VERSION "HNNBNNNYNNNNNNNNNNNNNNNNNNNNNNNNNNNNNNNNNN/4/%%%/4/'%**4NNN///"

NS_ :

BS_:

BU_: BAP_Tester ELV Gateway_Max HUD Kombi

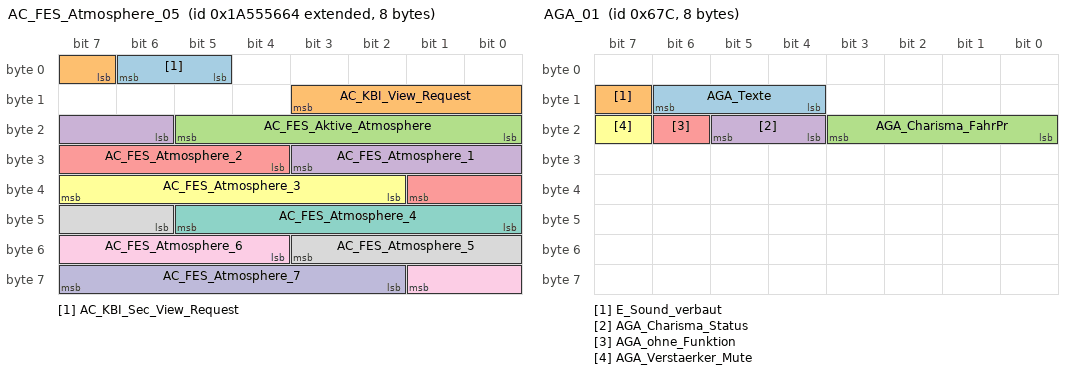
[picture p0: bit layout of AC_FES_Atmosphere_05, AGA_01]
BO_ 2589283940 AC_FES_Atmosphere_05: 8 Gateway_Max
 SG_ AC_KBI_Sec_View_Request : 5|2@1+ (1.0,0.0) [0.0|3] ""  Kombi
 SG_ AC_KBI_View_Request : 7|5@1+ (1.0,0.0) [0.0|31] ""  Kombi
 SG_ AC_FES_Aktive_Atmosphere : 16|6@1+ (1.0,0.0) [0.0|63] ""  Vector__XXX
 SG_ AC_FES_Atmosphere_1 : 22|6@1+ (1.0,0.0) [0.0|63] ""  Vector__XXX
 SG_ AC_FES_Atmosphere_2 : 28|6@1+ (1.0,0.0) [0.0|63] ""  Vector__XXX
 SG_ AC_FES_Atmosphere_3 : 34|6@1+ (1.0,0.0) [0.0|63] ""  Vector__XXX
 SG_ AC_FES_Atmosphere_4 : 40|6@1+ (1.0,0.0) [0.0|63] ""  Vector__XXX
 SG_ AC_FES_Atmosphere_5 : 46|6@1+ (1.0,0.0) [0.0|63] ""  Vector__XXX
 SG_ AC_FES_Atmosphere_6 : 52|6@1+ (1.0,0.0) [0.0|63] ""  Vector__XXX
 SG_ AC_FES_Atmosphere_7 : 58|6@1+ (1.0,0.0) [0.0|63] ""  Vector__XXX

BO_ 768 ACC_19: 48 Gateway_Max
 SG_ ACC_FzgStatus_Kamerafusion : 54|2@1+ (1.0,0.0) [0.0|3] ""  Kombi
 SG_ ACC_FzgStatus_Anfahrbereitschaft : 56|2@1+ (1.0,0.0) [0.0|3] ""  Kombi
 SG_ ACC_FzgStatus_Fehleranzeige : 58|3@1+ (1.0,0.0) [0.0|7] ""  Kombi
 SG_ ACC_ENG_Texte_02 : 61|3@1+ (1.0,0.0) [0.0|7] ""  Kombi
 SG_ ACC_Tempolimit : 64|5@1+ (1.0,0.0) [0.0|31] ""  HUD,Kombi
 SG_ ACC_Wunschgeschw_Farbe : 69|1@1+ (1.0,0.0) [0.0|1] ""  Vector__XXX
 SG_ ACC_Warnung_Verkehrszeichen_1 : 70|1@1+ (1.0,0.0) [0.0|1] ""  HUD,Kombi
 SG_ ACA_Querfuehrung : 71|2@1+ (1.0,0.0) [0.0|3] ""  HUD,Kombi
 SG_ ACC_Wunschgeschw_Farbe_02 : 73|2@1+ (1.0,0.0) [0.0|3] ""  Kombi
 SG_ ACC_Regelung_AIO : 75|1@1+ (1.0,0.0) [0.0|1] ""  Vector__XXX
 SG_ ACC_Wunschgeschw_02 : 76|10@1+ (0.32,0) [0.00|327.04] "Unit_KiloMeterPerHour"  HUD,Kombi
 SG_ ACC_Abstandsindex_02 : 86|10@1+ (1,0) [1|1021] ""  HUD,Kombi
 SG_ ACC_Display_Prio : 96|2@1+ (1.0,0.0) [0.0|3] ""  Kombi
 SG_ ACC_rel_Objekt_Zusatzanz : 98|2@1+ (1.0,0.0) [0.0|3] ""  Kombi
 SG_ ACC_Gesetzte_Zeitluecke : 101|3@1+ (1.0,0.0) [0.0|7] ""  HUD,Kombi
 SG_ ACC_Optischer_Fahrerhinweis : 104|1@1+ (1.0,0.0) [0.0|1] ""  HUD,Kombi
 SG_ ACC_Warnhinweis : 105|1@1+ (1.0,0.0) [0.0|1] ""  HUD,Kombi
 SG_ ACC_EGO_Fahrzeug : 106|3@1+ (1.0,0.0) [0.0|7] ""  HUD,Kombi
 SG_ ACC_Relevantes_Objekt_02 : 109|2@1+ (1.0,0.0) [0.0|3] ""  HUD,Kombi
 SG_ ACC_Wunschgeschw_erreicht : 112|1@1+ (1.0,0.0) [0.0|1] ""  Vector__XXX
 SG_ ACC_Anzeige_Zeitluecke : 113|1@1+ (1.0,0.0) [0.0|1] ""  HUD,Kombi
 SG_ ACC_Texte_Primaeranz_03 : 114|6@1+ (1.0,0.0) [0.0|63] ""  HUD,Kombi
 SG_ ACC_Texte_Zusatzanz_03 : 120|6@1+ (1.0,0.0) [0.0|63] ""  HUD,Kombi
 SG_ STA_Primaeranz : 126|2@1+ (1.0,0.0) [0.0|3] ""  Vector__XXX
 SG_ ACC_Regelgeschw : 140|10@1+ (0.32,0) [0.00|327.04] "Unit_KiloMeterPerHour"  HUD,Kombi
 SG_ ACC_Einheit_maxSetzgeschw : 150|1@1+ (1.0,0.0) [0.0|1] ""  Kombi
 SG_ ACC_maxSetzgeschw : 151|9@1+ (1,0) [0|510] ""  Kombi
 SG_ ACC_minRegelgeschw : 160|8@1+ (0.32,0) [0.00|81.28] "Unit_KiloMeterPerHour"  Vector__XXX
 SG_ ACC_maxRegelgeschw : 168|8@1+ (0.32,0) [0.00|81.28] "Unit_KiloMeterPerHour"  Vector__XXX
 SG_ ACC_Tempolimitassistent_02 : 176|3@1+ (1.0,0.0) [0.0|7] ""  Vector__XXX
 SG_ ACC_Tempolimit_Einheit : 179|1@1+ (1.0,0.0) [0.0|1] ""  Kombi
 SG_ ACC_Kurvenassistent : 180|3@1+ (1.0,0.0) [0.0|7] ""  Vector__XXX
 SG_ ACC_Typ_Tachokranz : 183|1@1+ (1.0,0.0) [0.0|1] ""  Vector__XXX
 SG_ ACC_RUV : 184|2@1+ (1.0,0.0) [0.0|3] ""  HUD,Kombi
 SG_ ACC_Tachokranz : 186|1@1+ (1.0,0.0) [0.0|1] ""  Kombi
 SG_ ACC_Typ_Tachokranz_unten : 187|1@1+ (1.0,0.0) [0.0|1] ""  Kombi
 SG_ ACC_ENG_Texte : 188|2@1+ (1.0,0.0) [0.0|3] ""  Kombi
 SG_ ACC_Status_GRA_Modus : 190|2@1+ (1.0,0.0) [0.0|3] ""  HUD,Kombi
 SG_ ACA_Querfuehrung_Texte : 192|3@1+ (1.0,0.0) [0.0|7] ""  Kombi
 SG_ ACA_Hinweistexte : 195|3@1+ (1.0,0.0) [0.0|7] ""  Vector__XXX
 SG_ ACC_FoD_Status : 198|2@1+ (1.0,0.0) [0.0|3] ""  HUD,Kombi
 SG_ ACC_Texte_Abstandswarner : 200|2@1+ (1.0,0.0) [0.0|3] ""  Vector__XXX
 SG_ ACC_Vorz_Abstandswarner : 202|2@1+ (1.0,0.0) [0.0|3] ""  Vector__XXX
 SG_ ACC_Texte_Sekundaeranz : 204|4@1+ (1.0,0.0) [0.0|15] ""  Vector__XXX
 SG_ ACC_Status_Anzeige : 208|3@1+ (1.0,0.0) [0.0|7] ""  HUD,Kombi
 SG_ ACC_Akustik_03 : 211|3@1+ (1.0,0.0) [0.0|7] ""  Kombi
 SG_ ACC_Geschw_Zielfahrzeug : 214|10@1+ (0.32,0) [0.00|326.72] "Unit_KiloMeterPerHour"  Vector__XXX
 SG_ ACC_Texte_02 : 224|6@1+ (1.0,0.0) [0.0|63] ""  Kombi
 SG_ ACC_STA_Text : 230|1@1+ (1.0,0.0) [0.0|1] ""  Vector__XXX
 SG_ ACC_Status_Stauende : 231|1@1+ (1.0,0.0) [0.0|1] ""  Vector__XXX
 SG_ STA_Texte : 232|3@1+ (1.0,0.0) [0.0|7] ""  Vector__XXX
 SG_ AbstWarn_LRR_FAS_Fkt_Status : 235|2@1+ (1.0,0.0) [0.0|3] ""  Vector__XXX
 SG_ STA_Zusatzanz : 237|2@1+ (1.0,0.0) [0.0|3] ""  Vector__XXX
 SG_ FAS_Licht_Anf : 239|1@1+ (1.0,0.0) [0.0|1] ""  Vector__XXX
 SG_ ACC_Zeitluecke_Abstandswarner : 240|6@1+ (0.1,0) [0.0|6.0] "Unit_Secon"  Vector__XXX
 SG_ ACC_Abstand_Abstandswarner : 246|9@1+ (1,0) [0|508] ""  Vector__XXX
 SG_ ACC_Einheit_Abstandswarner : 255|1@1+ (1.0,0.0) [0.0|1] ""  Vector__XXX
 SG_ ACC_Texte_Sekundaeranz_03 : 256|5@1+ (1.0,0.0) [0.0|31] ""  HUD,Kombi
 SG_ ACC_Modus_Pop_Up : 262|3@1+ (1.0,0.0) [0.0|7] ""  Kombi
 SG_ ACC_Statusicon : 265|4@1+ (1.0,0.0) [0.0|15] ""  HUD,Kombi
 SG_ ACC_Anzeige_Objektregelung : 269|5@1+ (1.0,0.0) [0.0|31] ""  HUD,Kombi
 SG_ ACC_Anzeige_Maximalabstand : 274|7@1+ (2,0) [0|254] "Unit_Meter"  Kombi
 SG_ ACC_Typ_LNS : 281|3@1+ (1.0,0.0) [0.0|7] ""  HUD,Kombi
 SG_ ACC_Typ_RNS : 284|3@1+ (1.0,0.0) [0.0|7] ""  HUD,Kombi
 SG_ ACC_Typ_WZO : 287|3@1+ (1.0,0.0) [0.0|7] ""  HUD,Kombi
 SG_ ACC_Abstand_WZO : 290|10@1+ (0.2,0) [0.2|204.6] "Unit_Meter"  Kombi
 SG_ ACC_Abstand_RNS : 300|10@1+ (0.2,0) [0.2|204.6] "Unit_Meter"  Kombi
 SG_ ACC_Abstand_LNS : 310|10@1+ (0.2,0) [0.2|204.6] "Unit_Meter"  Kombi
 SG_ ACC_Texte_03 : 320|7@1+ (1.0,0.0) [0.0|127] ""  Kombi
 SG_ ACC_iBoost_Anzeige : 327|2@1+ (1.0,0.0) [0.0|3] ""  HUD,Kombi
 SG_ ACC_Texte_Sekundaeranz_02 : 329|5@1+ (1.0,0.0) [0.0|31] ""  Kombi
 SG_ ACC_Sollabstand_1 : 334|10@1+ (0.2,0) [0.2|204.6] "Unit_Meter"  Kombi
 SG_ ACC_Sollabstand_2 : 344|10@1+ (0.2,0) [0.2|204.6] "Unit_Meter"  Kombi
 SG_ ACC_Sollabstand_3 : 354|10@1+ (0.2,0) [0.2|204.6] "Unit_Meter"  Kombi
 SG_ ACC_Sollabstand_4 : 364|10@1+ (0.2,0) [0.2|204.6] "Unit_Meter"  Kombi
 SG_ ACC_Sollabstand_5 : 374|10@1+ (0.2,0) [0.2|204.6] "Unit_Meter"  Kombi

BO_ 859 ACC_Obj_01: 64 Gateway_Max
 SG_ ACC_Obj_01_ID : 12|8@1+ (1,0) [1|254] "Unit_None"  Vector__XXX
 SG_ ACC_Obj_01_ax_StdA : 20|6@1+ (0.125,0) [0.000|7.750] "Unit_MeterPerSeconSquar"  Vector__XXX
 SG_ ACC_Obj_01_ax_v : 26|8@1+ (0.125,-16) [-16.000|15.750] "Unit_MeterPerSeconSquar"  Vector__XXX
 SG_ ACC_Obj_01_dx_StdA : 34|7@1+ (0.0625,0) [0.0000|7.8750] "Unit_Meter"  Vector__XXX
 SG_ ACC_Obj_01_dx_v : 41|12@1+ (0.0625,0) [0.0000|255.8750] "Unit_Meter"  HUD
 SG_ ACC_Obj_01_dy_StdA : 53|7@1+ (0.0625,0) [0.0000|7.8750] "Unit_Meter"  Vector__XXX
 SG_ ACC_Obj_01_dy_v : 60|11@1+ (0.0625,-64) [-64.0000|63.8750] "Unit_Meter"  HUD
 SG_ ACC_Obj_01_vx_StdA : 71|5@1+ (0.25,0) [0.00|7.50] "Unit_MeterPerSecon"  Vector__XXX
 SG_ ACC_Obj_01_vx_v : 76|10@1+ (0.25,-128) [-128.00|127.50] "Unit_MeterPerSecon"  HUD
 SG_ ACC_Obj_01_Bew_Zustand : 86|2@1+ (1.0,0.0) [0.0|3] ""  Vector__XXX
 SG_ ACC_Obj_01_Fusion_ID_VD : 88|32@1+ (1,0) [1|4294967294] "Unit_Ohm"  Vector__XXX
 SG_ ACC_Obj_01_Fusion_ID_FER_VR : 120|8@1+ (1,0) [1|254] "Unit_None"  Vector__XXX
 SG_ ACC_Obj_01_Fusion_ID_FER_VL : 128|8@1+ (1,0) [1|254] "Unit_None"  Vector__XXX
 SG_ ACC_Obj_01_Alter : 136|12@1+ (1,0) [0|4094] "Unit_None"  Vector__XXX
 SG_ ACC_Obj_01_vxAbs_v : 148|12@1+ (0.0625,-128) [-128.0000|127.8750] "Unit_MeterPerSecon"  Vector__XXX
 SG_ ACC_Obj_01_vyAbs_v : 160|12@1+ (0.0625,-128) [-128.0000|127.8750] "Unit_MeterPerSecon"  Vector__XXX
 SG_ ACC_Obj_01_Bezugspunkt : 172|4@1+ (1.0,0.0) [0.0|15] ""  Vector__XXX
 SG_ ACC_Obj_01_Breite : 176|7@1+ (0.0625,0) [0.0000|7.8750] "Unit_Meter"  Vector__XXX
 SG_ ACC_Obj_01_SDFInfo_FER_VL : 183|1@1+ (1.0,0.0) [0.0|1] ""  Vector__XXX
 SG_ ACC_Obj_01_BreiteStdA : 184|7@1+ (0.0625,0) [0.0000|7.8750] "Unit_Meter"  Vector__XXX
 SG_ ACC_Obj_01_SDFInfo_FER_VR : 191|1@1+ (1.0,0.0) [0.0|1] ""  Vector__XXX
 SG_ ACC_Obj_01_Historie : 192|1@1+ (1.0,0.0) [0.0|1] ""  Vector__XXX
 SG_ ACC_Obj_01_SDFInfo_FR : 193|1@1+ (1.0,0.0) [0.0|1] ""  Vector__XXX
 SG_ ACC_Obj_01_SDFInfo_Kamera : 194|1@1+ (1.0,0.0) [0.0|1] ""  Vector__XXX
 SG_ ACC_Obj_01_vy_StdA : 195|5@1+ (0.25,0) [0.00|7.50] "Unit_MeterPerSecon"  Vector__XXX
 SG_ ACC_Obj_01_dz_v : 200|9@1+ (0.0625,-16) [-16.0000|15.8750] "Unit_Meter"  Vector__XXX
 SG_ ACC_Obj_01_dz_StdA : 209|7@1+ (0.0625,0) [0.0000|7.8750] "Unit_Meter"  Vector__XXX
 SG_ ACC_Obj_01_Laenge : 216|9@1+ (0.0625,0) [0.0000|31.8750] "Unit_Meter"  Vector__XXX
 SG_ ACC_Obj_01_LaengeStdA : 225|7@1+ (0.0625,0) [0.0000|7.8750] "Unit_Meter"  Vector__XXX
 SG_ ACC_Obj_01_GierWnkl : 232|9@1+ (0.0125,-3.2) [-3.2000|3.1750] "Unit_Radia"  Vector__XXX
 SG_ ACC_Obj_01_ExistenzMass : 241|7@1+ (0.0078125,0.015625) [0.0156250|1.0000000] "Unit_None"  Vector__XXX
 SG_ ACC_Obj_01_axAbs_v : 248|8@1+ (0.125,-16) [-16.000|15.750] "Unit_MeterPerSeconSquar"  Vector__XXX
 SG_ ACC_Obj_01_ay_v : 256|8@1+ (0.125,-16) [-16.000|15.750] "Unit_MeterPerSeconSquar"  Vector__XXX
 SG_ ACC_Obj_01_vy_v : 264|8@1+ (0.25,-32) [-32.00|31.50] "Unit_MeterPerSecon"  Vector__XXX
 SG_ ACC_Obj_01_Klasse : 272|4@1+ (1.0,0.0) [0.0|15] ""  Vector__XXX
 SG_ ACC_Obj_01_KlassePlausib : 276|4@1+ (0.071429,0) [0.000000|1.000006] "Unit_None"  Vector__XXX
 SG_ ACC_Obj_01_Gemessen : 280|2@1+ (1.0,0.0) [0.0|3] ""  Vector__XXX
 SG_ ACC_Obj_01_Hoehe : 282|6@1+ (0.0625,0) [0.0000|3.8750] "Unit_Meter"  Vector__XXX
 SG_ ACC_Obj_01_HoeheStdA : 288|6@1+ (0.0625,0) [0.0000|3.8750] "Unit_Meter"  Vector__XXX
 SG_ ACC_Obj_01_vxAbs_StdA : 294|6@1+ (0.0625,0) [0.0000|3.8750] "Unit_MeterPerSecon"  Vector__XXX
 SG_ ACC_Obj_01_vyAbs_StdA : 300|6@1+ (0.0625,0) [0.0000|3.8750] "Unit_MeterPerSecon"  Vector__XXX
 SG_ ACC_Obj_01_axAbs_StdA : 306|6@1+ (0.125,0) [0.000|7.750] "Unit_MeterPerSeconSquar"  Vector__XXX
 SG_ ACC_Obj_01_ay_StdA : 312|6@1+ (0.125,0) [0.000|7.750] "Unit_MeterPerSeconSquar"  Vector__XXX
 SG_ ACC_Obj_01_GierWnklStdA : 318|6@1+ (0.0625,0) [0.0000|3.8750] "Unit_Radia"  Vector__XXX
 SG_ ACC_Obj_01_Anzeige_Rel : 324|2@1+ (1.0,0.0) [0.0|3] ""  Vector__XXX
 SG_ ACC_Obj_01_LaengsRegelung : 326|1@1+ (1.0,0.0) [0.0|1] ""  Vector__XXX

BO_ 2331595990 ACC_Obj_02: 64 Gateway_Max
 SG_ ACC_Obj_02_ID : 12|8@1+ (1,0) [1|254] "Unit_None"  Vector__XXX
 SG_ ACC_Obj_02_ax_StdA : 20|6@1+ (0.125,0) [0.000|7.750] "Unit_MeterPerSeconSquar"  Vector__XXX
 SG_ ACC_Obj_02_ax_v : 26|8@1+ (0.125,-16) [-16.000|15.750] "Unit_MeterPerSeconSquar"  Vector__XXX
 SG_ ACC_Obj_02_dx_v : 41|12@1+ (0.0625,0) [0.0000|255.8750] "Unit_Meter"  HUD
 SG_ ACC_Obj_02_dy_v : 60|11@1+ (0.0625,-64) [-64.0000|63.8750] "Unit_Meter"  HUD
 SG_ ACC_Obj_02_vx_v : 76|10@1+ (0.25,-128) [-128.00|127.50] "Unit_MeterPerSecon"  HUD
 SG_ ACC_Obj_02_Fusion_ID_VD : 88|32@1+ (1,0) [1|4294967294] "Unit_None"  Vector__XXX
 SG_ ACC_Obj_02_Fusion_ID_FER_VR : 120|8@1+ (1,0) [1|254] "Unit_None"  Vector__XXX
 SG_ ACC_Obj_02_Fusion_ID_FER_VL : 128|8@1+ (1,0) [1|254] "Unit_None"  Vector__XXX
 SG_ ACC_Obj_02_Alter : 136|12@1+ (1,0) [0|4094] "Unit_None"  Vector__XXX
 SG_ ACC_Obj_02_vxAbs_v : 148|12@1+ (0.0625,-128) [-128.0000|127.8750] "Unit_MeterPerSecon"  Vector__XXX
 SG_ ACC_Obj_02_vyAbs_v : 160|12@1+ (0.0625,-128) [-128.0000|127.8750] "Unit_MeterPerSecon"  Vector__XXX
 SG_ ACC_Obj_02_Bezugspunkt : 172|4@1+ (1.0,0.0) [0.0|15] ""  Vector__XXX
 SG_ ACC_Obj_02_Breite : 176|7@1+ (0.0625,0) [0.0000|7.8750] "Unit_Meter"  Vector__XXX
 SG_ ACC_Obj_02_SDFInfo_FER_VL : 183|1@1+ (1.0,0.0) [0.0|1] ""  Vector__XXX
 SG_ ACC_Obj_02_BreiteStdA : 184|7@1+ (0.0625,0) [0.0000|7.8750] "Unit_Meter"  Vector__XXX
 SG_ ACC_Obj_02_SDFInfo_FER_VR : 191|1@1+ (1.0,0.0) [0.0|1] ""  Vector__XXX
 SG_ ACC_Obj_02_Historie : 192|1@1+ (1.0,0.0) [0.0|1] ""  Vector__XXX
 SG_ ACC_Obj_02_SDFInfo_FR : 193|1@1+ (1.0,0.0) [0.0|1] ""  Vector__XXX
 SG_ ACC_Obj_02_dz_v : 200|9@1+ (0.0625,-16) [-16.0000|15.8750] "Unit_Meter"  Vector__XXX
 SG_ ACC_Obj_02_Laenge : 216|9@1+ (0.0625,0) [0.0000|31.8750] "Unit_Meter"  Vector__XXX
 SG_ ACC_Obj_02_LaengeStdA : 225|7@1+ (0.0625,0) [0.0000|7.8750] "Unit_Meter"  Vector__XXX
 SG_ ACC_Obj_02_GierWnkl : 232|9@1+ (0.0125,-3.2) [-3.2000|3.1750] "Unit_Radia"  Vector__XXX
 SG_ ACC_Obj_02_ExistenzMass : 241|7@1+ (0.0078125,0.015625) [0.0156250|1.0000000] "Unit_None"  Vector__XXX
 SG_ ACC_Obj_02_ay_v : 256|8@1+ (0.125,-16) [-16.000|15.750] "Unit_MeterPerSeconSquar"  Vector__XXX
 SG_ ACC_Obj_02_vy_v : 264|8@1+ (0.25,-32) [-32.00|31.50] "Unit_MeterPerSecon"  Vector__XXX
 SG_ ACC_Obj_02_Gemessen : 280|2@1+ (1.0,0.0) [0.0|3] ""  Vector__XXX
 SG_ ACC_Obj_02_Hoehe : 282|6@1+ (0.0625,0) [0.0000|3.8750] "Unit_Meter"  Vector__XXX
 SG_ ACC_Obj_02_HoeheStdA : 288|6@1+ (0.0625,0) [0.0000|3.8750] "Unit_Meter"  Vector__XXX
 SG_ ACC_Obj_02_vxAbs_StdA : 294|6@1+ (0.0625,0) [0.0000|3.8750] "Unit_MeterPerSecon"  Vector__XXX
 SG_ ACC_Obj_02_vyAbs_StdA : 300|6@1+ (0.0625,0) [0.0000|3.8750] "Unit_MeterPerSecon"  Vector__XXX
 SG_ ACC_Obj_02_ay_StdA : 312|6@1+ (0.125,0) [0.000|7.750] "Unit_MeterPerSeconSquar"  Vector__XXX
 SG_ ACC_Obj_02_GierWnklStdA : 318|6@1+ (0.0625,0) [0.0000|3.8750] "Unit_Radia"  Vector__XXX
 SG_ ACC_Obj_02_Anzeige_Rel : 324|2@1+ (1.0,0.0) [0.0|3] ""  Vector__XXX
 SG_ ACC_Obj_02_LaengsRegelung : 326|1@1+ (1.0,0.0) [0.0|1] ""  Vector__XXX

BO_ 2331596021 ACC_Obj_05: 64 Gateway_Max
 SG_ ACC_Obj_05_ID : 12|8@1+ (1,0) [1|254] "Unit_None"  Vector__XXX
 SG_ ACC_Obj_05_ax_StdA : 20|6@1+ (1.0,0.0) [0.0|63] ""  Vector__XXX
 SG_ ACC_Obj_05_ax_v : 26|8@1+ (1.0,0.0) [0.0|255] ""  Vector__XXX
 SG_ ACC_Obj_05_dx_StdA : 34|7@1+ (1.0,0.0) [0.0|127] ""  Vector__XXX
 SG_ ACC_Obj_05_dx_v : 41|12@1+ (0.0625,0) [0.0000|255.8750] "Unit_Meter"  HUD
 SG_ ACC_Obj_05_dy_StdA : 53|7@1+ (1.0,0.0) [0.0|127] ""  Vector__XXX
 SG_ ACC_Obj_05_dy_v : 60|11@1+ (0.0625,-64) [-64.0000|63.8750] "Unit_Meter"  HUD
 SG_ ACC_Obj_05_vx_StdA : 71|5@1+ (0.25,0) [0.00|7.50] ""  Vector__XXX
 SG_ ACC_Obj_05_vx_v : 76|10@1+ (0.25,-128) [-128.00|127.50] "Unit_MeterPerSecon"  HUD
 SG_ ACC_Obj_05_Bew_Zustand : 86|2@1+ (1.0,0.0) [0.0|3] ""  Vector__XXX
 SG_ ACC_Obj_05_Fusion_ID_VD : 88|32@1+ (1.0,0.0) [0.0|4294967295] ""  Vector__XXX
 SG_ ACC_Obj_05_Fusion_ID_FER_VR : 120|8@1+ (1.0,0.0) [0.0|255] ""  Vector__XXX
 SG_ ACC_Obj_05_Fusion_ID_FER_VL : 128|8@1+ (1.0,0.0) [0.0|255] ""  Vector__XXX
 SG_ ACC_Obj_05_Alter : 136|12@1+ (1.0,0.0) [0.0|4095] ""  Vector__XXX
 SG_ ACC_Obj_05_vxAbs_v : 148|12@1+ (1.0,0.0) [0.0|4095] ""  Vector__XXX
 SG_ ACC_Obj_05_vyAbs_v : 160|12@1+ (1.0,0.0) [0.0|4095] ""  Vector__XXX
 SG_ ACC_Obj_05_Breite : 176|7@1+ (1.0,0.0) [0.0|127] ""  Vector__XXX
 SG_ ACC_Obj_05_SDFInfo_FER_VL : 183|1@1+ (1.0,0.0) [0.0|1] ""  Vector__XXX
 SG_ ACC_Obj_05_BreiteStdA : 184|7@1+ (1.0,0.0) [0.0|127] ""  Vector__XXX
 SG_ ACC_Obj_05_SDFInfo_FER_VR : 191|1@1+ (1.0,0.0) [0.0|1] ""  Vector__XXX
 SG_ ACC_Obj_05_Historie : 192|1@1+ (1.0,0.0) [0.0|1] ""  Vector__XXX
 SG_ ACC_Obj_05_SDFInfo_FR : 193|1@1+ (1.0,0.0) [0.0|1] ""  Vector__XXX
 SG_ ACC_Obj_05_SDFInfo_Kamera : 194|1@1+ (1.0,0.0) [0.0|1] ""  Vector__XXX
 SG_ ACC_Obj_05_vy_StdA : 195|5@1+ (0.25,0) [0.00|7.50] ""  Vector__XXX
 SG_ ACC_Obj_05_dz_v : 200|9@1+ (1.0,0.0) [0.0|511] ""  Vector__XXX
 SG_ ACC_Obj_05_dz_StdA : 209|7@1+ (1.0,0.0) [0.0|127] ""  Vector__XXX
 SG_ ACC_Obj_05_Laenge : 216|9@1+ (1.0,0.0) [0.0|511] ""  Vector__XXX
 SG_ ACC_Obj_05_LaengeStdA : 225|7@1+ (1.0,0.0) [0.0|127] ""  Vector__XXX
 SG_ ACC_Obj_05_GierWnkl : 232|9@1+ (1.0,0.0) [0.0|511] ""  Vector__XXX
 SG_ ACC_Obj_05_ExistenzMass : 241|7@1+ (1.0,0.0) [0.0|127] ""  Vector__XXX
 SG_ ACC_Obj_05_axAbs_v : 248|8@1+ (1.0,0.0) [0.0|255] ""  Vector__XXX
 SG_ ACC_Obj_05_ay_v : 256|8@1+ (1.0,0.0) [0.0|255] ""  Vector__XXX
 SG_ ACC_Obj_05_vy_v : 264|8@1+ (0.25,-32) [-32.00|31.50] "Unit_MeterPerSecon"  Vector__XXX
 SG_ ACC_Obj_05_Klasse : 272|4@1+ (1.0,0.0) [0.0|15] ""  Vector__XXX
 SG_ ACC_Obj_05_KlassePlausib : 276|4@1+ (0.071429,0) [0.000000|1.000006] ""  Vector__XXX
 SG_ ACC_Obj_05_Gemessen : 280|2@1+ (1.0,0.0) [0.0|3] ""  Vector__XXX
 SG_ ACC_Obj_05_Hoehe : 282|6@1+ (1.0,0.0) [0.0|63] ""  Vector__XXX
 SG_ ACC_Obj_05_HoeheStdA : 288|6@1+ (1.0,0.0) [0.0|63] ""  Vector__XXX
 SG_ ACC_Obj_05_vxAbs_StdA : 294|6@1+ (1.0,0.0) [0.0|63] ""  Vector__XXX
 SG_ ACC_Obj_05_vyAbs_StdA : 300|6@1+ (1.0,0.0) [0.0|63] ""  Vector__XXX
 SG_ ACC_Obj_05_axAbs_StdA : 306|6@1+ (1.0,0.0) [0.0|63] ""  Vector__XXX
 SG_ ACC_Obj_05_ay_StdA : 312|6@1+ (1.0,0.0) [0.0|63] ""  Vector__XXX
 SG_ ACC_Obj_05_GierWnklStdA : 318|6@1+ (1.0,0.0) [0.0|63] ""  Vector__XXX
 SG_ ACC_Obj_05_Anzeige_Rel : 324|2@1+ (1.0,0.0) [0.0|3] ""  Vector__XXX
 SG_ ACC_Obj_05_LaengsRegelung : 326|1@1+ (1.0,0.0) [0.0|1] ""  Vector__XXX

BO_ 2527679923 ADA_01: 16 Gateway_Max
 SG_ ADA_DistractionLevel : 12|7@1+ (0.01,0) [0.00|1.00] "Unit_None"  Vector__XXX
 SG_ ADA_DrowsinessLevel : 19|7@1+ (0.01,0) [0.00|1.00] "Unit_None"  Vector__XXX
 SG_ ADA_AttentionLevel : 26|7@1+ (0.01,0) [0.00|1.00] "Unit_None"  Vector__XXX
 SG_ ADA_DriverIsOperating : 33|2@1+ (1.0,0.0) [0.0|3] ""  Vector__XXX
 SG_ ADA_HMI_Ablenkung_Deaktivierung : 35|1@1+ (1.0,0.0) [0.0|1] ""  Kombi
 SG_ ADA_HMI_Ablenkung_Fehler_Popup : 36|2@1+ (1.0,0.0) [0.0|3] ""  Kombi
 SG_ ADA_HMI_Ablenkung_Meldeakustik : 38|1@1+ (1.0,0.0) [0.0|1] ""  Kombi
 SG_ ADA_HMI_Ablenkung_Meldung : 39|2@1+ (1.0,0.0) [0.0|3] ""  Kombi
 SG_ ADA_HMI_Fahrzeit_seit_Pause : 41|10@1+ (1,0) [0|1022] "Unit_Minut"  Kombi
 SG_ ADA_HMI_Muedigkeit_Deaktivierung : 51|1@1+ (1.0,0.0) [0.0|1] ""  Kombi
 SG_ ADA_HMI_Muedigkeit_Fehler_Popup : 52|2@1+ (1.0,0.0) [0.0|3] ""  Kombi
 SG_ ADA_HMI_Muedigkeit_Meldeakustik : 54|1@1+ (1.0,0.0) [0.0|1] ""  Kombi
 SG_ ADA_HMI_Muedigkeit_Meldung : 55|3@1+ (1.0,0.0) [0.0|7] ""  Kombi
 SG_ ADA_HMI_Muedigkeit_Event_Meldung : 58|2@1+ (1.0,0.0) [0.0|3] ""  Kombi
 SG_ ADA_DrowsinessSystemState : 60|3@1+ (1.0,0.0) [0.0|7] ""  Kombi
 SG_ ADA_Microsleep : 63|3@1+ (1.0,0.0) [0.0|7] ""  Vector__XXX
 SG_ ADA_TriggerEmergencyAssist : 66|3@1+ (1.0,0.0) [0.0|7] ""  Vector__XXX
 SG_ ADA_Upcoming_Microsleep : 69|1@1+ (1.0,0.0) [0.0|1] ""  Vector__XXX
 SG_ SOK_ADA_01_Signatur : 96|32@1+ (1,0) [0|4294967295] ""  Vector__XXX

BO_ 1660 AGA_01: 8 Gateway_Max
 SG_ AGA_Texte : 12|3@1+ (1.0,0.0) [0.0|7] ""  Kombi
 SG_ E_Sound_verbaut : 15|1@1+ (1.0,0.0) [0.0|1] ""  Vector__XXX
 SG_ AGA_Charisma_FahrPr : 16|4@1+ (1.0,0.0) [0.0|15] ""  Vector__XXX
 SG_ AGA_Charisma_Status : 20|2@1+ (1.0,0.0) [0.0|3] ""  Vector__XXX
 SG_ AGA_ohne_Funktion : 22|1@1+ (1.0,0.0) [0.0|1] ""  Kombi
 SG_ AGA_Verstaerker_Mute : 23|1@1+ (1.0,0.0) [0.0|1] ""  Vector__XXX

BO_ 64 Airbag_01: 8 Gateway_Max
 SG_ Airbag_01_CRC : 0|8@1+ (1,0) [0|255] ""  Kombi
 SG_ Airbag_01_BZ : 8|4@1+ (1,0) [0|15] ""  Kombi
 SG_ AB_RGS_Anst : 12|4@1+ (1.0,0.0) [0.0|15] ""  Vector__XXX
 SG_ AB_Front_Crash : 16|1@1+ (1.0,0.0) [0.0|1] ""  Vector__XXX
 SG_ AB_Heck_Crash : 17|1@1+ (1.0,0.0) [0.0|1] ""  Vector__XXX
 SG_ AB_SF_Crash : 18|1@1+ (1.0,0.0) [0.0|1] ""  Vector__XXX
 SG_ AB_SB_Crash : 19|1@1+ (1.0,0.0) [0.0|1] ""  Vector__XXX
 SG_ AB_Rollover_Crash : 20|1@1+ (1.0,0.0) [0.0|1] ""  Vector__XXX
 SG_ AB_Crash_Int : 21|3@1+ (1.0,0.0) [0.0|7] ""  Vector__XXX
 SG_ AB_Lampe : 24|1@1+ (1.0,0.0) [0.0|1] ""  Kombi
 SG_ AB_Deaktiviert : 25|1@1+ (1.0,0.0) [0.0|1] ""  Kombi
 SG_ AB_VB_deaktiviert : 26|1@1+ (1.0,0.0) [0.0|1] ""  Vector__XXX
 SG_ AB_Systemfehler : 27|1@1+ (1.0,0.0) [0.0|1] ""  Kombi
 SG_ AB_Diagnose : 28|1@1+ (1.0,0.0) [0.0|1] ""  Vector__XXX
 SG_ AB_Stellgliedtest : 29|1@1+ (1.0,0.0) [0.0|1] ""  Vector__XXX
 SG_ AB_Erh_Auf_VB : 30|2@1+ (1.0,0.0) [0.0|3] ""  Kombi
 SG_ AB_Gurtwarn_VF : 32|1@1+ (1.0,0.0) [0.0|1] ""  Kombi
 SG_ AB_Gurtwarn_VB : 33|1@1+ (1.0,0.0) [0.0|1] ""  Kombi
 SG_ AB_Anzeige_Fussg : 34|2@1+ (1.0,0.0) [0.0|3] ""  Kombi
 SG_ AB_Texte_AKS : 36|2@1+ (1.0,0.0) [0.0|3] ""  Vector__XXX
 SG_ AB_PAO_Leuchte_Anf : 38|1@1+ (1.0,0.0) [0.0|1] ""  Vector__XXX
 SG_ AB_MKB_gueltig : 39|1@1+ (1.0,0.0) [0.0|1] ""  Vector__XXX
 SG_ AB_MKB_Anforderung : 40|1@1+ (1.0,0.0) [0.0|1] ""  Vector__XXX
 SG_ AB_Versorgungsspannung : 41|1@1+ (1.0,0.0) [0.0|1] ""  Kombi
 SG_ AB_Deaktivierung_HV : 42|3@1+ (1.0,0.0) [0.0|7] ""  Vector__XXX
 SG_ AB_EDR_Trigger : 45|2@1+ (1.0,0.0) [0.0|3] ""  Vector__XXX
 SG_ AB_Belegung_VF : 47|2@1+ (1.0,0.0) [0.0|3] ""  Kombi
 SG_ AB_Gurtschloss_FA_ext : 49|3@1+ (1.0,0.0) [0.0|7] ""  Vector__XXX
 SG_ AB_Gurtschloss_FA_ext_aktiv : 52|1@1+ (1.0,0.0) [0.0|1] ""  Vector__XXX
 SG_ AB_eCS_Error : 53|1@1+ (1.0,0.0) [0.0|1] ""  Kombi
 SG_ ASM_Masterzeit_02 : 56|8@1+ (0.04,0) [0.00|10.16] "Unit_Secon"  Vector__XXX

BO_ 1312 Airbag_02: 8 Gateway_Max
 SG_ Airbag_02_CRC : 0|8@1+ (1,0) [0|255] ""  Vector__XXX
 SG_ Airbag_02_BZ : 8|4@1+ (1,0) [0|15] ""  Vector__XXX
 SG_ LoGeWa_Event_Kombiwarnung : 12|4@1+ (1.0,0.0) [0.0|15] ""  Vector__XXX
 SG_ AB_Anforderung_eCall : 16|1@1+ (1.0,0.0) [0.0|1] ""  Vector__XXX
 SG_ AB_Anprall_Seite_Beifahrer : 17|1@1+ (1.0,0.0) [0.0|1] ""  Vector__XXX
 SG_ AB_Anprall_Rollover : 18|1@1+ (1.0,0.0) [0.0|1] ""  Vector__XXX
 SG_ AB_Anprall_FGS : 19|1@1+ (1.0,0.0) [0.0|1] ""  Vector__XXX
 SG_ AB_Anprall_Front_Beifahrer : 20|1@1+ (1.0,0.0) [0.0|1] ""  Vector__XXX
 SG_ AB_Anprall_Front_Fahrer : 21|1@1+ (1.0,0.0) [0.0|1] ""  Vector__XXX
 SG_ AB_Anprall_Heck_Beifahrer : 22|1@1+ (1.0,0.0) [0.0|1] ""  Vector__XXX
 SG_ AB_Anprall_Heck_Fahrer : 23|1@1+ (1.0,0.0) [0.0|1] ""  Vector__XXX
 SG_ AB_Wickelklappung_Reihe2_MI : 24|2@1+ (1.0,0.0) [0.0|3] ""  Vector__XXX
 SG_ AB_Belegung_VB : 26|2@1+ (1.0,0.0) [0.0|3] ""  Kombi
 SG_ AB_Abschaltanf_SIH_BF : 28|1@1+ (1.0,0.0) [0.0|1] ""  Vector__XXX
 SG_ AB_Anprall_Seite_Fahrer : 29|1@1+ (1.0,0.0) [0.0|1] ""  Vector__XXX
 SG_ SC_PAO_Schriftzug_Anf : 30|2@1+ (1.0,0.0) [0.0|3] ""  Vector__XXX
 SG_ SC_PAO_ON_Anf : 32|2@1+ (1.0,0.0) [0.0|3] ""  Vector__XXX
 SG_ SC_PAO_OFF_Anf : 34|2@1+ (1.0,0.0) [0.0|3] ""  Vector__XXX
 SG_ AB_Crashschwere : 36|3@1+ (1.0,0.0) [0.0|7] ""  Vector__XXX
 SG_ AB_Anforderung_USM : 39|1@1+ (1.0,0.0) [0.0|1] ""  Vector__XXX
 SG_ AB_Gurtschloss_FA : 40|2@1+ (1.0,0.0) [0.0|3] ""  Vector__XXX
 SG_ AB_Gurtschloss_BF : 42|2@1+ (1.0,0.0) [0.0|3] ""  Vector__XXX
 SG_ AB_Gurtschloss_Reihe2_FA : 44|2@1+ (1.0,0.0) [0.0|3] ""  Kombi
 SG_ AB_Gurtschloss_Reihe2_MI : 46|2@1+ (1.0,0.0) [0.0|3] ""  Kombi
 SG_ AB_Gurtschloss_Reihe2_BF : 48|2@1+ (1.0,0.0) [0.0|3] ""  Kombi
 SG_ AB_Gurtschloss_Reihe3_FA : 50|2@1+ (1.0,0.0) [0.0|3] ""  Kombi
 SG_ AB_Gurtschloss_Reihe3_MI : 52|2@1+ (1.0,0.0) [0.0|3] ""  Kombi
 SG_ AB_Gurtschloss_Reihe3_BF : 54|2@1+ (1.0,0.0) [0.0|3] ""  Kombi
 SG_ AB_Sitzpos_Sens_FA : 56|2@1+ (1.0,0.0) [0.0|3] ""  Vector__XXX
 SG_ AB_Sitzpos_Sens_BF : 58|2@1+ (1.0,0.0) [0.0|3] ""  Vector__XXX
 SG_ AB_Wickelklappung_Reihe2_BF : 60|2@1+ (1.0,0.0) [0.0|3] ""  Vector__XXX
 SG_ AB_Wickelklappung_Reihe2_FA : 62|2@1+ (1.0,0.0) [0.0|3] ""  Vector__XXX

BO_ 1349 Airbag_04: 8 Gateway_Max
 SG_ Airbag_04_CRC : 0|8@1+ (1,0) [0|255] ""  Vector__XXX
 SG_ Airbag_04_BZ : 8|4@1+ (1,0) [0|15] ""  Vector__XXX
 SG_ AB_Anprall_Front : 12|1@1+ (1.0,0.0) [0.0|1] ""  Vector__XXX
 SG_ AB_Anprall_Heck : 13|1@1+ (1.0,0.0) [0.0|1] ""  Vector__XXX
 SG_ AB_Gurtwarn_Reihe4_FA : 14|2@1+ (1.0,0.0) [0.0|3] ""  Kombi
 SG_ AB_Gurtwarn_Reihe4_BF : 16|2@1+ (1.0,0.0) [0.0|3] ""  Kombi
 SG_ AB_Gurtwarn_Reihe4_MI : 18|2@1+ (1.0,0.0) [0.0|3] ""  Kombi
 SG_ AB_Gurtwarn_Reihe2_FA : 20|2@1+ (1.0,0.0) [0.0|3] ""  Kombi
 SG_ AB_Gurtwarn_Reihe2_BF : 22|2@1+ (1.0,0.0) [0.0|3] ""  Kombi
 SG_ AbstWarn_MV_FAS_Fkt_Status : 24|2@1+ (1.0,0.0) [0.0|3] ""  Vector__XXX
 SG_ WarnBrems_Charisma_Status : 26|2@1+ (1.0,0.0) [0.0|3] ""  Vector__XXX
 SG_ WarnBrems_Charisma_FahrPr : 28|4@1+ (1.0,0.0) [0.0|15] ""  Vector__XXX
 SG_ AB_Gurtwarn_Reihe2_MI : 32|2@1+ (1.0,0.0) [0.0|3] ""  Kombi
 SG_ AB_Gurtwarn_Reihe3_FA : 34|2@1+ (1.0,0.0) [0.0|3] ""  Kombi
 SG_ AB_Gurtwarn_Reihe3_MI : 36|2@1+ (1.0,0.0) [0.0|3] ""  Kombi
 SG_ AB_Gurtwarn_Reihe3_BF : 38|2@1+ (1.0,0.0) [0.0|3] ""  Kombi
 SG_ LGI_FAS_Fkt_Status : 40|2@1+ (1.0,0.0) [0.0|3] ""  Vector__XXX
 SG_ PreCrash_FAS_Fkt_Status : 42|3@1+ (1.0,0.0) [0.0|7] ""  Vector__XXX
 SG_ AB_Belegung_VF_ext : 45|3@1+ (1.0,0.0) [0.0|7] ""  Vector__XXX
 SG_ AB_SBR_hinten_verbau : 48|2@1+ (1.0,0.0) [0.0|3] ""  Kombi
 SG_ AB_Belegung_VF_ext_aktiv : 50|1@1+ (1.0,0.0) [0.0|1] ""  Vector__XXX
 SG_ AWV_Einstellung_System_ASG : 51|1@1+ (1.0,0.0) [0.0|1] ""  Vector__XXX
 SG_ AWV_Einstellung_Warnung_ASG : 52|3@1+ (1.0,0.0) [0.0|7] ""  Vector__XXX
 SG_ SC_PreSense_Modus_Warnung_NV : 55|3@1+ (1.0,0.0) [0.0|7] ""  Vector__XXX
 SG_ SC_PreSense_Modus_Warnung_MV : 58|3@1+ (1.0,0.0) [0.0|7] ""  Vector__XXX
 SG_ SC_PreSense_Modus_System_MV : 61|1@1+ (1.0,0.0) [0.0|1] ""  Vector__XXX
 SG_ SC_PreSense_Modus_System_NV : 62|1@1+ (1.0,0.0) [0.0|1] ""  Vector__XXX
 SG_ SC_PreSense_Modus_System_KAS : 63|1@1+ (1.0,0.0) [0.0|1] ""  Vector__XXX

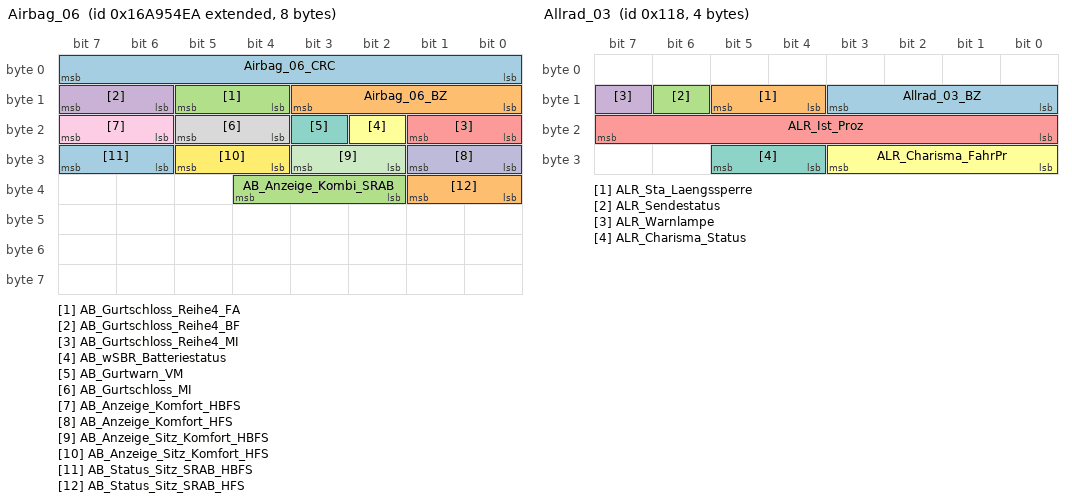
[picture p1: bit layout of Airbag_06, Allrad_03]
BO_ 2527679722 Airbag_06: 8 Gateway_Max
 SG_ Airbag_06_CRC : 0|8@1+ (1,0) [0|255] ""  Kombi
 SG_ Airbag_06_BZ : 8|4@1+ (1,0) [0|15] ""  Kombi
 SG_ AB_Gurtschloss_Reihe4_FA : 12|2@1+ (1.0,0.0) [0.0|3] ""  Kombi
 SG_ AB_Gurtschloss_Reihe4_BF : 14|2@1+ (1.0,0.0) [0.0|3] ""  Kombi
 SG_ AB_Gurtschloss_Reihe4_MI : 16|2@1+ (1.0,0.0) [0.0|3] ""  Kombi
 SG_ AB_wSBR_Batteriestatus : 18|1@1+ (1.0,0.0) [0.0|1] ""  Kombi
 SG_ AB_Gurtwarn_VM : 19|1@1+ (1.0,0.0) [0.0|1] ""  Kombi
 SG_ AB_Gurtschloss_MI : 20|2@1+ (1.0,0.0) [0.0|3] ""  Kombi
 SG_ AB_Anzeige_Komfort_HBFS : 22|2@1+ (1.0,0.0) [0.0|3] ""  Vector__XXX
 SG_ AB_Anzeige_Komfort_HFS : 24|2@1+ (1.0,0.0) [0.0|3] ""  Vector__XXX
 SG_ AB_Anzeige_Sitz_Komfort_HBFS : 26|2@1+ (1.0,0.0) [0.0|3] ""  Vector__XXX
 SG_ AB_Anzeige_Sitz_Komfort_HFS : 28|2@1+ (1.0,0.0) [0.0|3] ""  Vector__XXX
 SG_ AB_Status_Sitz_SRAB_HBFS : 30|2@1+ (1.0,0.0) [0.0|3] ""  Vector__XXX
 SG_ AB_Status_Sitz_SRAB_HFS : 32|2@1+ (1.0,0.0) [0.0|3] ""  Vector__XXX
 SG_ AB_Anzeige_Kombi_SRAB : 34|3@1+ (1.0,0.0) [0.0|7] ""  Kombi

BO_ 280 Allrad_03: 4 Gateway_Max
 SG_ Allrad_03_BZ : 8|4@1+ (1,0) [0|15] ""  Vector__XXX
 SG_ ALR_Sta_Laengssperre : 12|2@1+ (1.0,0.0) [0.0|3] ""  Vector__XXX
 SG_ ALR_Sendestatus : 14|1@1+ (1.0,0.0) [0.0|1] ""  Vector__XXX
 SG_ ALR_Warnlampe : 15|1@1+ (1.0,0.0) [0.0|1] ""  Kombi
 SG_ ALR_Ist_Proz : 16|8@1+ (0.4,0) [0.0|100.0] "Unit_PerCent"  Vector__XXX
 SG_ ALR_Charisma_FahrPr : 24|4@1+ (1.0,0.0) [0.0|15] ""  Vector__XXX
 SG_ ALR_Charisma_Status : 28|2@1+ (1.0,0.0) [0.0|3] ""  Vector__XXX

BO_ 308 Allrad_04: 8 Gateway_Max
 SG_ ALR_gMeter_ax : 44|10@1+ (0.003,-1.5) [-1.500|1.500] "Unit_ForceOfGravi"  HUD,Kombi
 SG_ ALR_gMeter_ay : 54|10@1+ (0.003,-1.5) [-1.500|1.500] "Unit_ForceOfGravi"  HUD,Kombi

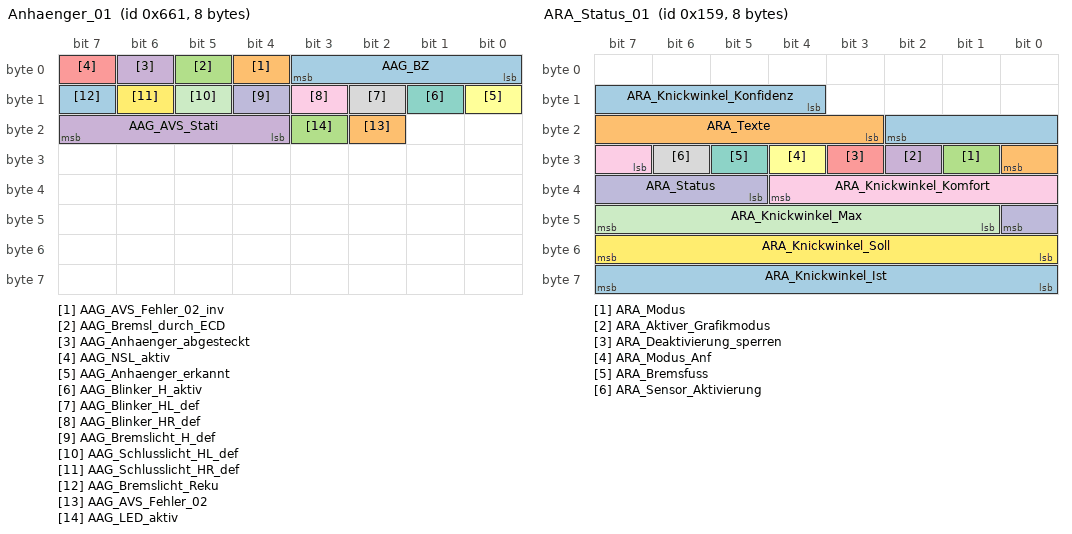
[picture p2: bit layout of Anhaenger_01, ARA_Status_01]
BO_ 1633 Anhaenger_01: 8 Gateway_Max
 SG_ AAG_BZ : 0|4@1+ (1,0) [0|15] ""  Vector__XXX
 SG_ AAG_AVS_Fehler_02_inv : 4|1@1+ (1.0,0.0) [0.0|1] ""  Vector__XXX
 SG_ AAG_Bremsl_durch_ECD : 5|1@1+ (1.0,0.0) [0.0|1] ""  Vector__XXX
 SG_ AAG_Anhaenger_abgesteckt : 6|1@1+ (1.0,0.0) [0.0|1] ""  Vector__XXX
 SG_ AAG_NSL_aktiv : 7|1@1+ (1.0,0.0) [0.0|1] ""  Vector__XXX
 SG_ AAG_Anhaenger_erkannt : 8|1@1+ (1.0,0.0) [0.0|1] ""  Vector__XXX
 SG_ AAG_Blinker_H_aktiv : 9|1@1+ (1.0,0.0) [0.0|1] ""  Kombi
 SG_ AAG_Blinker_HL_def : 10|1@1+ (1.0,0.0) [0.0|1] ""  Kombi
 SG_ AAG_Blinker_HR_def : 11|1@1+ (1.0,0.0) [0.0|1] ""  Kombi
 SG_ AAG_Bremslicht_H_def : 12|1@1+ (1.0,0.0) [0.0|1] ""  Kombi
 SG_ AAG_Schlusslicht_HL_def : 13|1@1+ (1.0,0.0) [0.0|1] ""  Kombi
 SG_ AAG_Schlusslicht_HR_def : 14|1@1+ (1.0,0.0) [0.0|1] ""  Kombi
 SG_ AAG_Bremslicht_Reku : 15|1@1+ (1.0,0.0) [0.0|1] ""  Vector__XXX
 SG_ AAG_AVS_Fehler_02 : 18|1@1+ (1.0,0.0) [0.0|1] ""  Kombi
 SG_ AAG_LED_aktiv : 19|1@1+ (1.0,0.0) [0.0|1] ""  Vector__XXX
 SG_ AAG_AVS_Stati : 20|4@1+ (1.0,0.0) [0.0|15] ""  Vector__XXX

BO_ 345 ARA_Status_01: 8 Gateway_Max
 SG_ ARA_Knickwinkel_Konfidenz : 12|7@1+ (1,0) [0|120] "Unit_DegreOfArc"  Vector__XXX
 SG_ ARA_Texte : 19|6@1+ (1.0,0.0) [0.0|63] ""  Kombi
 SG_ ARA_Modus : 25|1@1+ (1.0,0.0) [0.0|1] ""  Kombi
 SG_ ARA_Aktiver_Grafikmodus : 26|1@1+ (1.0,0.0) [0.0|1] ""  Kombi
 SG_ ARA_Deaktivierung_sperren : 27|1@1+ (1.0,0.0) [0.0|1] ""  Vector__XXX
 SG_ ARA_Modus_Anf : 28|1@1+ (1.0,0.0) [0.0|1] ""  Vector__XXX
 SG_ ARA_Bremsfuss : 29|1@1+ (1.0,0.0) [0.0|1] ""  Kombi
 SG_ ARA_Sensor_Aktivierung : 30|1@1+ (1.0,0.0) [0.0|1] ""  Vector__XXX
 SG_ ARA_Knickwinkel_Komfort : 31|6@1+ (1,0) [0|60] "Unit_DegreOfArc"  Vector__XXX
 SG_ ARA_Status : 37|4@1+ (1.0,0.0) [0.0|15] ""  Vector__XXX
 SG_ ARA_Knickwinkel_Max : 41|7@1+ (1,0) [0|120] "Unit_DegreOfArc"  Kombi
 SG_ ARA_Knickwinkel_Soll : 48|8@1+ (1,-125) [-125|126] "Unit_DegreOfArc"  Kombi
 SG_ ARA_Knickwinkel_Ist : 56|8@1+ (1,-125) [-125|126] "Unit_DegreOfArc"  Kombi

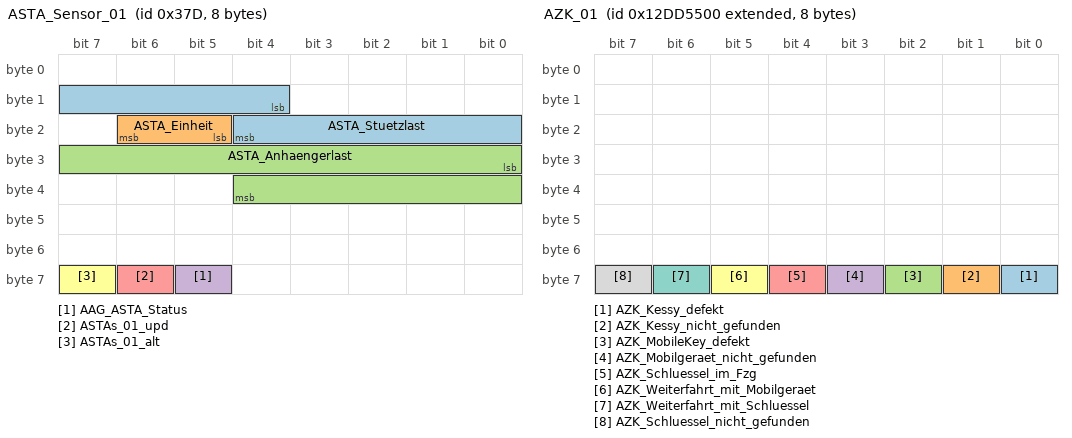
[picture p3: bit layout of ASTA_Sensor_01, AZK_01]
BO_ 893 ASTA_Sensor_01: 8 Gateway_Max
 SG_ ASTA_Stuetzlast : 12|9@1+ (1,0) [0|300] "Unit_None"  Kombi
 SG_ ASTA_Einheit : 21|2@1+ (1.0,0.0) [0.0|3] ""  Kombi
 SG_ ASTA_Anhaengerlast : 24|13@1+ (1,0) [0|5000] "Unit_None"  Kombi
 SG_ AAG_ASTA_Status : 61|1@1+ (1.0,0.0) [0.0|1] ""  Kombi
 SG_ ASTAs_01_upd : 62|1@1+ (1.0,0.0) [0.0|1] ""  Vector__XXX
 SG_ ASTAs_01_alt : 63|1@1+ (1.0,0.0) [0.0|1] ""  Kombi

BO_ 2549880935 AuthTime_eCall_Req: 8 Kombi
 SG_ AuthTime_eCall_Req_Data : 0|64@1+ (1.0,0.0) [0.0|18446744073709551615] ""  Gateway_Max

BO_ 2550012007 AuthTime_eCall_Resp: 8 Gateway_Max
 SG_ AuthTime_eCall_Resp_Data : 0|64@1+ (1.0,0.0) [0.0|18446744073709551615] ""  Kombi

BO_ 2527679661 AWV_02: 8 Gateway_Max
 SG_ WBA_Warnblinken : 0|2@1+ (1.0,0.0) [0.0|3] ""  Vector__XXX
 SG_ AWV_KA_Konfiguration : 2|1@1+ (1.0,0.0) [0.0|1] ""  Vector__XXX
 SG_ AWV_Warnung : 12|3@1+ (1.0,0.0) [0.0|7] ""  HUD,Kombi
 SG_ AWV_Texte_02 : 15|3@1+ (1.0,0.0) [0.0|7] ""  Kombi
 SG_ AWV_Warnlevel : 18|6@1+ (1.0,0.0) [0.0|63] ""  Vector__XXX
 SG_ AWV_Einstellung_System_FSG : 24|1@1+ (1.0,0.0) [0.0|1] ""  Vector__XXX
 SG_ AWV_Einstellung_Warnung_FSG : 25|3@1+ (1.0,0.0) [0.0|7] ""  Vector__XXX
 SG_ AWV_Status_Anzeige : 28|2@1+ (1.0,0.0) [0.0|3] ""  Kombi
 SG_ AWV_LED_Leiste : 30|2@1+ (1.0,0.0) [0.0|3] ""  Vector__XXX
 SG_ AWV_Priowarnung : 32|1@1+ (1.0,0.0) [0.0|1] ""  Vector__XXX
 SG_ AWV_AW_Abstand : 33|9@1+ (1,0) [0|508] "Unit_Meter"  Kombi
 SG_ AWV_AW_Zeitluecke : 42|3@1+ (1.0,0.0) [0.0|7] ""  Kombi
 SG_ AWV_AW_Texte : 45|3@1+ (1.0,0.0) [0.0|7] ""  Kombi
 SG_ AWV_AW_Texte_Zusatzanzeige : 48|4@1+ (1.0,0.0) [0.0|15] ""  Kombi
 SG_ AWV_KA_ObjektFront : 52|1@1+ (1.0,0.0) [0.0|1] ""  Vector__XXX
 SG_ AWV_Warnung_Richtung : 53|3@1+ (1.0,0.0) [0.0|7] ""  HUD,Kombi
 SG_ AWV_Kamera_Objekt_ID : 56|8@1+ (1,0) [1|255] "Unit_None"  Vector__XXX

BO_ 2463978752 AZK_01: 8 Gateway_Max
 SG_ AZK_Kessy_defekt : 56|1@1+ (1.0,0.0) [0.0|1] ""  Kombi
 SG_ AZK_Kessy_nicht_gefunden : 57|1@1+ (1.0,0.0) [0.0|1] ""  Kombi
 SG_ AZK_MobileKey_defekt : 58|1@1+ (1.0,0.0) [0.0|1] ""  Kombi
 SG_ AZK_Mobilgeraet_nicht_gefunden : 59|1@1+ (1.0,0.0) [0.0|1] ""  Kombi
 SG_ AZK_Schluessel_im_Fzg : 60|1@1+ (1.0,0.0) [0.0|1] ""  Kombi
 SG_ AZK_Weiterfahrt_mit_Mobilgeraet : 61|1@1+ (1.0,0.0) [0.0|1] ""  Vector__XXX
 SG_ AZK_Weiterfahrt_mit_Schluessel : 62|1@1+ (1.0,0.0) [0.0|1] ""  Vector__XXX
 SG_ AZK_Schluessel_nicht_gefunden : 63|1@1+ (1.0,0.0) [0.0|1] ""  Kombi

CM_ "K3CANFD_V14.09F Generated by BusNet_NG_Produktiv 9.25.5";
CM_ BU_ ELV "Lenksäulenverriegelung im MEB";
CM_ BU_ HUD "Head Up Display MEB";
CM_ BU_ Kombi "Kombi Baseline";

CM_ BO_ 1660 "MLBevo";
CM_ BO_ 280 "Allrad im MQB";
CM_ BO_ 308 "Botschaft exklusiv für LB83x - alte Haldex-Schnittstelle, nicht zur Weiterentwicklung verwenden!";
CM_ BO_ 1633 "ab MQB 7.2";

CM_ SG_ 2589283940 AC_FES_Aktive_Atmosphere "Signal enthält die  ID des aktiven Atmosphere-Soll-Profils";
CM_ SG_ 2589283940 AC_FES_Atmosphere_1 "Signal enthält die ATMosphere Profil-ID, die auf der jeweiligen Fahrerlebnisschalter-Position  gezeigt werden soll.";
CM_ SG_ 2589283940 AC_FES_Atmosphere_2 "Signal enthält die ATMosphere Profil-ID, die auf der jeweiligen Fahrerlebnisschalter-Position  gezeigt werden soll.";
CM_ SG_ 2589283940 AC_FES_Atmosphere_3 "Signal enthält die ATMosphere Profil-ID, die auf der jeweiligen Fahrerlebnisschalter-Position  gezeigt werden soll.";
CM_ SG_ 2589283940 AC_FES_Atmosphere_4 "Signal enthält die ATMosphere Profil-ID, die auf der jeweiligen Fahrerlebnisschalter-Position  gezeigt werden soll.";
CM_ SG_ 2589283940 AC_FES_Atmosphere_5 "Signal enthält die ATMosphere Profil-ID, die auf der jeweiligen Fahrerlebnisschalter-Position  gezeigt werden soll.";
CM_ SG_ 2589283940 AC_FES_Atmosphere_6 "Signal enthält die ATMosphere Profil-ID, die auf der jeweiligen Fahrerlebnisschalter-Position  gezeigt werden soll.";
CM_ SG_ 2589283940 AC_FES_Atmosphere_7 "Signal enthält die ATMosphere Profil-ID, die auf der jeweiligen Fahrerlebnisschalter-Position  gezeigt werden soll.";
CM_ SG_ 2589283940 AC_KBI_Sec_View_Request "Von ATM angeforderter Anzeigezustand der Nebenanzeigen im Kombiinstrument";
CM_ SG_ 2589283940 AC_KBI_View_Request "Vom Atmospheres Controller beim Kombi angeforderter View";

CM_ SG_ 768 AbstWarn_LRR_FAS_Fkt_Status "Rückmeldung des Funktionsstatus an FAS ProfileMaster";
CM_ SG_ 768 ACA_Hinweistexte "Anzeigesignal für Hinweise zur Fahrerbedienenhandlung";
CM_ SG_ 768 ACA_Querfuehrung "Ansteuerung einer primären Anzeige 'Querführung aktiv' für ACA in verschiedenen Farben";
CM_ SG_ 768 ACA_Querfuehrung_Texte "Signal zur Ansteuerung von Fahrerhinweisen der Querführung in ACA im Mitteldisplay";
CM_ SG_ 768 ACC_Abstand_Abstandswarner "Signal dient zur Anzeige des Abstands im Kombi
Hinweis: das Signal ist mit dem Signal ACC_Einheit_Abstandswarner zu interpretieren";
CM_ SG_ 768 ACC_Abstand_LNS "VW: Anzeige des gemessenen Abstands zum linken Nebenspurobjekt (LNS) als Entfernung von der Hinterachse des Egofahrzeugs";
CM_ SG_ 768 ACC_Abstand_RNS "VW: Anzeige des gemessenen Abstands zum rechten Nebenspurobjekt (RNS) als Entfernung von der Hinterachse des Egofahrzeugs";
CM_ SG_ 768 ACC_Abstand_WZO "VW: Anzeige des gemessenen Abstands zum Zielobjekt (WZO) als Entfernung von der Hinterachse des Egofahrzeugs";
CM_ SG_ 768 ACC_Abstandsindex_02 "Für die optionale Anzeige einer einheitenlosen Abstandsreserve oder einer gemessenen Zeitlücke in der Zusatzanzeige. Der Wertebereich 1..1021 entspricht Audi (aktiv_Folgefahrt), VW (passiv/aktiv_Folgefahrt). Audi nutzt den Wertebereich 0..1023, VW nutzt d";
CM_ SG_ 768 ACC_Akustik_03 "Ansteuerung der zugehörigen Akustik im Kombiinstrument, solange die entsprechende Bitkombination gesetzt ist.";
CM_ SG_ 768 ACC_Anzeige_Maximalabstand "VW: Zur Skalierung der Anzeige auf die maximale Reichweite (geschwindigkeitsabhängig) als Entfernung von der Hinterachse des Egofahrzeugs";
CM_ SG_ 768 ACC_Anzeige_Objektregelung "VW: Hervorhebung relevantes Regelobjekt in der ACC-Anzeige";
CM_ SG_ 768 ACC_Anzeige_Zeitluecke "Anforderung zur Umschaltung zwischen dem Anzeigemodus 'Keine Änderung Zeitlücke' und 'Änderung Zeitlücke' (z.B. Pfeildarstellung in Zusatzanzeige)
";
CM_ SG_ 768 ACC_Display_Prio "Zur situationsabhängigen Prioritätensteuerung von ACC Anzeigen im nicht permanenten Anzeigebereich. Im Kombiinstrument ist jeder Prioritätsstufe eine adäquate Prio-Definition zugeordnet.

";
CM_ SG_ 768 ACC_EGO_Fahrzeug "Ansteuerung einer Statusanzeige für ACC in verschiedenen Farben";
CM_ SG_ 768 ACC_Einheit_Abstandswarner "Einheit zu Signal ACC_Abstand_Abstandswarner";
CM_ SG_ 768 ACC_Einheit_maxSetzgeschw "Einheit zu Signal ACC_maxSetzgeschw";
CM_ SG_ 768 ACC_ENG_Texte "Signal zur Ansteuerung von Fahrerhinweisen der Energo-Funktioin im Mitteldisplay ";
CM_ SG_ 768 ACC_ENG_Texte_02 "Signal zur Ansteuerung von Fahrerhinweisen der Energo-Funktion im Mitteldisplay";
CM_ SG_ 768 ACC_FoD_Status "Informiert den TSK und Kombi, ob die ACC-Funktion freigeschaltet ist oder nicht.";
CM_ SG_ 768 ACC_FzgStatus_Anfahrbereitschaft "Signal zur Ansteuerung von Fahrerhinweisen der ACC-Anfahrbereitschaft im Mitteldisplay";
CM_ SG_ 768 ACC_FzgStatus_Fehleranzeige "Signal zur Ansteuerung von Fahrerhinweisen der ACC-Fehleranzeige im Mitteldisplay";
CM_ SG_ 768 ACC_FzgStatus_Kamerafusion "Signal zur Ansteuerung von Fahrerhinweisen der ACC-Objekterkennung im Mitteldisplay";
CM_ SG_ 768 ACC_Geschw_Zielfahrzeug "Nur Porsche E2 und Bentley BY636: Zur grafischen Darstellung der Geschwindigkeit eines im ACC Regelbetrieb erkannten Zielobjektes bzw, vorausfahrenden Objektes. ACC ermittelt nach der Vorschrift: Vom Kombi eingelesene 'angezeigte Geschwindigkeit' plus TO_";
CM_ SG_ 768 ACC_Gesetzte_Zeitluecke "Nur in ADR/ACC-Fahrzeugen: ACC Zusatzanzeige: 0 = aus / ungleich 0 = ein; angezeigte ADR-Zeitlücke wird auf 3 Bits begrenzt";
CM_ SG_ 768 ACC_iBoost_Anzeige "Signal dient der Anzeige des iBoost für die Funktion ACC";
CM_ SG_ 768 ACC_Kurvenassistent "Ansteuerung einer Anzeige zur Funktion Kurvenassistent";
CM_ SG_ 768 ACC_maxRegelgeschw "Signal dient zur Anzeige von Regelabweichungen.
Addiert zu der Regelgeschwindigkeit ergibt sich eine Toleranzgeschwindigkeit.";
CM_ SG_ 768 ACC_maxSetzgeschw "maximale ACC-Setzgeschwindigkeit zur Ansteuerung des ACC-Setzbereichs im Kombi
Hinweis: Signal ist mit Signal ACC_Einheit_maxSetzgeschw zu interpretieren";
CM_ SG_ 768 ACC_minRegelgeschw "Signal dient zur Anzeige von Regelabweichungen.
Subtrahiert von der Regelgeschwindigkeit ergibt sich eine Toleranzgeschwindigkeit.";
CM_ SG_ 768 ACC_Modus_Pop_Up "Steuert das Pop-Up bei der Modus-Umschaltung zwischen den Längsregelfunktionen";
CM_ SG_ 768 ACC_Optischer_Fahrerhinweis "Fahrerübernahmeaufforderung; z.B. bei Erreichen der Systemgrenzen oder beim Auftreten von Fehlern in kritischen Situationen (VW).
";
CM_ SG_ 768 ACC_Regelgeschw "Zur Anzeige der Regelgeschwindigkeit (z.B. Kurven- / Tempolimitassistent) im Kombiinstrument";
CM_ SG_ 768 ACC_Regelung_AIO "Unterscheidung im Kombi, ob pACC Regelung auf Ampel aktiv oder AIO zur Anzeige kommt";
CM_ SG_ 768 ACC_rel_Objekt_Zusatzanz "Für optionale Anzeige eines Bildes/Textes in der Zusatzanzeige. ";
CM_ SG_ 768 ACC_Relevantes_Objekt_02 "Ansteuerung einer primären Anzeige 'Relevantes Objekt' für ACC in verschiedenen Farben.";
CM_ SG_ 768 ACC_RUV "Anzeige für Rechtsunterholverhinderung in Abhängigkeit Rechts- / Linksverkehr";
CM_ SG_ 768 ACC_Sollabstand_1 "VW: Anzeige der Fahrerwunschzeitlücke 1 zum Zielobjekt (WZO) als Entfernung von der Hinterachse des Egofahrzeugs";
CM_ SG_ 768 ACC_Sollabstand_2 "VW: Anzeige der Fahrerwunschzeitlücke 2 zum Zielobjekt (WZO) als Entfernung von der Hinterachse des Egofahrzeugs";
CM_ SG_ 768 ACC_Sollabstand_3 "VW: Anzeige der Fahrerwunschzeitlücke 3 zum Zielobjekt (WZO) als Entfernung von der Hinterachse des Egofahrzeugs";
CM_ SG_ 768 ACC_Sollabstand_4 "VW: Anzeige der Fahrerwunschzeitlücke 4 zum Zielobjekt (WZO) als Entfernung von der Hinterachse des Egofahrzeugs";
CM_ SG_ 768 ACC_Sollabstand_5 "VW: Anzeige der Fahrerwunschzeitlücke 5 zum Zielobjekt (WZO) als Entfernung von der Hinterachse des Egofahrzeugs";
CM_ SG_ 768 ACC_STA_Text "ACC_STA_Text wird gesendet wenn aktiv regelt.";
CM_ SG_ 768 ACC_Status_Anzeige "Status nur zur Defintion von Anzeige im Kombi. Hinweis: Wird für die spez. VW-Anzeige (überlappende Anzeigebereiche) verwendet. Vom AUDI-ACC im Rahmen der Modulstrategie zu bedienen.";
CM_ SG_ 768 ACC_Status_GRA_Modus "Statusinformation zur GRA in Verbindung mit ACC";
CM_ SG_ 768 ACC_Status_Stauende "Information, ob ACC auf ein Stauende auf Basis von Car2X reagiert.";
CM_ SG_ 768 ACC_Statusicon "Statusanzeige der aktiven Längsregelfuntkion (ACC/GRA-Modus)";
CM_ SG_ 768 ACC_Tachokranz "Für zusätzliche Status- und Einstellbereichsanzeige im Tacho. (z.B. Tachokranz)
";
CM_ SG_ 768 ACC_Tempolimit "Anzeige einer Tempolimit-Vorgabe (Geschwindigkeitsbegrenzung, Aufhebung einer Geschwindigkeitsbegrenzung)

Signalbeschreibung 0..31: siehe LH Kombi-SG_-_6.2.x_ACC";
CM_ SG_ 768 ACC_Tempolimit_Einheit "Einheit des Verkehrszeichen in ACC_Tempolimit";
CM_ SG_ 768 ACC_Tempolimitassistent_02 "Ansteuerng einer Anzeige zur Funktion Tempolimitassistent";
CM_ SG_ 768 ACC_Texte_02 "Zusätzliches Signal zu 'ACC_Texte_Primaeranz', welches Warnungen und Fahrerhinweise bzgl. ACC im Mitteldisplay des Kombis anzeigt.";
CM_ SG_ 768 ACC_Texte_03 "Zusätzliches Signal zu 'ACC_Texte_Primaeranz', welches Warnungen und Fahrerhinweise bzgl. ACC im Mitteldisplay des Kombis anzeigt; Signalergänzung der Aktivierverhinderung aufgrund Geschwindigkeitsgrenze für ACC und TA";
CM_ SG_ 768 ACC_Texte_Abstandswarner "Signal zur Ansteuerung von Fahrer- und Warnhinweisen des Abstandswarners im Mitteldisplay";
CM_ SG_ 768 ACC_Texte_Primaeranz_03 "Textdefinitionen";
CM_ SG_ 768 ACC_Texte_Sekundaeranz "Textdefinitionen für Anzeige ACC, Tempolimitassistent und Kurvenassistent";
CM_ SG_ 768 ACC_Texte_Sekundaeranz_02 "VW: Anzeige ACC Informationen, wie z.B. die Vorankündigung, oder die Anfahrbereitschaft";
CM_ SG_ 768 ACC_Texte_Sekundaeranz_03 "VW: Anzeige ACC Informationen, wie z.B. die Vorankündigung, oder die Anfahrbereitschaft";
CM_ SG_ 768 ACC_Texte_Zusatzanz_03 "Beschreibt aktuell aktives Fahrprogramm/Zeitlücke usw. des ACC";
CM_ SG_ 768 ACC_Typ_LNS "VW: Anzeige der Klasse des linken Nebenspurobjektes (LNS)";
CM_ SG_ 768 ACC_Typ_RNS "VW: Anzeige der Klasse des rechten Nebenspurobjektes (RNS)";
CM_ SG_ 768 ACC_Typ_Tachokranz "Abhängig von der ACC-Codierung 'Land' ist der Bereich der einstellbaren Wunschgeschwindigkeit und damit die Länge des schwach beleuchteten Tachokranzes begrenzt. Das Bit steuert im Kombi die Ausleuchtung des Tachokranzes an.
Der auszuleuchtende Bereich i";
CM_ SG_ 768 ACC_Typ_Tachokranz_unten "Mit diesem Bit wird die LED unterhalb der minimalen Setzgeschwindigkeit an/ausgeschaltet.
";
CM_ SG_ 768 ACC_Typ_WZO "VW: Anzeige der Klasse des Zielobjektes (WZO)";
CM_ SG_ 768 ACC_Vorz_Abstandswarner "Vorzeichen der Abstandsanzeige und -warnung";
CM_ SG_ 768 ACC_Warnhinweis "Porsche E2: zur Anzeige der gelben Warnaufforderung als Vorstufe zum TOR (TOR: Übernahmeaufforderung bei Erreichen der ACC-Systemgrenze)

VW MQB: Signal wird zur Ansteuerung der Abstandswarnung im Kombiinstrument genutzt.";
CM_ SG_ 768 ACC_Warnung_Verkehrszeichen_1 "PACC: Zeigt bei Überschreitung der aktuellen Höchstgeschwindigkeit um 10% einen Hinweis im Kombi an";
CM_ SG_ 768 ACC_Wunschgeschw_02 "Zur Anzeige der Wunschgeschwindigkeit im Kombiinstrument
";
CM_ SG_ 768 ACC_Wunschgeschw_erreicht "Signal for Bentley BY83x: ACC_set_speed_achieved

Mit diesem Signal wird im Kombi eine Anzeige angesteuert, wenn das Fahrzeug die gesetzte Wunschgeschwindigkeit erreicht hat.

This signal illuminates the set speed icon a different colour  in the Kombi";
CM_ SG_ 768 ACC_Wunschgeschw_Farbe "Umschaltung der Farbe der angezeigten Setzgeschwindigkeit im Tacho";
CM_ SG_ 768 ACC_Wunschgeschw_Farbe_02 "Umschaltung der Farbe der angezeigten Setzgeschwindigkeit im Tacho";
CM_ SG_ 768 ACC_Zeitluecke_Abstandswarner "Anzeige der aktuellen Zeitluecke zum vorausfahrenden Fahrzeug";
CM_ SG_ 768 FAS_Licht_Anf "Anforderung zum Einschalten des Assistenzfahrlicht";
CM_ SG_ 768 STA_Primaeranz "Signal zur Ansteuerung der STA-Primaeranzeige";
CM_ SG_ 768 STA_Texte "Signal, welches Warnungen und Fahrerhinweise bzgl. der Funktion STA im Kombi anzeigt";
CM_ SG_ 768 STA_Zusatzanz "Für Anzeigen der STA-Funktion im Mitteldisplay";

CM_ SG_ 859 ACC_Obj_01_Alter "Objektdatenalter (Anzahl der Zyklen seit der Intitialisierung des Objekts im Sensor)";
CM_ SG_ 859 ACC_Obj_01_Anzeige_Rel "Statusinformation zur Anzeigerelevanz des Objektes";
CM_ SG_ 859 ACC_Obj_01_ax_StdA "Standardabweichung der Relativbeschleunigung in x-Richtung des bezüglich des Ego-Fzg. Momentankurses detektierten Objektes";
CM_ SG_ 859 ACC_Obj_01_ax_v "Relative Beschleunigung in x (m/s2) Beschleunigungen beziehen sich immer auf den Objektmittelpunkt";
CM_ SG_ 859 ACC_Obj_01_axAbs_StdA "Standardabweichung der Absolutbeschleunigung in x-Richtung";
CM_ SG_ 859 ACC_Obj_01_axAbs_v "Absolutbeschleunigung in x (m/s2) des Objektes";
CM_ SG_ 859 ACC_Obj_01_ay_StdA "Standardabweichung zu ACC_Obj_01_ay_v";
CM_ SG_ 859 ACC_Obj_01_ay_v "Relative Beschleunigung in y (m/s2) Beschleunigungen beziehen sich immer auf den Objektmittelpunkt";
CM_ SG_ 859 ACC_Obj_01_Bew_Zustand "Bewegungszustand des Objektes
Init
fahrend
angehalten
stehend";
CM_ SG_ 859 ACC_Obj_01_Bezugspunkt "Index des verwendeten Bezugspunktes auf der 3D-Objektbox Anmerkung: Die Bezeichnungen vorne/hinten rechts/links beziehen sich direkt auf die angegebene Ausrichtung des Objekts. Sollte diese Information nicht vorliegen, kann eine Ausrichtung gewählt werden";
CM_ SG_ 859 ACC_Obj_01_Breite "Breite der 3D-Objektbox";
CM_ SG_ 859 ACC_Obj_01_BreiteStdA "Standardabweichung zu ACC_Obj_01_Breite";
CM_ SG_ 859 ACC_Obj_01_dx_StdA "Standardabweichung zu ACC_Obj_01_dx_v";
CM_ SG_ 859 ACC_Obj_01_dx_v "Position des Objektes in x-Richtung (Referenzpunkt der 3D-Objektbox)";
CM_ SG_ 859 ACC_Obj_01_dy_StdA "Standardabweichung zu ACC_Obj_01_dy_v";
CM_ SG_ 859 ACC_Obj_01_dy_v "Position des Objektes in y-Richtung (Referenzpunkt der 3D-Objektbox)";
CM_ SG_ 859 ACC_Obj_01_dz_StdA "Standardabweichung zu ACC_Obj_01_dz_v";
CM_ SG_ 859 ACC_Obj_01_dz_v "Position der Unterkante  des Objektes in z bezügl. des 3D Koordinatensystems  (Referenzpunkt der 3D-Objektbox). Anmerkung: Fahrzeuge können damit durch Bodenunebenheiten Z-Werte<>0 erhalten!";
CM_ SG_ 859 ACC_Obj_01_ExistenzMass "Wahrscheinlichkeit, dass an der angegebenen Position (im 3sigma-Bereich) zum angegebenen Zeitpunkt ein Objekt existiert
Anmerkung: Vorschlag durch jeweiligen Zulieferer / Erklärung der Berechnung / Vergleich mit eigenen (konzerninternen) Maßen";
CM_ SG_ 859 ACC_Obj_01_Fusion_ID_FER_VL "Information, mit welchem Eckradarobjekt  (vorne links) das Gegenverkehrsobjekt in der SDF bestätigt wurde";
CM_ SG_ 859 ACC_Obj_01_Fusion_ID_FER_VR "Information, mit welchem Eckradarobjekt  (vorne rechts) das Gegenverkehrsobjekt in der SDF bestätigt wurde";
CM_ SG_ 859 ACC_Obj_01_Fusion_ID_VD "Information, mit welchem Videoobjekt (ID) das Gegenverkehrsobjekt in der SDF bestätigt wurde";
CM_ SG_ 859 ACC_Obj_01_Gemessen "Status Objekt gemessen/getrackt

0 = Objekt nicht gemessen, nur per 3D Modell praediziert (auch BVS)
1 = Objekt wurde im aktuellen Zyklus gemessen
2 = Nur für BVS: Objekt wurde nicht gemessen, sondern per Feature-Tracking wiedergefunden (Optischer Flu";
CM_ SG_ 859 ACC_Obj_01_GierWnkl "Gierwinkel des Objektes relativ zum EGO Fahrzeug (=Orientierung der 3D-Objektbox)";
CM_ SG_ 859 ACC_Obj_01_GierWnklStdA "Standardabweichung zu ACC_Obj_01_GierWnkl";
CM_ SG_ 859 ACC_Obj_01_Historie "Objekt wurde bereits in den letzten Zyklen gemessen (0.. Erstmalige Ausgabe auf dem Bus)
Anmerkung: Wenn das Objekt zwischenzeitlich nicht auf dem Bus ausgegeben wird, aber intern weiter verfolgt wird, wird das Bit bei einer weiteren Ausgabe des SELBEN O";
CM_ SG_ 859 ACC_Obj_01_Hoehe "Höhe der 3D-Objektbox (m) Der Maximalwert 3,875 wird hier als Ausgabe für Objekte einer Höhe von 3,875 m und höher verstanden.";
CM_ SG_ 859 ACC_Obj_01_HoeheStdA "Standardabweichung zu ACC_Obj_01_Hoehe";
CM_ SG_ 859 ACC_Obj_01_ID "ID des Objektes";
CM_ SG_ 859 ACC_Obj_01_Klasse "Klasse des Objekts";
CM_ SG_ 859 ACC_Obj_01_KlassePlausib "Wahrscheinlichkeit für die korrekte Klassifizierung des Objektes";
CM_ SG_ 859 ACC_Obj_01_Laenge "Länge der 3D-Objektbox. Der phys. Maximalwert 31,875 wird hier als Ausgabe für Objekte einer Länge von 31,875 m und länger verstanden. Anmerkung: Länge ist generell nur bei entsprechend großem Gierwinkel bzw. Querversatz zu ermitteln";
CM_ SG_ 859 ACC_Obj_01_LaengeStdA "Standardabweichung zu ACC_Obj_01_Laenge";
CM_ SG_ 859 ACC_Obj_01_LaengsRegelung "Info, ob ACC aktuell auf dieses Objekt regelt";
CM_ SG_ 859 ACC_Obj_01_SDFInfo_FER_VL "Bestätigung des Mitverkehrsobjektes durch Fronteckradar VL";
CM_ SG_ 859 ACC_Obj_01_SDFInfo_FER_VR "Bestätigung des Mitverkehrsobjektes durch Fronteckradar VR";
CM_ SG_ 859 ACC_Obj_01_SDFInfo_FR "Bestätigung des Mitverkehrsobjektes durch Frontradar";
CM_ SG_ 859 ACC_Obj_01_SDFInfo_Kamera "Bestätigung des Mitverkehrsobjektes durch Kamera";
CM_ SG_ 859 ACC_Obj_01_vx_StdA "Standardabweichung zu ACC_Obj_01_vx_v";
CM_ SG_ 859 ACC_Obj_01_vx_v "Relative Geschwindigkeit in x (m/s)
Geschwindigkeiten beziehen sich immer auf den Objektmittelpunkt
Messung in Radialrichtung";
CM_ SG_ 859 ACC_Obj_01_vxAbs_StdA "Standardabweichung der Absolutgeschwindigkeit in x-Richtung des bezüglich des Ego-Fzg. Momentankurses detektierten Mitverkehrsobjektdatenblocks";
CM_ SG_ 859 ACC_Obj_01_vxAbs_v "Absolutgeschwindigkeit in x-Richtung des bezüglich des Ego-Fzg. Momentankurses detektierten Mitverkehrsobjektdatenblocks";
CM_ SG_ 859 ACC_Obj_01_vy_StdA "Standardabweichung zu ACC_Obj_01_vy_v";
CM_ SG_ 859 ACC_Obj_01_vy_v "Relative Geschwindigkeit in x (m/s) Geschwindigkeiten beziehen sich immer auf den Objektmittelpunkt Messung in Radialrichtung Geschwindigkeiten beziehen sich immer auf den Objektmittelpunkt";
CM_ SG_ 859 ACC_Obj_01_vyAbs_StdA "Standardabweichung der Absolutgeschwindigkeit in y-Richtung des bezüglich des Ego-Fzg. Momentankurses detektierten Mitverkehrsobjektdatenblocks";
CM_ SG_ 859 ACC_Obj_01_vyAbs_v "Absolutgeschwindigkeit in y-Richtung des bezüglich des Ego-Fzg. Momentankurses detektierten Mitverkehrsobjektdatenblocks";

CM_ SG_ 2331595990 ACC_Obj_02_Alter "Objektdatenalter (Anzahl der Zyklen seit der Intitialisierung des Objekts im Sensor)";
CM_ SG_ 2331595990 ACC_Obj_02_Anzeige_Rel "Statusinformation zur Anzeigerelevanz des Objektes";
CM_ SG_ 2331595990 ACC_Obj_02_ax_StdA "Standardabweichung der Relativbeschleunigung in x-Richtung des bezüglich des Ego-Fzg. Momentankurses detektierten Objektes";
CM_ SG_ 2331595990 ACC_Obj_02_ax_v "Relative Beschleunigung in x (m/s2)
Beschleunigungen beziehen sich immer auf den Objektmittelpunkt";
CM_ SG_ 2331595990 ACC_Obj_02_ay_StdA "Standardabweichung zu ACC_Obj_02_ay_v";
CM_ SG_ 2331595990 ACC_Obj_02_ay_v "Relative Beschleunigung in y (m/s2)
Beschleunigungen beziehen sich immer auf den Objektmittelpunkt";
CM_ SG_ 2331595990 ACC_Obj_02_Bezugspunkt "Index des verwendeten Bezugspunktes auf der 3D-Objektbox  Anmerkung: Die Bezeichnungen vorne/hinten rechts/links beziehen sich direkt auf die angegebene Ausrichtung des Objekts. Sollte diese Information nicht vorliegen, kann eine Ausrichtung gewählt werde";
CM_ SG_ 2331595990 ACC_Obj_02_Breite "Breite der 3D-Objektbox";
CM_ SG_ 2331595990 ACC_Obj_02_BreiteStdA "Standardabweichung zu ACC_Obj_02_Breite";
CM_ SG_ 2331595990 ACC_Obj_02_dx_v "Position des Objektes in x-Richtung (Referenzpunkt der 3D-Objektbox)";
CM_ SG_ 2331595990 ACC_Obj_02_dy_v "Position des Objektes in y-Richtung (Referenzpunkt der 3D-Objektbox)";
CM_ SG_ 2331595990 ACC_Obj_02_dz_v "Position der Unterkante  des Objektes in z bezügl. des 3D Koordinatensystems  (Referenzpunkt der 3D-Objektbox).
Anmerkung: Fahrzeuge können damit durch Bodenunebenheiten Z-Werte<>0 erhalten!";
CM_ SG_ 2331595990 ACC_Obj_02_ExistenzMass "Wahrscheinlichkeit, dass an der angegebenen Position (im 3sigma-Bereich) zum angegebenen Zeitpunkt ein Objekt existiert
Anmerkung: Vorschlag durch jeweiligen Zulieferer / Erklärung der Berechnung / Vergleich mit eigenen (konzerninternen) Maßen";
CM_ SG_ 2331595990 ACC_Obj_02_Fusion_ID_FER_VL "Information, mit welchem Eckradarobjekt  (vorne links) das Gegenverkehrsobjekt in der SDF bestätigt wurde";
CM_ SG_ 2331595990 ACC_Obj_02_Fusion_ID_FER_VR "Information, mit welchem Eckradarobjekt  (vorne rechts) das Gegenverkehrsobjekt in der SDF bestätigt wurde";
CM_ SG_ 2331595990 ACC_Obj_02_Fusion_ID_VD "Information, mit welchem Videoobjekt (ID) das Gegenverkehrsobjekt in der SDF bestätigt wurde";
CM_ SG_ 2331595990 ACC_Obj_02_Gemessen "Status Objekt gemessen/getrackt

0 = Objekt nicht gemessen, nur per 3D Modell praediziert (auch BVS)
1 = Objekt wurde im aktuellen Zyklus gemessen
2 = Nur für BVS: Objekt wurde nicht gemessen, sondern per Feature-Tracking wiedergefunden (Optischer Flu";
CM_ SG_ 2331595990 ACC_Obj_02_GierWnkl "Gierwinkel des Objektes relativ zum EGO Fahrzeug (=Orientierung der 3D-Objektbox)";
CM_ SG_ 2331595990 ACC_Obj_02_GierWnklStdA "Standardabweichung zu ACC_Obj_02_GierWnkl";
CM_ SG_ 2331595990 ACC_Obj_02_Historie "Objekt wurde bereits in den letzten Zyklen gemessen (0.. Erstmalige Ausgabe auf dem Bus)
Anmerkung: Wenn das Objekt zwischenzeitlich nicht auf dem Bus ausgegeben wird, aber intern weiter verfolgt wird, wird das Bit bei einer weiteren Ausgabe des SELBEN O";
CM_ SG_ 2331595990 ACC_Obj_02_Hoehe "Höhe der 3D-Objektbox (m)
Der Maximalwert 3,875 wird hier als Ausgabe für Objekte einer Höhe von 3,875 m und höher verstanden.";
CM_ SG_ 2331595990 ACC_Obj_02_HoeheStdA "Standardabweichung zu ACC_Obj_02_Hoehe";
CM_ SG_ 2331595990 ACC_Obj_02_ID "ID des Objektes";
CM_ SG_ 2331595990 ACC_Obj_02_Laenge "Länge der 3D-Objektbox.
Der phys. Maximalwert 31,875 wird hier als Ausgabe für Objekte einer Länge von 31,875 m und länger verstanden.
Anmerkung: Länge ist generell nur bei entsprechend großem Gierwinkel bzw. Querversatz zu ermitteln";
CM_ SG_ 2331595990 ACC_Obj_02_LaengeStdA "Standardabweichung zu ACC_Obj_02_Laenge";
CM_ SG_ 2331595990 ACC_Obj_02_LaengsRegelung "Info, ob ACC aktuell auf dieses Objekt regelt";
CM_ SG_ 2331595990 ACC_Obj_02_SDFInfo_FER_VL "Bestätigung des Mitverkehrsobjektes durch Fronteckradar VL";
CM_ SG_ 2331595990 ACC_Obj_02_SDFInfo_FER_VR "Bestätigung des Mitverkehrsobjektes durch Fronteckradar VR";
CM_ SG_ 2331595990 ACC_Obj_02_SDFInfo_FR "Bestätigung des Mitverkehrsobjektes durch Frontradar";
CM_ SG_ 2331595990 ACC_Obj_02_vx_v "Relative Geschwindigkeit in x (m/s)
Geschwindigkeiten beziehen sich immer auf den Objektmittelpunkt
Messung in Radialrichtung";
CM_ SG_ 2331595990 ACC_Obj_02_vxAbs_StdA "Standardabweichung der Absolutgeschwindigkeit in x-Richtung des bezüglich des Ego-Fzg. Momentankurses detektierten Mitverkehrsobjektdatenblocks";
CM_ SG_ 2331595990 ACC_Obj_02_vxAbs_v "Absolutgeschwindigkeit in x-Richtung des bezüglich des Ego-Fzg. Momentankurses detektierten Mitverkehrsobjektdatenblocks";
CM_ SG_ 2331595990 ACC_Obj_02_vy_v "Relative Geschwindigkeit in x (m/s)
Geschwindigkeiten beziehen sich immer auf den Objektmittelpunkt
Messung in Radialrichtung";
CM_ SG_ 2331595990 ACC_Obj_02_vyAbs_StdA "Standardabweichung der Absolutgeschwindigkeit in y-Richtung des bezüglich des Ego-Fzg. Momentankurses detektierten Mitverkehrsobjektdatenblocks";
CM_ SG_ 2331595990 ACC_Obj_02_vyAbs_v "Absolutgeschwindigkeit in y-Richtung des bezüglich des Ego-Fzg. Momentankurses detektierten Mitverkehrsobjektdatenblocks";

CM_ SG_ 2331596021 ACC_Obj_05_Anzeige_Rel "Statusinformation zur Anzeigerelevanz des Objektes";
CM_ SG_ 2331596021 ACC_Obj_05_axAbs_v "ACA_Obj_03_ay_StdA";
CM_ SG_ 2331596021 ACC_Obj_05_Bew_Zustand "Bewegungszustand des Objektes
Init
fahrend
angehalten
stehend";
CM_ SG_ 2331596021 ACC_Obj_05_dx_v "Position des Objektes in x-Richtung (Referenzpunkt der 3D-Objektbox)";
CM_ SG_ 2331596021 ACC_Obj_05_dy_v "Position des Objektes in y-Richtung (Referenzpunkt der 3D-Objektbox)";
CM_ SG_ 2331596021 ACC_Obj_05_Gemessen "Status Objekt gemessen/getrack";
CM_ SG_ 2331596021 ACC_Obj_05_Historie "Objekt wurde bereits in den letzten Zyklen gemessen (0.. Erstmalige Ausgabe auf dem Bus) Anmerkung: Wenn das Objekt zwischenzeitlich nicht auf dem Bus ausgegeben wird, aber intern weiter verfolgt wird, wird das Bit bei einer weiteren Ausgabe des SELBEN Ob";
CM_ SG_ 2331596021 ACC_Obj_05_ID "ID des Objektes";
CM_ SG_ 2331596021 ACC_Obj_05_Klasse "Klasse des Objekts";
CM_ SG_ 2331596021 ACC_Obj_05_KlassePlausib "Wahrscheinlichkeit für die korrekte Klassifizierung des Objektes";
CM_ SG_ 2331596021 ACC_Obj_05_SDFInfo_FER_VL "Bestätigung des Mitverkehrsobjektes durch Fronteckradar VL";
CM_ SG_ 2331596021 ACC_Obj_05_SDFInfo_FER_VR "Bestätigung des Mitverkehrsobjektes durch Fronteckradar VR";
CM_ SG_ 2331596021 ACC_Obj_05_SDFInfo_FR "Bestätigung des Mitverkehrsobjektes durch Frontradar";
CM_ SG_ 2331596021 ACC_Obj_05_SDFInfo_Kamera "Bestätigung des Mitverkehrsobjektes durch Kamera";
CM_ SG_ 2331596021 ACC_Obj_05_vx_StdA "Standardabweichung zu ACC_Obj_05_vx_v";
CM_ SG_ 2331596021 ACC_Obj_05_vx_v "Relative Geschwindigkeit in x (m/s)
Geschwindigkeiten beziehen sich immer auf den Objektmittelpunkt
Messung in Radialrichtung";
CM_ SG_ 2331596021 ACC_Obj_05_vy_StdA "Standardabweichung zu ACC_Obj_05_vy_v";
CM_ SG_ 2331596021 ACC_Obj_05_vy_v "Relative Geschwindigkeit in y (m/s) Geschwindigkeiten beziehen sich immer auf den Objektmittelpunkt Messung in Radialrichtung Geschwindigkeiten beziehen sich immer auf den Objektmittelpunkt";

CM_ SG_ 2527679923 ADA_AttentionLevel "combined attention level";
CM_ SG_ 2527679923 ADA_DistractionLevel "combined distraction level";
CM_ SG_ 2527679923 ADA_DriverIsOperating "combined signal from all driver HMI inputs";
CM_ SG_ 2527679923 ADA_DrowsinessLevel "combined drowsiness level.";
CM_ SG_ 2527679923 ADA_DrowsinessSystemState "This signal contain the system state of the drowsiness detection of the customer driving function Attention and Drowsiness Assist (ADA).";
CM_ SG_ 2527679923 ADA_HMI_Ablenkung_Deaktivierung "This signal contain the deactivation notification of the distraction detection in form of a popup of the customer driving function Attention and Drowsiness Assist (ADA).";
CM_ SG_ 2527679923 ADA_HMI_Ablenkung_Fehler_Popup "This signal contain the different distraction detection error notifications in form of a popup of the customer driving function Attention and Drowsiness Assist (ADA).";
CM_ SG_ 2527679923 ADA_HMI_Ablenkung_Meldeakustik "This signal contain the information, if the different distraction detection notifications of the customer driving function Attention and Drowsiness Assist (ADA) should play with acoustic or without acoustic.";
CM_ SG_ 2527679923 ADA_HMI_Ablenkung_Meldung "This signal contain the different distraction detection notifications in form of a popup of the customer driving function Attention and Drowsiness Assist (ADA).";
CM_ SG_ 2527679923 ADA_HMI_Fahrzeit_seit_Pause "This signal contain the driving time since the last break of the driver.";
CM_ SG_ 2527679923 ADA_HMI_Muedigkeit_Deaktivierung "This signal contain the deactivation notification of the drowsiness detection in form of a popup of the customer driving function Attention and Drowsiness Assist (ADA).";
CM_ SG_ 2527679923 ADA_HMI_Muedigkeit_Event_Meldung "This signal contain the different drowsiness event notifications (e. g. yawning, microsleep, ...) in form of a popup of the customer driving function Attention and Drowsiness Assist (ADA).";
CM_ SG_ 2527679923 ADA_HMI_Muedigkeit_Fehler_Popup "This signal contain the different drowsiness detection error notifications in form of a popup of the customer driving function Attention and Drowsiness Assist (ADA).";
CM_ SG_ 2527679923 ADA_HMI_Muedigkeit_Meldeakustik "This signal contain the information, if the different drowsiness detection notifications of the customer driving function Attention and Drowsiness Assist (ADA) should play with acoustic or without acoustic.";
CM_ SG_ 2527679923 ADA_HMI_Muedigkeit_Meldung "This signal contain the different drowsiness detection notifications in form of a popup of the customer driving function Attention and Drowsiness Assist (ADA).";
CM_ SG_ 2527679923 ADA_Microsleep "microsleep detection";
CM_ SG_ 2527679923 ADA_TriggerEmergencyAssist "Signal dient zum Triggern des Emergency Assists durch ADA im Fall von einem unresponsed Driver";
CM_ SG_ 2527679923 ADA_Upcoming_Microsleep "Über das Signal wird der Zustand ausgegeben, ob der Fahrer kurz vor einem Sekundenschlaf steht";
CM_ SG_ 2527679923 SOK_ADA_01_Signatur "Signatur im Rahmen der durch SOK geschützen Broadcast-Kommunikation
";

CM_ SG_ 1660 AGA_Charisma_FahrPr "MLBevo: Aktuelles Fahrprogramm des Charisma-Teilnehmers (siehe Systemlastenheft Drive Select)
MQB: Istwert der Kennlinie (siehe Systemlastenheft MQB FPA)";
CM_ SG_ 1660 AGA_Charisma_Status "Rückmeldung an den Charisma-Master

Wert 0x3 ist nur für Fahrzeuge ab MQB relevant";
CM_ SG_ 1660 AGA_ohne_Funktion "Aussensoundsteuergerät ohne Funktion (Gesetzliche Anforderung, Fahrzeugnutzer muss informiert werden).";
CM_ SG_ 1660 AGA_Texte "Texte zur Anzeige im Kombi";
CM_ SG_ 1660 AGA_Verstaerker_Mute "Freischaltung Verstaerkerkanal";
CM_ SG_ 1660 E_Sound_verbaut "Signal dient zur Unterscheidung der beiden SGs 'aktive AGA' und 'e-sound' durch das Kombii. Beide SGs nutzen identische Signale und gleiche Diagnoseadresse.";

CM_ SG_ 64 AB_Anzeige_Fussg "Anzeige für ausgelöste Fussgängerschutz-Aktuatorik";
CM_ SG_ 64 AB_Belegung_VF "Belegungserkennung vorne Fahrer.";
CM_ SG_ 64 AB_Crash_Int "Crash_Intensität_1 = fahrzeugabhängige Reaktionen im Crash
Crash_Intensität_2 = fahrzeugabhängige Reaktionen im Crash
Crash_Intensität_3 = fahrzeugabhängige Reaktionen im Crash

Die jeweiligen fahrzeugabhängigen Reaktionen im Crash sind in einem separ";
CM_ SG_ 64 AB_Deaktiviert "Airbag oder Gurtstraffer wurden per Anpassung deaktiviert: Aktualisierung erst nach Selbsttest";
CM_ SG_ 64 AB_Deaktivierung_HV "Deaktivierung des HV-Systems und der HV-Teilnehmer im Crash (u.a. Hybrid- und Elektrofahrzeuge)";
CM_ SG_ 64 AB_Diagnose "Airbag in Diagnose";
CM_ SG_ 64 AB_eCS_Error "Signal zur Anforderung der Anzeige von Störungen im System der elektrischen Gurtverriegelung";
CM_ SG_ 64 AB_EDR_Trigger "Triggerbedingung zur dezentralen Aufzeichnung unfallrelevanter Daten im Event Data Recorder";
CM_ SG_ 64 AB_Erh_Auf_VB "Der Fahrer soll bei einem Statuswechsel des Beifahrerairbags (ausgelöst durch die Beifahrerinsassenerkennung oder den Schlüsselschloßschalter) aufmerksam gemacht werden durch eine Anzeige im Kombi. Nur Audi: gültig für: AB2 (4-Türer AU352), B7, C6, D3";
CM_ SG_ 64 AB_Front_Crash "Bit wird bei Überschreitung der Gurtstraffer-, US- und RdW-Schwelle gesetzt";
CM_ SG_ 64 AB_Gurtschloss_FA_ext "Das Ergebnis der Basisfunktion 'Plausibilisierung Gurtschloss' des Verlassenskonzepts wird im Signal dargestellt.";
CM_ SG_ 64 AB_Gurtschloss_FA_ext_aktiv "Über dieses Signal wird signalisiert ob die Erweiterte Gurtdiagnose (Ergebnis wird im Signal AB_Gurtschloss_FA_ext dargestellt) aktiviert oder deaktiviert ist.";
CM_ SG_ 64 AB_Gurtwarn_VB "Beifahrer hat Gurt nicht gesteckt, Anzeige im Kombi";
CM_ SG_ 64 AB_Gurtwarn_VF "Fahrer hat Gurt nicht gesteckt, Anzeige im Kombi";
CM_ SG_ 64 AB_Heck_Crash "Wird für alle neu anlaufenden Projekte umgesetzt: AB8.4, Audi8/VW8";
CM_ SG_ 64 AB_Lampe "Sicherheitswarnlampe im Kombi wird vom Airbag-SG angesteuert; Zustand der Lampe wird auf dem CAN-Bus ausgegeben (auch Blinkinformation).";
CM_ SG_ 64 AB_MKB_Anforderung "Anforderung Multi-Kollisions-Bremsung";
CM_ SG_ 64 AB_MKB_gueltig "Multi-Kollisions-Bremsung im Airbag freigeschaltet";
CM_ SG_ 64 AB_PAO_Leuchte_Anf "Anforderung an die Passenger-Airbag-Off Leuchte in der Dachkonsole (ein / aus), Einsatz nur bei PAG";
CM_ SG_ 64 AB_RGS_Anst "PreCrash-Ansteuerung reversibler Gurtstraffer (Aktivierung und Kraftniveau)

10xx = deaktiviert";
CM_ SG_ 64 AB_Rollover_Crash "Wird im B6/B7 Cabrio und New Beetle Cabrio bedient. ";
CM_ SG_ 64 AB_SB_Crash "Z.Zt. nur in Verbindung mit Crash-Intensität >= 100b (Kraftstoffpumpenabschaltung) verwendet.
";
CM_ SG_ 64 AB_SF_Crash "Z.Zt. nur in Verbindung mit Crash-Intensität >= 100b (Kraftstoffpumpenabschaltung) verwendet.";
CM_ SG_ 64 AB_Stellgliedtest "Information, ob Airbag im Stellgliedtest ist, um eine Notrufauflösung beim Stellgliedtest zu verhindern";
CM_ SG_ 64 AB_Systemfehler "Systemfehler Ggf. wird Warnlampe dauernd eingeschaltet.";
CM_ SG_ 64 AB_Texte_AKS "Textanzeige für pyrotechnische Auslösung der aktiven Kopfstütze (AKS)";
CM_ SG_ 64 AB_VB_deaktiviert "Als Option vorgehalten, Beifahrerairbag wurden per Schlüsselschalter oder Insassenerkennung deaktiviert";
CM_ SG_ 64 AB_Versorgungsspannung "Übertragung der Plausibilitätsinformation Kl.15-Last vs. Kl.15-CAN.
Bedienung im Fall Kl.15-Last 'EIN' und Kl.15-CAN 'AUS' mit Ausgabe Warnung/Akustik im Kombi.";
CM_ SG_ 64 Airbag_01_CRC "Für MLB:
'Berechnung siehe Lastenheft 'Kommunikationsabsicherung für FlexRay und CAN''

Ab MQB und MLBevo:
'Berechnung siehe Lastenheft 'End-to-End Kommunikationsabsicherung''

Endwerte siehe Begleitdokument 'S-PDU Kennungsfolgen'";
CM_ SG_ 64 ASM_Masterzeit_02 "Masterzeit für alle ASM Sender";

CM_ SG_ 1312 AB_Abschaltanf_SIH_BF "Die Insassenerkennung auf der Beifahrerseite fordert bei Übertemperatur eine Abschaltung der Sitzheizung an. Die Übertemperatur kann bei niederohmigen Nebenschlüssen der Sitzheizungsmatte als Folge von zu hohem resultierenden Strom auftreten.";
CM_ SG_ 1312 AB_Anforderung_eCall "Trigger für Car2X Steuergerät das ein eCall Ereignis erkannt wurde.";
CM_ SG_ 1312 AB_Anforderung_USM "Trigger für Gateway (OBDC) und MIB/MMI, dass ein USM-Ereignis erkannt wurde.";
CM_ SG_ 1312 AB_Anprall_FGS "Uebermittlung der Lage einer Kollision, Fussgaengerschutz-Aktorik";
CM_ SG_ 1312 AB_Anprall_Front_Beifahrer "Uebermittlung der Lage einer Kollision, Anprallzone Front Beifahrerseite";
CM_ SG_ 1312 AB_Anprall_Front_Fahrer "Uebermittlung der Lage einer Kollision, Anprallzone Front Fahrerseite";
CM_ SG_ 1312 AB_Anprall_Heck_Beifahrer "Uebermittlung der Lage einer Kollision, Anprallzone Beifahrerseite hinten";
CM_ SG_ 1312 AB_Anprall_Heck_Fahrer "Uebermittlung der Lage einer Kollision, Anprallzone Fahrerseite hinten";
CM_ SG_ 1312 AB_Anprall_Rollover "Uebermittlung der Lage einer Kollision, Rollover erkannt";
CM_ SG_ 1312 AB_Anprall_Seite_Beifahrer "Uebermittlung der Lage einer Kollision, Anprallzone Beifahrerseite Seite";
CM_ SG_ 1312 AB_Anprall_Seite_Fahrer "Uebermittlung der Lage einer Kollision, Anprallzone Fahrerseite Seite";
CM_ SG_ 1312 AB_Belegung_VB "Belegungserkennung vorne Beifahrer. Wird in US-Steuergeräten über Bladder-Matte bedient, optional bei RdW, falls SBE_EuroNCAP entschieden wird.";
CM_ SG_ 1312 AB_Crashschwere "Übermittlung der Crashschwere an das Gateway (OBDC)";
CM_ SG_ 1312 AB_Gurtschloss_BF "Gurtschlossstatus Beifahrerseite";
CM_ SG_ 1312 AB_Gurtschloss_FA "Gurtschlosstatatus Fahrerseite";
CM_ SG_ 1312 AB_Gurtschloss_Reihe2_BF "Gurtschlossstatus 2. Reihe Beifahrerseite,  Mehrausstattung";
CM_ SG_ 1312 AB_Gurtschloss_Reihe2_FA "Gurtschlossstatus 2. Reihe Fahrerseite, Mehrausstattung";
CM_ SG_ 1312 AB_Gurtschloss_Reihe2_MI "Gurtschlossstatus 2. Reihe Mitte,  Mehrausstattung";
CM_ SG_ 1312 AB_Gurtschloss_Reihe3_BF "Gurtschlossstatus 3. Reihe Beifahrerseite,  Mehrausstattung";
CM_ SG_ 1312 AB_Gurtschloss_Reihe3_FA "Gurtschlossstatus 3. Reihe Fahrerseite,  Mehrausstattung";
CM_ SG_ 1312 AB_Gurtschloss_Reihe3_MI "Gurtschlossstatus 3. Reihe Mitte,  Mehrausstattung";
CM_ SG_ 1312 AB_Sitzpos_Sens_BF "Ausgabe Sitzposition Beifahrer";
CM_ SG_ 1312 AB_Sitzpos_Sens_FA "Ausgabe Sitzposition Fahrer";
CM_ SG_ 1312 AB_Wickelklappung_Reihe2_BF "Status Wickelklappung 2. Reihe Beifahrerseite, Mehrausstattung";
CM_ SG_ 1312 AB_Wickelklappung_Reihe2_FA "Status Wickelklappung 2. Reihe Fahrerseite, Mehrausstattung";
CM_ SG_ 1312 AB_Wickelklappung_Reihe2_MI "Status Wickelklappung 2. Reihe Mitte, Mehrausstattung";
CM_ SG_ 1312 Airbag_02_CRC "Für MLB:
'Berechnung siehe Lastenheft 'Kommunikationsabsicherung für FlexRay und CAN''

Ab MQB und MLBevo:
'Berechnung siehe Lastenheft 'End-to-End Kommunikationsabsicherung''

Endwerte siehe Begleitdokument 'S-PDU Kennungsfolgen'";
CM_ SG_ 1312 LoGeWa_Event_Kombiwarnung "Event für Kombiwarnung";
CM_ SG_ 1312 SC_PAO_OFF_Anf "Sollwert für LED 'OFF' in Anzeige Passenger Airbag On/Off";
CM_ SG_ 1312 SC_PAO_ON_Anf "Sollwert für LED 'ON' in Anzeige Passenger Airbag On/Off";
CM_ SG_ 1312 SC_PAO_Schriftzug_Anf "Sollwert für LED 'PASSENGER AIRBAG' in Anzeige Passenger Airbag On/Off";

CM_ SG_ 1349 AB_Anprall_Front "Uebermittlung der Lage einer Kollision, Anprallzone Front";
CM_ SG_ 1349 AB_Anprall_Heck "Uebermittlung der Lage einer Kollision, Anprallzone Heck";
CM_ SG_ 1349 AB_Belegung_VF_ext "Das Signal kommuniziert den Status des Sitzbelegsensors Fahrer incl. dauerhafter Zustände mit Signalqualität ASIL A.";
CM_ SG_ 1349 AB_Belegung_VF_ext_aktiv "Kennzeichnet aktive Funktion 'Erweiterte Sitzbelegdiagnose' für Signal AB_Belegung_VF_ext";
CM_ SG_ 1349 AB_Gurtwarn_Reihe2_BF "Status Gurtwarnung 2. Sitzreihe Beifahrerseite";
CM_ SG_ 1349 AB_Gurtwarn_Reihe2_FA "Status Gurtwarnung 2. Sitzreihe Fahrerseite";
CM_ SG_ 1349 AB_Gurtwarn_Reihe2_MI "Status Gurtwarnung 2. Sitzreihe Mitte";
CM_ SG_ 1349 AB_Gurtwarn_Reihe3_BF "Status Gurtwarnung 3. Sitzreihe Beifahrerseite";
CM_ SG_ 1349 AB_Gurtwarn_Reihe3_FA "Status Gurtwarnung 3. Sitzreihe Fahrerseite";
CM_ SG_ 1349 AB_Gurtwarn_Reihe3_MI "Status Gurtwarnung 3. Sitzreihe Mitte";
CM_ SG_ 1349 AB_Gurtwarn_Reihe4_BF "Status Gurtwarnung 4. Sitzreihe Beifahrerseite";
CM_ SG_ 1349 AB_Gurtwarn_Reihe4_FA "Status Gurtwarnung 4. Sitzreihe Fahrerseite";
CM_ SG_ 1349 AB_Gurtwarn_Reihe4_MI "Status Gurtwarnung 4. Sitzreihe Mitte";
CM_ SG_ 1349 AB_SBR_hinten_verbau "Verbauinformation Sitzbelegungssensor hinten (2. und 3. Sitzreihe)";
CM_ SG_ 1349 AbstWarn_MV_FAS_Fkt_Status "FAS-ProfileMaster Iststatus der Kundenfunktion";
CM_ SG_ 1349 Airbag_04_BZ "4bit Botschaftszähler, wird mit jeder Sendebotschaft inkrementiert";
CM_ SG_ 1349 Airbag_04_CRC "Für MLB:
Berechnung siehe Lastenheft 'Kommunikationsabsicherung für FlexRay und CAN'
Ab MQB und MLBevo:
Berechnung siehe Lastenheft 'End-to-End Kommunikationsabsicherung'

Endwerte siehe Begleitdokument 'S-PDU Kennungsfolgen'";
CM_ SG_ 1349 AWV_Einstellung_System_ASG "Signal zur Realisierung des BAP-Koordinators";
CM_ SG_ 1349 AWV_Einstellung_Warnung_ASG "Signal zur Realisierung des BAP-Koordinators";
CM_ SG_ 1349 LGI_FAS_Fkt_Status "FAS-ProfileMaster Iststatus der Kundenfunktion (LGI: Lokale Gefahreninformation)";
CM_ SG_ 1349 PreCrash_FAS_Fkt_Status "FAS-ProfileMaster Iststatus der Kundenfunktion";
CM_ SG_ 1349 SC_PreSense_Modus_System_KAS "BAP-Kommunikation zum Kreuzungsassistent";
CM_ SG_ 1349 SC_PreSense_Modus_System_MV "Signal zur Realisierung der BAP-Kommunikation für PreSense";
CM_ SG_ 1349 SC_PreSense_Modus_System_NV "Signal zur Realisierung der BAP-Kommunikation für PreSense";
CM_ SG_ 1349 SC_PreSense_Modus_Warnung_MV "Signal zur Realisierung der BAP-Kommunikation für PreSense";
CM_ SG_ 1349 SC_PreSense_Modus_Warnung_NV "Signal zur Realisierung der BAP-Kommunikation für PreSense";
CM_ SG_ 1349 WarnBrems_Charisma_FahrPr "Aktuell eingestelltes Fahrprogramm der Funktion Warn- und/oder Notbremsfunktion";
CM_ SG_ 1349 WarnBrems_Charisma_Status "Verfügbarkeit der Funktion Warn- und/oder Notbremsfunktion für die Ansteuerung durch den Charisma-Koordinator.";

CM_ SG_ 2527679722 AB_Anzeige_Kombi_SRAB "Status SRAB HMI";
CM_ SG_ 2527679722 AB_Anzeige_Komfort_HBFS "Komfortposition überschritten HBFS";
CM_ SG_ 2527679722 AB_Anzeige_Komfort_HFS "Komfortposition überschritten HFS";
CM_ SG_ 2527679722 AB_Anzeige_Sitz_Komfort_HBFS "Sitzdisplay Komfortposition überschritten HBFS";
CM_ SG_ 2527679722 AB_Anzeige_Sitz_Komfort_HFS "Sitzdisplay Komfortposition überschritten HFS";
CM_ SG_ 2527679722 AB_Gurtschloss_MI "Gurtschloss-Status 1. Reihe Mitte
Ersteinsetzer: T6PA";
CM_ SG_ 2527679722 AB_Gurtschloss_Reihe4_BF "Gurtschlossstatus 4. Reihe Beifahrerseite,  Mehrausstattung";
CM_ SG_ 2527679722 AB_Gurtschloss_Reihe4_FA "Gurtschlossstatus 4. Reihe Fahrerseite, Mehrausstattung";
CM_ SG_ 2527679722 AB_Gurtschloss_Reihe4_MI "Gurtschlossstatus 4. Reihe Mitte,  Mehrausstattung";
CM_ SG_ 2527679722 AB_Gurtwarn_VM "Beifahrer auf mittlerem Sitz (Nutzfahrzeug) hat Gurt nicht gesteckt, Anzeige im Kombi";
CM_ SG_ 2527679722 AB_Status_Sitz_SRAB_HBFS "Status SRAB Sitzdisplay HBFS";
CM_ SG_ 2527679722 AB_Status_Sitz_SRAB_HFS "Status SRAB Sitzdisplay HFS";
CM_ SG_ 2527679722 AB_wSBR_Batteriestatus "Anzeige einer schwachen Batterie in einer Sitzeinheit des wSBR-Systems im Kombi.";
CM_ SG_ 2527679722 Airbag_06_BZ "4bit Botschaftszähler, wird mit jeder Sendebotschaft inkrementiert";
CM_ SG_ 2527679722 Airbag_06_CRC "Für MLB:
Berechnung siehe Lastenheft 'Kommunikationsabsicherung für FlexRay und CAN'
Ab MQB und MLBevo:
Berechnung siehe Lastenheft 'End-to-End Kommunikationsabsicherung'

Endwerte siehe Begleitdokument 'S-PDU Kennungsfolgen'";

CM_ SG_ 280 ALR_Charisma_FahrPr "MLB: Aktuelles Fahrprogramm des Charisma-Teilnehmers (siehe Systemlastenheft Drive Select)
MQB: Istwert der Kennlinie (siehe Systemlastenheft MQB Charisma)";
CM_ SG_ 280 ALR_Charisma_Status "Systemstatus des Charismateilnehmers

Wert 0x3 ist nur für Fahrzeuge ab MQB relevant
";
CM_ SG_ 280 ALR_Ist_Proz "Istsperrgrad der Längssperre
MQB Haldex: 100% Moment entsprechen 2000 Nm

Allrad_quod:
Im Status Offroad-Lock (Überanpressung der Allradkupplung) wird ALR_ist_Proz = 250 (100%) angezeigt.";
CM_ SG_ 280 ALR_Sendestatus "Gibt den Sendestatus der Längssperre an (notwendig für IL-Unterstützung)";
CM_ SG_ 280 ALR_Sta_Laengssperre "Gibt den Status der Längssperre für andere Systeme an";
CM_ SG_ 280 ALR_Warnlampe "'1', wenn Kuppung aufgrund zu vieler Fehler öffnet.
Aufprüfung der Warnlampe somit nicht möglich.  ";

CM_ SG_ 308 ALR_gMeter_ax "Längsbeschleunigung zur g-Meter-Anzeige im Kombi";
CM_ SG_ 308 ALR_gMeter_ay "Querbeschleunigung zur g-Meter-Anzeige im Kombi";

CM_ SG_ 1633 AAG_Anhaenger_abgesteckt "Anhaenger wurde bei Kl. 15 aus abgesteckt";
CM_ SG_ 1633 AAG_Anhaenger_erkannt "Erkennung Anhaenger ";
CM_ SG_ 1633 AAG_AVS_Fehler_02 "Fehler AVS";
CM_ SG_ 1633 AAG_AVS_Fehler_02_inv "Fehler AVS (inverses Signal)";
CM_ SG_ 1633 AAG_AVS_Stati "Status AVS (bei abnehmbarer oder mech.schwenkbarer Anhängerkupplung ist der Status immer 0)";
CM_ SG_ 1633 AAG_Blinker_H_aktiv "Status: Anhaenger Blinker aktiv";
CM_ SG_ 1633 AAG_Blinker_HL_def "Anhaenger Blinker links defekt";
CM_ SG_ 1633 AAG_Blinker_HR_def "Anhaenger Blinker rechts defekt";
CM_ SG_ 1633 AAG_Bremsl_durch_ECD "Bremslicht durch ECD aktiv";
CM_ SG_ 1633 AAG_Bremslicht_H_def "Anhaenger Bremslicht defekt";
CM_ SG_ 1633 AAG_Bremslicht_Reku "AAG_Bremslicht_Reku meldet zyklisch den empfangenen Zustand des CAN-Signals MO_Bremslicht_Reku zurück.";
CM_ SG_ 1633 AAG_BZ "4bit-Botschaftszaehler, wird in jeder Sendebotschaft inkrementiert

";
CM_ SG_ 1633 AAG_LED_aktiv "Dieses Signal sendet der Beleuchtungsart des Anhängers (LED oder Lampe)
Bei LED aktiv erfolgt kein Kaltüberwachung";
CM_ SG_ 1633 AAG_NSL_aktiv "Anhaenger Nebelschlusslicht aktiv";
CM_ SG_ 1633 AAG_Schlusslicht_HL_def "Anhaenger Schlußlicht links defekt";
CM_ SG_ 1633 AAG_Schlusslicht_HR_def "Anhaenger Schlußlicht rechts defekt";

CM_ SG_ 345 ARA_Aktiver_Grafikmodus "Zeigt an  das eine Grafik für ARA aktiviert werden soll";
CM_ SG_ 345 ARA_Bremsfuss "Anforderung des Bremsfusssymbols im Kombi";
CM_ SG_ 345 ARA_Deaktivierung_sperren "Unterdrückt die Deaktivierung der ARA- Visualisierung";
CM_ SG_ 345 ARA_Knickwinkel_Ist "Gibt den aktuellen Knickwinkel zwischen Anhänger und Fahrzeug wieder";
CM_ SG_ 345 ARA_Knickwinkel_Komfort "Knickwinkelgrenze bis zu der, bei maximalem Lenkeinschlag, eine sofortige gerade Rückwärtsfahrt möglich ist.";
CM_ SG_ 345 ARA_Knickwinkel_Konfidenz "irregular trailer angle area value for HMI display";
CM_ SG_ 345 ARA_Knickwinkel_Max "Gibt den maximalen ausregelbaren Knickwinkel zwischen Anhänger und Fahrzeug wieder.";
CM_ SG_ 345 ARA_Knickwinkel_Soll "Vom Fahrer vorgegebener Knickwinkel.";
CM_ SG_ 345 ARA_Modus "Regelmodus ARA für Kombidarstellung";
CM_ SG_ 345 ARA_Modus_Anf "Anforderung des ARA-Modus im Türsteuergerät";
CM_ SG_ 345 ARA_Sensor_Aktivierung "activation  of ARA IP (image processing)";
CM_ SG_ 345 ARA_Status "Status of ARA Controller";
CM_ SG_ 345 ARA_Texte "Anforderung für Kombianzeigetexte und Akustik";

CM_ SG_ 893 AAG_ASTA_Status "Status ASTA";
CM_ SG_ 893 ASTA_Anhaengerlast "Anzeigewert der Anhaengerlast";
CM_ SG_ 893 ASTA_Einheit "Anzeigeeinheit (kg/lbs) für die Signale ASTA_Anhaengerlast und ASTA_Stuetzlast";
CM_ SG_ 893 ASTA_Stuetzlast "Anzeigewert der Stuetzlast";
CM_ SG_ 893 ASTAs_01_alt "Veraltet Bit für die LIN-Botschaft ASTAs_01";
CM_ SG_ 893 ASTAs_01_upd "Update-Signal für Botschaft ASTAs_01";

CM_ SG_ 2549880935 AuthTime_eCall_Req_Data "AuthTime - Authentische Zeit
ISO-TP Datenkanal - FID2NA
Request Funktion 0x18 AuthTime

Funktion Authentische Zeit an OCU (Request)";

CM_ SG_ 2550012007 AuthTime_eCall_Resp_Data "AuthTime - Authentische Zeit
ISO-TP Datenkanal - FID2NA
Response Knoten 0x67 eCall (OCU)

Knoten OCU an Funktion AuthTime (Response)";

CM_ SG_ 2527679661 AWV_AW_Abstand "Signal dient zur Anzeige des Abstands im Kombi.";
CM_ SG_ 2527679661 AWV_AW_Texte "Signal zur Ansteuerung von Fahrer- und Warnhinweisen des Abstandswarners im Mitteldisplay";
CM_ SG_ 2527679661 AWV_AW_Texte_Zusatzanzeige "Signal zur Ansteuerung von Fahrer- und Warnhinweisen des Abstandswarners im Mitteldisplay";
CM_ SG_ 2527679661 AWV_AW_Zeitluecke "Anzeige der aktuellen Zeitluecke zum vorausfahrenden Fahrzeug (AW == Abstandswarner)";
CM_ SG_ 2527679661 AWV_Einstellung_System_FSG "Signal zur Realisierung des BAP-Koordiantors";
CM_ SG_ 2527679661 AWV_Einstellung_Warnung_FSG "Signal zur Realisierung des BAP-Koordinators";
CM_ SG_ 2527679661 AWV_KA_Konfiguration "Systemstatus Bedienung vom Kreuzungsassistent zum PaCo.";
CM_ SG_ 2527679661 AWV_KA_ObjektFront "Anforderung der MIB Parkenanzeige vom Kreuzungsassistent zum PaCo.";
CM_ SG_ 2527679661 AWV_Kamera_Objekt_ID "Kamera Objekt-ID des AWV-Zielobjekts";
CM_ SG_ 2527679661 AWV_LED_Leiste "Ansteuerung LED Warnleiste";
CM_ SG_ 2527679661 AWV_Priowarnung "Priorisierung der AWV-Warnung über die Spurverlassensanzeige des HCA";
CM_ SG_ 2527679661 AWV_Status_Anzeige "Signal zur Realisierung des BAP-Koordiantors
Signal identisch zu AWV_BAP_Status 
Kl15 aus: nicht bereitgestellt.";
CM_ SG_ 2527679661 AWV_Texte_02 "Hinweisanzeige im Kombi 'Hauptdisplay'
Wert 6 - Eingeschränkte Verfügbarkeit der weiteren Fusionsteilnehmer (z.B. MFK, FER)";
CM_ SG_ 2527679661 AWV_Warnlevel "Warnlevel der Funktion Anhaltewegverkürzung";
CM_ SG_ 2527679661 AWV_Warnung "Hinweisanzeige im Kombi 'Hauptdisplay'";
CM_ SG_ 2527679661 AWV_Warnung_Richtung "Zusätzliche Richtungsanzeige zum Signal AWV_Warnung für die Darstellung im Smartlight und HUD.";
CM_ SG_ 2527679661 WBA_Warnblinken "Ansteuerung des Warnblinkers für die Funktion Warnen, Bremsen, Ausweichen";

CM_ SG_ 2463978752 AZK_Kessy_defekt "Signalisierung der Kessy-Meldung 'Kessy defekt' vom AZK an ein Anzeigeinstrument (Kombiinstrument, I-ID etc.)";
CM_ SG_ 2463978752 AZK_Kessy_nicht_gefunden "Signalisierung der Kessy-Meldung 'Kessy nicht gefunden' vom AZK an ein Anzeigeinstrument (Kombiinstrument, I-ID etc.)";
CM_ SG_ 2463978752 AZK_MobileKey_defekt "Signalisierung der DKM-Meldung 'System Mobile Key defekt' vom AZK an ein Anzeigeinstrument (Kombiinstrument, I-ID etc.)";
CM_ SG_ 2463978752 AZK_Mobilgeraet_nicht_gefunden "Signalisierung der DKM-Meldung 'Mobilgerät nicht gefunden' vom AZK an ein Anzeigeinstrument (Kombiinstrument, I-ID etc.)";
CM_ SG_ 2463978752 AZK_Schluessel_im_Fzg "Signalisierung der Kessy-Meldung 'Schlüssel im Fahrzeug' vom AZK an ein Anzeigeinstrument (Kombiinstrument, I-ID etc.)";
CM_ SG_ 2463978752 AZK_Schluessel_nicht_gefunden "Signalisierung der Meldung 'Schluessel nicht gefunden' der AZK SW-Unit im MDK-ZuKo an ein Anzeigeinstrument (Kombiinstrument, I-ID etc.)";
CM_ SG_ 2463978752 AZK_Weiterfahrt_mit_Mobilgeraet "Signalisierung der DKM-Meldung 'Weiterfahrt mit Mobilgerät möglich' vom AZK an ein Anzeigeinstrument (Kombiinstrument, I-ID etc.)";
CM_ SG_ 2463978752 AZK_Weiterfahrt_mit_Schluessel "Signalisierung der Kessy-Meldung 'Weiterfahrt mit Schlüssel möglich' vom AZK an ein Anzeigeinstrument (Kombiinstrument, I-ID etc.)";

BA_DEF_  "DBName" STRING;
BA_DEF_  "GenNWMApBusSleep" STRING;
BA_DEF_  "GenNWMApCanNormal" STRING;
BA_DEF_  "GenNWMApCanOff" STRING;
BA_DEF_  "GenNWMApCanOn" STRING;
BA_DEF_  "GenNWMApCanSleep" STRING;
BA_DEF_  "GenNWMApCanWakeUp" STRING;
BA_DEF_  "GenNWMGotoMode_Awake" STRING;
BA_DEF_  "GenNWMGotoMode_BusSleep" STRING;
BA_DEF_  "GenNWMSleepTime" INT 0 1000000;
BA_DEF_  "GenNWMTalkNM" STRING;
BA_DEF_  "Manufacturer" STRING;
BA_DEF_  "NmhBaseAddress" HEX 0 536870911;
BA_DEF_  "NmhMessageCount" INT 0 1024;
BA_DEF_  "NmType" STRING;
BA_DEF_  "VAGTP20_SetupMessageCount" INT 0 255;
BA_DEF_  "VAGTP20_SetupStartAddress" HEX 0 2047;
BA_DEF_  "VersionDay" INT 1 31;
BA_DEF_  "VersionMonth" INT 1 12;
BA_DEF_  "VersionWeek" INT 1 52;
BA_DEF_  "VersionYear" INT 0 99;
BA_DEF_  "VersionNumber" INT 0 65535;
BA_DEF_  "BusType" STRING;
BA_DEF_  "Baudrate" INT 1 1000000;
BA_DEF_  "BaudrateCANFD" INT 1 16000000;
BA_DEF_  "NmhTimeoutTimer" INT 0 65535;
BA_DEF_  "NmhWaitBusSleepTimer" INT 0 65535;
BA_DEF_  "NmhPrepareBusSleepTimer" INT 0 65535;
BA_DEF_  "NmhLongTimer" INT 0 65535;
BA_DEF_  "NmhNStart" INT 0 255;
BA_DEF_ BU_  "GenNodAutoGenDsp" ENUM "No", "Yes";
BA_DEF_ BU_  "GenNodAutoGenSnd" ENUM "No", "Yes";
BA_DEF_ BU_  "GenNodSleepTime" INT 0 1000000;
BA_DEF_ BU_  "ILUsed" ENUM "No", "Yes";
BA_DEF_ BU_  "ECUVariantDefault" ENUM "No", "Yes";
BA_DEF_ BU_  "ECUVariantGroup" STRING;
BA_DEF_ BU_  "NodeLayerModules" STRING;
BA_DEF_ BU_  "NmhNode" ENUM "No", "Yes";
BA_DEF_ BU_  "NmNode" ENUM "No", "Yes";
BA_DEF_ BU_  "SamplePointMin" FLOAT 50.0 99.9;
BA_DEF_ BU_  "SamplePointMax" FLOAT 50.0 99.9;
BA_DEF_ BU_  "SyncJumpWidthMin" FLOAT 0.0 50.0;
BA_DEF_ BU_  "SyncJumpWidthMax" FLOAT 0.0 50.0;
BA_DEF_ BU_  "SyncJumpWidthCANFDMin" FLOAT 0.0 50.0;
BA_DEF_ BU_  "SyncJumpWidthCANFDMax" FLOAT 0.0 50.0;
BA_DEF_ BU_  "SamplePointCANFDMin" FLOAT 50.0 99.9;
BA_DEF_ BU_  "SamplePointCANFDMax" FLOAT 50.0 99.9;
BA_DEF_ BU_  "SSPOffsetCANFDMin" FLOAT 50.0 99.9;
BA_DEF_ BU_  "SSPOffsetCANFDMax" FLOAT 50.0 99.9;
BA_DEF_ BU_  "TimeQuantaMin" INT 4 257;
BA_DEF_ BU_  "TimeQuantaMax" INT 4 257;
BA_DEF_ BU_  "TimeQuantaCANFDMin" INT 4 257;
BA_DEF_ BU_  "TimeQuantaCANFDMax" INT 4 257;
BA_DEF_REL_ BU_SG_REL_  "GenSigTimeoutTime" INT 0 65535;
BA_DEF_ BO_  "DiagRequest" ENUM "No", "Yes";
BA_DEF_ BO_  "DiagResponse" ENUM "No", "Yes";
BA_DEF_ BO_  "DiagState" ENUM "No", "Yes";
BA_DEF_ BO_  "GenMsgChkConstant" HEX 0 4095;
BA_DEF_ BO_  "GenMsgCycleTime" INT 0 65535;
BA_DEF_ BO_  "GenMsgCycleTimeFast" INT 0 65535;
BA_DEF_ BO_  "GenMsgDelayTime" INT 0 100000;
BA_DEF_ BO_  "GenMsgILSupport" ENUM "No", "Yes";
BA_DEF_ BO_  "GenMsgNrOfRepetition" INT 0 100;
BA_DEF_ BO_  "GenMsgPDUConstants" STRING;
BA_DEF_ BO_  "GenMsgSendType" ENUM "Cyclic", "not_used", "not_used", "not_used", "not_used", "not_used", "not_used", "IfActive", "NoMsgSendType";
BA_DEF_ BO_  "GenMsgStartDelayTime" INT 0 100000;
BA_DEF_ BO_  "NmMessage" ENUM "No", "Yes";
BA_DEF_ BO_  "NmhMessage" ENUM "No", "Yes";
BA_DEF_ BO_  "MsgType" ENUM "Application", "NM ", "NMH", "TP2.0", "ISO-TP ", "BAP", "EID", "KS", "XCP_PRE_CONFIGURED", "XCP_RUNTIME_CONFIGURED";
BA_DEF_ BO_  "VAGTP20_API" HEX 0 255;
BA_DEF_ BO_  "VAGTP20_DynConnection" ENUM "No", "Yes";
BA_DEF_ BO_  "VAGTP20_DynSetup" ENUM "No", "Yes";
BA_DEF_ BO_  "VAGTP20_StatConnection" ENUM "No", "Yes";
BA_DEF_ BO_  "CANFD_BRS" ENUM "0", "1";
BA_DEF_ BO_  "VFrameFormat" ENUM "StandardCAN", "ExtendedCAN", "reserved", "reserved", "reserved", "reserved", "reserved", "reserved", "reserved", "reserved", "reserved", "reserved", "reserved", "reserved", "StandardCAN_FD", "ExtendedCAN_FD";
BA_DEF_ SG_  "GenSigActiveRepetitions" INT -2147483648 2147483647;
BA_DEF_ SG_  "GenSigInactiveValue" INT -2147483648 2147483647;
BA_DEF_ SG_  "GenSigSendType" ENUM "Cyclic", "OnWrite", "OnWriteWithRepetition", "OnChange", "OnChangeWithRepetition", "IfActive", "IfActiveWithRepetition", "NoSigSendType", "OnChangeAndIfActive", "OnChangeAndIfActiveWithRepetition";
BA_DEF_ SG_  "GenSigStartValue" INT -2147483648 2147483647;
BA_DEF_ SG_  "NWM-WakeupAllowed" ENUM "No", "Yes";
BA_DEF_ SG_  "GenSigFuncType" ENUM "NoFunction", "MsgCounter", "CRC-8", "XOR", "XOR-2", "DatedBit", "SW-Kl15", "CHK", "Constant", "Protocol", "CRC-8-SAE_J1850", "CRC-32", "DataLength", "DataID", "MsgCounter16", "SOK-Signatur", "Cluster";
BA_DEF_ SG_  "GenSigSwitchedByIgnition" ENUM "No", "Yes";
BA_DEF_ SG_  "Fehlerwert" HEX 0 2147483647;
BA_DEF_ SG_  "GenSigMissingSourceValue" HEX 0 2147483647;
BA_DEF_DEF_  "DBName" "";
BA_DEF_DEF_  "GenNWMApBusSleep" "";
BA_DEF_DEF_  "GenNWMApCanNormal" "";
BA_DEF_DEF_  "GenNWMApCanOff" "";
BA_DEF_DEF_  "GenNWMApCanOn" "";
BA_DEF_DEF_  "GenNWMApCanSleep" "";
BA_DEF_DEF_  "GenNWMApCanWakeUp" "";
BA_DEF_DEF_  "GenNWMGotoMode_Awake" "";
BA_DEF_DEF_  "GenNWMGotoMode_BusSleep" "";
BA_DEF_DEF_  "GenNWMSleepTime" 0;
BA_DEF_DEF_  "GenNWMTalkNM" "";
BA_DEF_DEF_  "Manufacturer" "";
BA_DEF_DEF_  "NmhBaseAddress" 0;
BA_DEF_DEF_  "NmhMessageCount" 1;
BA_DEF_DEF_  "NmType" "None";
BA_DEF_DEF_  "VAGTP20_SetupMessageCount" 0;
BA_DEF_DEF_  "VAGTP20_SetupStartAddress" 0;
BA_DEF_DEF_  "VersionDay" 12;
BA_DEF_DEF_  "VersionMonth" 6;
BA_DEF_DEF_  "VersionWeek" 24;
BA_DEF_DEF_  "VersionYear" 23;
BA_DEF_DEF_  "VersionNumber" 0;
BA_DEF_DEF_  "BusType" "";
BA_DEF_DEF_  "Baudrate" 500000;
BA_DEF_DEF_  "BaudrateCANFD" 2000000;
BA_DEF_DEF_  "NmhTimeoutTimer" 0;
BA_DEF_DEF_  "NmhWaitBusSleepTimer" 0;
BA_DEF_DEF_  "NmhPrepareBusSleepTimer" 0;
BA_DEF_DEF_  "NmhLongTimer" 0;
BA_DEF_DEF_  "NmhNStart" 0;
BA_DEF_DEF_  "GenNodAutoGenDsp" "Yes";
BA_DEF_DEF_  "GenNodAutoGenSnd" "Yes";
BA_DEF_DEF_  "GenNodSleepTime" 0;
BA_DEF_DEF_  "ILUsed" "Yes";
BA_DEF_DEF_  "ECUVariantDefault" "Yes";
BA_DEF_DEF_  "ECUVariantGroup" "";
BA_DEF_DEF_  "NodeLayerModules" "";
BA_DEF_DEF_  "NmhNode" "Yes";
BA_DEF_DEF_  "NmNode" "No";
BA_DEF_DEF_  "SamplePointMin" 75;
BA_DEF_DEF_  "SamplePointMax" 75;
BA_DEF_DEF_  "SyncJumpWidthMin" 50;
BA_DEF_DEF_  "SyncJumpWidthMax" 50;
BA_DEF_DEF_  "SyncJumpWidthCANFDMin" 50;
BA_DEF_DEF_  "SyncJumpWidthCANFDMax" 50;
BA_DEF_DEF_  "SamplePointCANFDMin" 75;
BA_DEF_DEF_  "SamplePointCANFDMax" 75;
BA_DEF_DEF_  "SSPOffsetCANFDMin" 75;
BA_DEF_DEF_  "SSPOffsetCANFDMax" 75;
BA_DEF_DEF_  "TimeQuantaMin" 160;
BA_DEF_DEF_  "TimeQuantaMax" 160;
BA_DEF_DEF_  "TimeQuantaCANFDMin" 40;
BA_DEF_DEF_  "TimeQuantaCANFDMax" 40;
BA_DEF_DEF_REL_  "GenSigTimeoutTime" 0;
BA_DEF_DEF_  "DiagRequest" "No";
BA_DEF_DEF_  "DiagResponse" "No";
BA_DEF_DEF_  "DiagState" "No";
BA_DEF_DEF_  "GenMsgChkConstant" 0;
BA_DEF_DEF_  "GenMsgCycleTime" 0;
BA_DEF_DEF_  "GenMsgCycleTimeFast" 0;
BA_DEF_DEF_  "GenMsgDelayTime" 0;
BA_DEF_DEF_  "GenMsgILSupport" "No";
BA_DEF_DEF_  "GenMsgNrOfRepetition" 0;
BA_DEF_DEF_  "GenMsgPDUConstants" "";
BA_DEF_DEF_  "GenMsgSendType" "NoMsgSendType";
BA_DEF_DEF_  "GenMsgStartDelayTime" 0;
BA_DEF_DEF_  "NmMessage" "No";
BA_DEF_DEF_  "NmhMessage" "No";
BA_DEF_DEF_  "MsgType" "Application";
BA_DEF_DEF_  "VAGTP20_API" 0;
BA_DEF_DEF_  "VAGTP20_DynConnection" "No";
BA_DEF_DEF_  "VAGTP20_DynSetup" "No";
BA_DEF_DEF_  "VAGTP20_StatConnection" "No";
BA_DEF_DEF_  "CANFD_BRS" "1";
BA_DEF_DEF_  "VFrameFormat" "StandardCAN";
BA_DEF_DEF_  "GenSigActiveRepetitions" 0;
BA_DEF_DEF_  "GenSigInactiveValue" 0;
BA_DEF_DEF_  "GenSigSendType" "NoSigSendType";
BA_DEF_DEF_  "GenSigStartValue" 0;
BA_DEF_DEF_  "NWM-WakeupAllowed" "No";
BA_DEF_DEF_  "GenSigFuncType" "NoFunction";
BA_DEF_DEF_  "GenSigSwitchedByIgnition" "Yes";
BA_DEF_DEF_  "Fehlerwert" 0;
BA_DEF_DEF_  "GenSigMissingSourceValue" 0;
BA_  "DBName" "K3CANFD";
BA_  "GenNWMApBusSleep" "NMIndNetSDN()";
BA_  "GenNWMApCanNormal" "apCanNormal()";
BA_  "GenNWMApCanOff" "NMIndnetOff()";
BA_  "GenNWMApCanOn" "NMIndnetOn()";
BA_  "GenNWMApCanSleep" "apCanSleep()";
BA_  "GenNWMApCanWakeUp" "apCanWakeUp()";
BA_  "GenNWMGotoMode_Awake" "Nmh_ReqNetOn()";
BA_  "GenNWMGotoMode_BusSleep" "Nmh_ReqNetOff()";
BA_  "GenNWMSleepTime" 4000;
BA_  "GenNWMTalkNM" "Nmh_ReqNetOn()";
BA_  "Manufacturer" "VAG";
BA_  "NmhBaseAddress" 452984832;
BA_  "NmhMessageCount" 1024;
BA_  "NmType" "NM-High";
BA_  "VAGTP20_SetupMessageCount" 128;
BA_  "VAGTP20_SetupStartAddress" 512;
BA_  "VersionNumber" 9;
BA_  "BusType" "CAN FD";
BA_  "BaudrateCANFD" 1000000;
BA_  "NmhTimeoutTimer" 1000;
BA_  "NmhWaitBusSleepTimer" 750;
BA_  "NmhPrepareBusSleepTimer" 500;
BA_  "NmhLongTimer" 200;
BA_  "NmhNStart" 20;
BA_ "GenNodSleepTime" BU_ BAP_Tester 4000;
BA_ "ECUVariantGroup" BU_ BAP_Tester "BAP";
BA_ "NmhNode" BU_ BAP_Tester 0;
BA_ "SamplePointMin" BU_ BAP_Tester 80;
BA_ "SamplePointMax" BU_ BAP_Tester 80;
BA_ "SyncJumpWidthMin" BU_ BAP_Tester 8;
BA_ "SyncJumpWidthMax" BU_ BAP_Tester 8;
BA_ "SyncJumpWidthCANFDMin" BU_ BAP_Tester 6;
BA_ "SyncJumpWidthCANFDMax" BU_ BAP_Tester 6;
BA_ "SamplePointCANFDMin" BU_ BAP_Tester 70;
BA_ "SamplePointCANFDMax" BU_ BAP_Tester 70;
BA_ "SSPOffsetCANFDMin" BU_ BAP_Tester 70;
BA_ "SSPOffsetCANFDMax" BU_ BAP_Tester 70;
BA_ "TimeQuantaMin" BU_ BAP_Tester 40;
BA_ "TimeQuantaMax" BU_ BAP_Tester 40;
BA_ "TimeQuantaCANFDMin" BU_ BAP_Tester 20;
BA_ "TimeQuantaCANFDMax" BU_ BAP_Tester 20;
BA_ "GenNodSleepTime" BU_ ELV 4000;
BA_ "NodeLayerModules" BU_ ELV "NMHigh.DLL";
BA_ "SamplePointMin" BU_ ELV 80;
BA_ "SamplePointMax" BU_ ELV 80;
BA_ "SyncJumpWidthMin" BU_ ELV 8;
BA_ "SyncJumpWidthMax" BU_ ELV 8;
BA_ "SyncJumpWidthCANFDMin" BU_ ELV 6;
BA_ "SyncJumpWidthCANFDMax" BU_ ELV 6;
BA_ "SamplePointCANFDMin" BU_ ELV 70;
BA_ "SamplePointCANFDMax" BU_ ELV 70;
BA_ "SSPOffsetCANFDMin" BU_ ELV 70;
BA_ "SSPOffsetCANFDMax" BU_ ELV 70;
BA_ "TimeQuantaMin" BU_ ELV 40;
BA_ "TimeQuantaMax" BU_ ELV 40;
BA_ "TimeQuantaCANFDMin" BU_ ELV 20;
BA_ "TimeQuantaCANFDMax" BU_ ELV 20;
BA_ "GenNodSleepTime" BU_ Gateway_Max 4000;
BA_ "ECUVariantGroup" BU_ Gateway_Max "Gateway";
BA_ "NodeLayerModules" BU_ Gateway_Max "NMHigh.DLL";
BA_ "SamplePointMin" BU_ Gateway_Max 80;
BA_ "SamplePointMax" BU_ Gateway_Max 80;
BA_ "SyncJumpWidthMin" BU_ Gateway_Max 8;
BA_ "SyncJumpWidthMax" BU_ Gateway_Max 8;
BA_ "SyncJumpWidthCANFDMin" BU_ Gateway_Max 6;
BA_ "SyncJumpWidthCANFDMax" BU_ Gateway_Max 6;
BA_ "SamplePointCANFDMin" BU_ Gateway_Max 70;
BA_ "SamplePointCANFDMax" BU_ Gateway_Max 70;
BA_ "SSPOffsetCANFDMin" BU_ Gateway_Max 70;
BA_ "SSPOffsetCANFDMax" BU_ Gateway_Max 70;
BA_ "TimeQuantaMin" BU_ Gateway_Max 40;
BA_ "TimeQuantaMax" BU_ Gateway_Max 40;
BA_ "TimeQuantaCANFDMin" BU_ Gateway_Max 20;
BA_ "TimeQuantaCANFDMax" BU_ Gateway_Max 20;
BA_ "GenNodSleepTime" BU_ HUD 4000;
BA_ "NodeLayerModules" BU_ HUD "NMHigh.DLL";
BA_ "SamplePointMin" BU_ HUD 80;
BA_ "SamplePointMax" BU_ HUD 80;
BA_ "SyncJumpWidthMin" BU_ HUD 8;
BA_ "SyncJumpWidthMax" BU_ HUD 8;
BA_ "SyncJumpWidthCANFDMin" BU_ HUD 6;
BA_ "SyncJumpWidthCANFDMax" BU_ HUD 6;
BA_ "SamplePointCANFDMin" BU_ HUD 70;
BA_ "SamplePointCANFDMax" BU_ HUD 70;
BA_ "SSPOffsetCANFDMin" BU_ HUD 70;
BA_ "SSPOffsetCANFDMax" BU_ HUD 70;
BA_ "TimeQuantaMin" BU_ HUD 40;
BA_ "TimeQuantaMax" BU_ HUD 40;
BA_ "TimeQuantaCANFDMin" BU_ HUD 20;
BA_ "TimeQuantaCANFDMax" BU_ HUD 20;
BA_ "GenNodSleepTime" BU_ Kombi 4000;
BA_ "NodeLayerModules" BU_ Kombi "NMHigh.DLL";
BA_ "SamplePointMin" BU_ Kombi 80;
BA_ "SamplePointMax" BU_ Kombi 80;
BA_ "SyncJumpWidthMin" BU_ Kombi 8;
BA_ "SyncJumpWidthMax" BU_ Kombi 8;
BA_ "SyncJumpWidthCANFDMin" BU_ Kombi 6;
BA_ "SyncJumpWidthCANFDMax" BU_ Kombi 6;
BA_ "SamplePointCANFDMin" BU_ Kombi 70;
BA_ "SamplePointCANFDMax" BU_ Kombi 70;
BA_ "SSPOffsetCANFDMin" BU_ Kombi 70;
BA_ "SSPOffsetCANFDMax" BU_ Kombi 70;
BA_ "TimeQuantaMin" BU_ Kombi 40;
BA_ "TimeQuantaMax" BU_ Kombi 40;
BA_ "TimeQuantaCANFDMin" BU_ Kombi 20;
BA_ "TimeQuantaCANFDMax" BU_ Kombi 20;
BA_ "GenMsgCycleTime" BO_ 2589283940 1000;
BA_ "GenMsgCycleTimeFast" BO_ 2589283940 100;
BA_ "GenMsgDelayTime" BO_ 2589283940 50;
BA_ "GenMsgILSupport" BO_ 2589283940 1;
BA_ "GenMsgNrOfRepetition" BO_ 2589283940 5;
BA_ "GenMsgSendType" BO_ 2589283940 0;
BA_ "VFrameFormat" BO_ 2589283940 15;
BA_ "GenMsgCycleTime" BO_ 768 60;
BA_ "GenMsgILSupport" BO_ 768 1;
BA_ "GenMsgSendType" BO_ 768 0;
BA_ "VFrameFormat" BO_ 768 14;
BA_ "GenMsgCycleTime" BO_ 859 80;
BA_ "GenMsgILSupport" BO_ 859 1;
BA_ "GenMsgSendType" BO_ 859 0;
BA_ "VFrameFormat" BO_ 859 14;
BA_ "GenMsgCycleTime" BO_ 2331595990 1000;
BA_ "GenMsgILSupport" BO_ 2331595990 1;
BA_ "GenMsgSendType" BO_ 2331595990 0;
BA_ "VFrameFormat" BO_ 2331595990 15;
BA_ "GenMsgCycleTime" BO_ 2331596021 1000;
BA_ "GenMsgILSupport" BO_ 2331596021 1;
BA_ "GenMsgSendType" BO_ 2331596021 0;
BA_ "VFrameFormat" BO_ 2331596021 15;
BA_ "GenMsgCycleTime" BO_ 2527679923 960;
BA_ "GenMsgCycleTimeFast" BO_ 2527679923 40;
BA_ "GenMsgDelayTime" BO_ 2527679923 40;
BA_ "GenMsgILSupport" BO_ 2527679923 1;
BA_ "GenMsgNrOfRepetition" BO_ 2527679923 10;
BA_ "GenMsgSendType" BO_ 2527679923 0;
BA_ "VFrameFormat" BO_ 2527679923 15;
BA_ "GenMsgCycleTime" BO_ 1660 1000;
BA_ "GenMsgDelayTime" BO_ 1660 100;
BA_ "GenMsgILSupport" BO_ 1660 1;
BA_ "GenMsgSendType" BO_ 1660 0;
BA_ "VFrameFormat" BO_ 1660 14;
BA_ "GenMsgChkConstant" BO_ 64 64;
BA_ "GenMsgCycleTime" BO_ 64 40;
BA_ "GenMsgCycleTimeFast" BO_ 64 10;
BA_ "GenMsgDelayTime" BO_ 64 10;
BA_ "GenMsgILSupport" BO_ 64 1;
BA_ "GenMsgNrOfRepetition" BO_ 64 5;
BA_ "GenMsgPDUConstants" BO_ 64 "0x40,0x40,0x40,0x40,0x40,0x40,0x40,0x40,0x40,0x40,0x40,0x40,0x40,0x40,0x40,0x40";
BA_ "GenMsgSendType" BO_ 64 0;
BA_ "VFrameFormat" BO_ 64 14;
BA_ "GenMsgChkConstant" BO_ 1312 68;
BA_ "GenMsgCycleTime" BO_ 1312 200;
BA_ "GenMsgDelayTime" BO_ 1312 20;
BA_ "GenMsgILSupport" BO_ 1312 1;
BA_ "GenMsgPDUConstants" BO_ 1312 "0x44,0x44,0x44,0x44,0x44,0x44,0x44,0x44,0x44,0x44,0x44,0x44,0x44,0x44,0x44,0x44";
BA_ "GenMsgSendType" BO_ 1312 0;
BA_ "VFrameFormat" BO_ 1312 14;
BA_ "GenMsgCycleTime" BO_ 1349 200;
BA_ "GenMsgDelayTime" BO_ 1349 40;
BA_ "GenMsgILSupport" BO_ 1349 1;
BA_ "GenMsgPDUConstants" BO_ 1349 "0x95,0x19,0xd1,0x36,0x89,0xd4,0x02,0x1e,0xb9,0x80,0xd0,0x22,0x8a,0xf4,0x15,0xb8";
BA_ "GenMsgSendType" BO_ 1349 0;
BA_ "VFrameFormat" BO_ 1349 14;
BA_ "GenMsgCycleTime" BO_ 2527679722 200;
BA_ "GenMsgILSupport" BO_ 2527679722 1;
BA_ "GenMsgPDUConstants" BO_ 2527679722 "0x81,0x55,0xf0,0x94,0x56,0x5f,0xa4,0x5c,0x2f,0x61,0x48,0x01,0xf8,0xd7,0x33,0x87";
BA_ "GenMsgSendType" BO_ 2527679722 0;
BA_ "VFrameFormat" BO_ 2527679722 15;
BA_ "GenMsgCycleTime" BO_ 280 100;
BA_ "GenMsgCycleTimeFast" BO_ 280 10;
BA_ "GenMsgDelayTime" BO_ 280 10;
BA_ "GenMsgILSupport" BO_ 280 1;
BA_ "GenMsgNrOfRepetition" BO_ 280 5;
BA_ "GenMsgSendType" BO_ 280 0;
BA_ "VFrameFormat" BO_ 280 14;
BA_ "GenMsgCycleTime" BO_ 308 20;
BA_ "GenMsgILSupport" BO_ 308 1;
BA_ "GenMsgSendType" BO_ 308 0;
BA_ "VFrameFormat" BO_ 308 14;
BA_ "GenMsgCycleTime" BO_ 1633 100;
BA_ "GenMsgILSupport" BO_ 1633 1;
BA_ "GenMsgSendType" BO_ 1633 0;
BA_ "VFrameFormat" BO_ 1633 14;
BA_ "GenMsgCycleTime" BO_ 345 100;
BA_ "GenMsgDelayTime" BO_ 345 10;
BA_ "GenMsgILSupport" BO_ 345 1;
BA_ "GenMsgSendType" BO_ 345 0;
BA_ "VFrameFormat" BO_ 345 14;
BA_ "GenMsgCycleTime" BO_ 893 500;
BA_ "GenMsgILSupport" BO_ 893 1;
BA_ "GenMsgSendType" BO_ 893 0;
BA_ "VFrameFormat" BO_ 893 14;
BA_ "MsgType" BO_ 2549880935 4;
BA_ "VFrameFormat" BO_ 2549880935 15;
BA_ "MsgType" BO_ 2550012007 4;
BA_ "VFrameFormat" BO_ 2550012007 15;
BA_ "GenMsgCycleTime" BO_ 2527679661 200;
BA_ "GenMsgDelayTime" BO_ 2527679661 40;
BA_ "GenMsgILSupport" BO_ 2527679661 1;
BA_ "GenMsgSendType" BO_ 2527679661 0;
BA_ "VFrameFormat" BO_ 2527679661 15;
BA_ "GenMsgCycleTime" BO_ 2463978752 1000;
BA_ "GenMsgCycleTimeFast" BO_ 2463978752 100;
BA_ "GenMsgDelayTime" BO_ 2463978752 50;
BA_ "GenMsgILSupport" BO_ 2463978752 1;
BA_ "GenMsgNrOfRepetition" BO_ 2463978752 5;
BA_ "GenMsgSendType" BO_ 2463978752 0;
BA_ "VFrameFormat" BO_ 2463978752 15;
BA_ "GenSigSendType" SG_ 2589283940 AC_FES_Aktive_Atmosphere 4;
BA_ "GenSigSwitchedByIgnition" SG_ 2589283940 AC_FES_Aktive_Atmosphere 0;
BA_ "GenSigSendType" SG_ 2589283940 AC_FES_Atmosphere_1 0;
BA_ "GenSigSwitchedByIgnition" SG_ 2589283940 AC_FES_Atmosphere_1 0;
BA_ "GenSigSendType" SG_ 2589283940 AC_FES_Atmosphere_2 0;
BA_ "GenSigSwitchedByIgnition" SG_ 2589283940 AC_FES_Atmosphere_2 0;
BA_ "GenSigSendType" SG_ 2589283940 AC_FES_Atmosphere_3 0;
BA_ "GenSigSwitchedByIgnition" SG_ 2589283940 AC_FES_Atmosphere_3 0;
BA_ "GenSigSendType" SG_ 2589283940 AC_FES_Atmosphere_4 0;
BA_ "GenSigSwitchedByIgnition" SG_ 2589283940 AC_FES_Atmosphere_4 0;
BA_ "GenSigSendType" SG_ 2589283940 AC_FES_Atmosphere_5 0;
BA_ "GenSigSwitchedByIgnition" SG_ 2589283940 AC_FES_Atmosphere_5 0;
BA_ "GenSigSendType" SG_ 2589283940 AC_FES_Atmosphere_6 0;
BA_ "GenSigSwitchedByIgnition" SG_ 2589283940 AC_FES_Atmosphere_6 0;
BA_ "GenSigSendType" SG_ 2589283940 AC_FES_Atmosphere_7 0;
BA_ "GenSigSwitchedByIgnition" SG_ 2589283940 AC_FES_Atmosphere_7 0;
BA_ "GenSigSendType" SG_ 2589283940 AC_KBI_Sec_View_Request 4;
BA_ "GenSigSwitchedByIgnition" SG_ 2589283940 AC_KBI_Sec_View_Request 0;
BA_ "GenSigSendType" SG_ 2589283940 AC_KBI_View_Request 4;
BA_ "GenSigSwitchedByIgnition" SG_ 2589283940 AC_KBI_View_Request 0;
BA_ "GenSigSendType" SG_ 768 AbstWarn_LRR_FAS_Fkt_Status 0;
BA_ "Fehlerwert" SG_ 768 AbstWarn_LRR_FAS_Fkt_Status 3;
BA_ "GenSigSendType" SG_ 768 ACA_Hinweistexte 0;
BA_ "GenSigSendType" SG_ 768 ACA_Querfuehrung 0;
BA_ "GenSigSendType" SG_ 768 ACA_Querfuehrung_Texte 0;
BA_ "GenSigSendType" SG_ 768 ACC_Abstand_Abstandswarner 0;
BA_ "GenSigStartValue" SG_ 768 ACC_Abstand_Abstandswarner 511;
BA_ "GenSigSendType" SG_ 768 ACC_Abstand_LNS 0;
BA_ "GenSigSendType" SG_ 768 ACC_Abstand_RNS 0;
BA_ "GenSigSendType" SG_ 768 ACC_Abstand_WZO 0;
BA_ "GenSigSendType" SG_ 768 ACC_Abstandsindex_02 0;
BA_ "GenSigSendType" SG_ 768 ACC_Akustik_03 0;
BA_ "GenSigSendType" SG_ 768 ACC_Anzeige_Maximalabstand 0;
BA_ "GenSigSendType" SG_ 768 ACC_Anzeige_Objektregelung 0;
BA_ "GenSigSendType" SG_ 768 ACC_Anzeige_Zeitluecke 0;
BA_ "GenSigSendType" SG_ 768 ACC_Display_Prio 0;
BA_ "GenSigSendType" SG_ 768 ACC_EGO_Fahrzeug 0;
BA_ "GenSigSendType" SG_ 768 ACC_Einheit_Abstandswarner 0;
BA_ "GenSigSendType" SG_ 768 ACC_Einheit_maxSetzgeschw 0;
BA_ "GenSigSendType" SG_ 768 ACC_ENG_Texte 0;
BA_ "GenSigSendType" SG_ 768 ACC_ENG_Texte_02 0;
BA_ "GenSigSendType" SG_ 768 ACC_FoD_Status 0;
BA_ "GenSigSendType" SG_ 768 ACC_FzgStatus_Anfahrbereitschaft 0;
BA_ "GenSigSendType" SG_ 768 ACC_FzgStatus_Fehleranzeige 0;
BA_ "GenSigSendType" SG_ 768 ACC_FzgStatus_Kamerafusion 0;
BA_ "GenSigSendType" SG_ 768 ACC_Geschw_Zielfahrzeug 0;
BA_ "NWM-WakeupAllowed" SG_ 768 ACC_Geschw_Zielfahrzeug 1;
BA_ "GenSigSendType" SG_ 768 ACC_Gesetzte_Zeitluecke 0;
BA_ "GenSigSendType" SG_ 768 ACC_iBoost_Anzeige 0;
BA_ "GenSigSendType" SG_ 768 ACC_Kurvenassistent 0;
BA_ "GenSigSendType" SG_ 768 ACC_maxRegelgeschw 0;
BA_ "GenSigStartValue" SG_ 768 ACC_maxRegelgeschw 255;
BA_ "GenSigSendType" SG_ 768 ACC_maxSetzgeschw 0;
BA_ "GenSigStartValue" SG_ 768 ACC_maxSetzgeschw 511;
BA_ "GenSigSendType" SG_ 768 ACC_minRegelgeschw 0;
BA_ "GenSigStartValue" SG_ 768 ACC_minRegelgeschw 255;
BA_ "GenSigSendType" SG_ 768 ACC_Modus_Pop_Up 0;
BA_ "GenSigSwitchedByIgnition" SG_ 768 ACC_Modus_Pop_Up 0;
BA_ "GenSigSendType" SG_ 768 ACC_Optischer_Fahrerhinweis 0;
BA_ "GenSigSendType" SG_ 768 ACC_Regelgeschw 0;
BA_ "GenSigStartValue" SG_ 768 ACC_Regelgeschw 1023;
BA_ "GenSigSendType" SG_ 768 ACC_Regelung_AIO 0;
BA_ "GenSigSendType" SG_ 768 ACC_rel_Objekt_Zusatzanz 0;
BA_ "GenSigSendType" SG_ 768 ACC_Relevantes_Objekt_02 0;
BA_ "GenSigSendType" SG_ 768 ACC_RUV 0;
BA_ "GenSigSendType" SG_ 768 ACC_Sollabstand_1 0;
BA_ "GenSigSendType" SG_ 768 ACC_Sollabstand_2 0;
BA_ "GenSigSendType" SG_ 768 ACC_Sollabstand_3 0;
BA_ "GenSigSendType" SG_ 768 ACC_Sollabstand_4 0;
BA_ "GenSigSendType" SG_ 768 ACC_Sollabstand_5 0;
BA_ "GenSigSendType" SG_ 768 ACC_STA_Text 0;
BA_ "GenSigSendType" SG_ 768 ACC_Status_Anzeige 0;
BA_ "GenSigSendType" SG_ 768 ACC_Status_GRA_Modus 0;
BA_ "GenSigSendType" SG_ 768 ACC_Status_Stauende 0;
BA_ "GenSigSwitchedByIgnition" SG_ 768 ACC_Status_Stauende 0;
BA_ "GenSigSendType" SG_ 768 ACC_Statusicon 0;
BA_ "GenSigSendType" SG_ 768 ACC_Tachokranz 0;
BA_ "GenSigSendType" SG_ 768 ACC_Tempolimit 0;
BA_ "GenSigSendType" SG_ 768 ACC_Tempolimit_Einheit 0;
BA_ "GenSigSendType" SG_ 768 ACC_Tempolimitassistent_02 0;
BA_ "GenSigSendType" SG_ 768 ACC_Texte_02 0;
BA_ "GenSigSendType" SG_ 768 ACC_Texte_03 0;
BA_ "GenSigSendType" SG_ 768 ACC_Texte_Abstandswarner 0;
BA_ "GenSigSendType" SG_ 768 ACC_Texte_Primaeranz_03 0;
BA_ "GenSigSendType" SG_ 768 ACC_Texte_Sekundaeranz 0;
BA_ "GenSigSendType" SG_ 768 ACC_Texte_Sekundaeranz_02 0;
BA_ "GenSigSendType" SG_ 768 ACC_Texte_Sekundaeranz_03 0;
BA_ "GenSigSendType" SG_ 768 ACC_Texte_Zusatzanz_03 0;
BA_ "GenSigSendType" SG_ 768 ACC_Typ_LNS 0;
BA_ "GenSigSendType" SG_ 768 ACC_Typ_RNS 0;
BA_ "GenSigSendType" SG_ 768 ACC_Typ_Tachokranz 0;
BA_ "GenSigSendType" SG_ 768 ACC_Typ_Tachokranz_unten 0;
BA_ "GenSigSendType" SG_ 768 ACC_Typ_WZO 0;
BA_ "GenSigSendType" SG_ 768 ACC_Vorz_Abstandswarner 0;
BA_ "GenSigSendType" SG_ 768 ACC_Warnhinweis 0;
BA_ "GenSigSendType" SG_ 768 ACC_Warnung_Verkehrszeichen_1 0;
BA_ "GenSigSendType" SG_ 768 ACC_Wunschgeschw_02 0;
BA_ "GenSigStartValue" SG_ 768 ACC_Wunschgeschw_02 1023;
BA_ "GenSigSendType" SG_ 768 ACC_Wunschgeschw_erreicht 0;
BA_ "GenSigSendType" SG_ 768 ACC_Wunschgeschw_Farbe 0;
BA_ "GenSigSendType" SG_ 768 ACC_Wunschgeschw_Farbe_02 0;
BA_ "GenSigSendType" SG_ 768 ACC_Zeitluecke_Abstandswarner 0;
BA_ "GenSigStartValue" SG_ 768 ACC_Zeitluecke_Abstandswarner 63;
BA_ "GenSigSendType" SG_ 768 FAS_Licht_Anf 0;
BA_ "GenSigSendType" SG_ 768 STA_Primaeranz 0;
BA_ "GenSigSendType" SG_ 768 STA_Texte 0;
BA_ "GenSigSendType" SG_ 768 STA_Zusatzanz 0;
BA_ "GenSigSendType" SG_ 859 ACC_Obj_01_Alter 0;
BA_ "GenSigStartValue" SG_ 859 ACC_Obj_01_Alter 4095;
BA_ "GenSigSendType" SG_ 859 ACC_Obj_01_Anzeige_Rel 0;
BA_ "GenSigSendType" SG_ 859 ACC_Obj_01_ax_StdA 0;
BA_ "GenSigStartValue" SG_ 859 ACC_Obj_01_ax_StdA 63;
BA_ "GenSigSendType" SG_ 859 ACC_Obj_01_ax_v 0;
BA_ "GenSigStartValue" SG_ 859 ACC_Obj_01_ax_v 255;
BA_ "GenSigSendType" SG_ 859 ACC_Obj_01_axAbs_StdA 0;
BA_ "GenSigStartValue" SG_ 859 ACC_Obj_01_axAbs_StdA 63;
BA_ "GenSigSendType" SG_ 859 ACC_Obj_01_axAbs_v 0;
BA_ "GenSigStartValue" SG_ 859 ACC_Obj_01_axAbs_v 255;
BA_ "GenSigSendType" SG_ 859 ACC_Obj_01_ay_StdA 0;
BA_ "GenSigStartValue" SG_ 859 ACC_Obj_01_ay_StdA 63;
BA_ "GenSigSendType" SG_ 859 ACC_Obj_01_ay_v 0;
BA_ "GenSigStartValue" SG_ 859 ACC_Obj_01_ay_v 255;
BA_ "GenSigSendType" SG_ 859 ACC_Obj_01_Bew_Zustand 0;
BA_ "GenSigSendType" SG_ 859 ACC_Obj_01_Bezugspunkt 0;
BA_ "GenSigStartValue" SG_ 859 ACC_Obj_01_Bezugspunkt 15;
BA_ "GenSigSendType" SG_ 859 ACC_Obj_01_Breite 0;
BA_ "GenSigStartValue" SG_ 859 ACC_Obj_01_Breite 127;
BA_ "GenSigSendType" SG_ 859 ACC_Obj_01_BreiteStdA 0;
BA_ "GenSigStartValue" SG_ 859 ACC_Obj_01_BreiteStdA 127;
BA_ "GenSigSendType" SG_ 859 ACC_Obj_01_dx_StdA 0;
BA_ "GenSigSendType" SG_ 859 ACC_Obj_01_dx_v 0;
BA_ "GenSigStartValue" SG_ 859 ACC_Obj_01_dx_v 4095;
BA_ "GenSigSendType" SG_ 859 ACC_Obj_01_dy_StdA 0;
BA_ "GenSigStartValue" SG_ 859 ACC_Obj_01_dy_StdA 127;
BA_ "GenSigSendType" SG_ 859 ACC_Obj_01_dy_v 0;
BA_ "GenSigStartValue" SG_ 859 ACC_Obj_01_dy_v 2047;
BA_ "GenSigSendType" SG_ 859 ACC_Obj_01_dz_StdA 0;
BA_ "GenSigStartValue" SG_ 859 ACC_Obj_01_dz_StdA 127;
BA_ "GenSigSendType" SG_ 859 ACC_Obj_01_dz_v 0;
BA_ "GenSigStartValue" SG_ 859 ACC_Obj_01_dz_v 511;
BA_ "GenSigSendType" SG_ 859 ACC_Obj_01_ExistenzMass 0;
BA_ "GenSigStartValue" SG_ 859 ACC_Obj_01_ExistenzMass 127;
BA_ "GenSigSendType" SG_ 859 ACC_Obj_01_Fusion_ID_FER_VL 0;
BA_ "GenSigStartValue" SG_ 859 ACC_Obj_01_Fusion_ID_FER_VL 255;
BA_ "GenSigSendType" SG_ 859 ACC_Obj_01_Fusion_ID_FER_VR 0;
BA_ "GenSigStartValue" SG_ 859 ACC_Obj_01_Fusion_ID_FER_VR 255;
BA_ "GenSigSendType" SG_ 859 ACC_Obj_01_Fusion_ID_VD 0;
BA_ "GenSigSendType" SG_ 859 ACC_Obj_01_Gemessen 0;
BA_ "GenSigSendType" SG_ 859 ACC_Obj_01_GierWnkl 0;
BA_ "GenSigStartValue" SG_ 859 ACC_Obj_01_GierWnkl 511;
BA_ "GenSigSendType" SG_ 859 ACC_Obj_01_GierWnklStdA 0;
BA_ "GenSigStartValue" SG_ 859 ACC_Obj_01_GierWnklStdA 63;
BA_ "GenSigSendType" SG_ 859 ACC_Obj_01_Historie 0;
BA_ "GenSigSendType" SG_ 859 ACC_Obj_01_Hoehe 0;
BA_ "GenSigStartValue" SG_ 859 ACC_Obj_01_Hoehe 63;
BA_ "GenSigSendType" SG_ 859 ACC_Obj_01_HoeheStdA 0;
BA_ "GenSigStartValue" SG_ 859 ACC_Obj_01_HoeheStdA 63;
BA_ "GenSigSendType" SG_ 859 ACC_Obj_01_ID 0;
BA_ "GenSigStartValue" SG_ 859 ACC_Obj_01_ID 255;
BA_ "GenSigSendType" SG_ 859 ACC_Obj_01_Klasse 0;
BA_ "GenSigStartValue" SG_ 859 ACC_Obj_01_Klasse 15;
BA_ "GenSigSendType" SG_ 859 ACC_Obj_01_KlassePlausib 0;
BA_ "GenSigStartValue" SG_ 859 ACC_Obj_01_KlassePlausib 15;
BA_ "GenSigSendType" SG_ 859 ACC_Obj_01_Laenge 0;
BA_ "GenSigStartValue" SG_ 859 ACC_Obj_01_Laenge 511;
BA_ "GenSigSendType" SG_ 859 ACC_Obj_01_LaengeStdA 0;
BA_ "GenSigStartValue" SG_ 859 ACC_Obj_01_LaengeStdA 127;
BA_ "GenSigSendType" SG_ 859 ACC_Obj_01_LaengsRegelung 0;
BA_ "GenSigSendType" SG_ 859 ACC_Obj_01_SDFInfo_FER_VL 0;
BA_ "GenSigSendType" SG_ 859 ACC_Obj_01_SDFInfo_FER_VR 0;
BA_ "GenSigSendType" SG_ 859 ACC_Obj_01_SDFInfo_FR 0;
BA_ "GenSigSendType" SG_ 859 ACC_Obj_01_SDFInfo_Kamera 0;
BA_ "GenSigSendType" SG_ 859 ACC_Obj_01_vx_StdA 0;
BA_ "GenSigStartValue" SG_ 859 ACC_Obj_01_vx_StdA 31;
BA_ "GenSigSendType" SG_ 859 ACC_Obj_01_vx_v 0;
BA_ "GenSigStartValue" SG_ 859 ACC_Obj_01_vx_v 1023;
BA_ "GenSigSendType" SG_ 859 ACC_Obj_01_vxAbs_StdA 0;
BA_ "GenSigStartValue" SG_ 859 ACC_Obj_01_vxAbs_StdA 63;
BA_ "GenSigSendType" SG_ 859 ACC_Obj_01_vxAbs_v 0;
BA_ "GenSigStartValue" SG_ 859 ACC_Obj_01_vxAbs_v 4095;
BA_ "GenSigSendType" SG_ 859 ACC_Obj_01_vy_StdA 0;
BA_ "GenSigStartValue" SG_ 859 ACC_Obj_01_vy_StdA 31;
BA_ "GenSigSendType" SG_ 859 ACC_Obj_01_vy_v 0;
BA_ "GenSigStartValue" SG_ 859 ACC_Obj_01_vy_v 255;
BA_ "GenSigSendType" SG_ 859 ACC_Obj_01_vyAbs_StdA 0;
BA_ "GenSigStartValue" SG_ 859 ACC_Obj_01_vyAbs_StdA 63;
BA_ "GenSigSendType" SG_ 859 ACC_Obj_01_vyAbs_v 0;
BA_ "GenSigStartValue" SG_ 859 ACC_Obj_01_vyAbs_v 4095;
BA_ "GenSigSendType" SG_ 2331595990 ACC_Obj_02_Alter 0;
BA_ "GenSigStartValue" SG_ 2331595990 ACC_Obj_02_Alter 4095;
BA_ "GenSigSendType" SG_ 2331595990 ACC_Obj_02_Anzeige_Rel 0;
BA_ "GenSigSendType" SG_ 2331595990 ACC_Obj_02_ax_StdA 0;
BA_ "GenSigStartValue" SG_ 2331595990 ACC_Obj_02_ax_StdA 63;
BA_ "GenSigSendType" SG_ 2331595990 ACC_Obj_02_ax_v 0;
BA_ "GenSigStartValue" SG_ 2331595990 ACC_Obj_02_ax_v 255;
BA_ "GenSigSendType" SG_ 2331595990 ACC_Obj_02_ay_StdA 0;
BA_ "GenSigStartValue" SG_ 2331595990 ACC_Obj_02_ay_StdA 63;
BA_ "GenSigSendType" SG_ 2331595990 ACC_Obj_02_ay_v 0;
BA_ "GenSigStartValue" SG_ 2331595990 ACC_Obj_02_ay_v 255;
BA_ "GenSigSendType" SG_ 2331595990 ACC_Obj_02_Bezugspunkt 0;
BA_ "GenSigStartValue" SG_ 2331595990 ACC_Obj_02_Bezugspunkt 15;
BA_ "GenSigSendType" SG_ 2331595990 ACC_Obj_02_Breite 0;
BA_ "GenSigStartValue" SG_ 2331595990 ACC_Obj_02_Breite 127;
BA_ "GenSigSendType" SG_ 2331595990 ACC_Obj_02_BreiteStdA 0;
BA_ "GenSigStartValue" SG_ 2331595990 ACC_Obj_02_BreiteStdA 127;
BA_ "GenSigSendType" SG_ 2331595990 ACC_Obj_02_dx_v 0;
BA_ "GenSigStartValue" SG_ 2331595990 ACC_Obj_02_dx_v 4095;
BA_ "GenSigSendType" SG_ 2331595990 ACC_Obj_02_dy_v 0;
BA_ "GenSigStartValue" SG_ 2331595990 ACC_Obj_02_dy_v 2047;
BA_ "GenSigSendType" SG_ 2331595990 ACC_Obj_02_dz_v 0;
BA_ "GenSigStartValue" SG_ 2331595990 ACC_Obj_02_dz_v 511;
BA_ "GenSigSendType" SG_ 2331595990 ACC_Obj_02_ExistenzMass 0;
BA_ "GenSigStartValue" SG_ 2331595990 ACC_Obj_02_ExistenzMass 127;
BA_ "GenSigSendType" SG_ 2331595990 ACC_Obj_02_Fusion_ID_FER_VL 0;
BA_ "GenSigStartValue" SG_ 2331595990 ACC_Obj_02_Fusion_ID_FER_VL 255;
BA_ "GenSigSendType" SG_ 2331595990 ACC_Obj_02_Fusion_ID_FER_VR 0;
BA_ "GenSigStartValue" SG_ 2331595990 ACC_Obj_02_Fusion_ID_FER_VR 255;
BA_ "GenSigSendType" SG_ 2331595990 ACC_Obj_02_Fusion_ID_VD 0;
BA_ "GenSigSendType" SG_ 2331595990 ACC_Obj_02_Gemessen 0;
BA_ "GenSigSendType" SG_ 2331595990 ACC_Obj_02_GierWnkl 0;
BA_ "GenSigStartValue" SG_ 2331595990 ACC_Obj_02_GierWnkl 511;
BA_ "GenSigSendType" SG_ 2331595990 ACC_Obj_02_GierWnklStdA 0;
BA_ "GenSigStartValue" SG_ 2331595990 ACC_Obj_02_GierWnklStdA 63;
BA_ "GenSigSendType" SG_ 2331595990 ACC_Obj_02_Historie 0;
BA_ "GenSigSendType" SG_ 2331595990 ACC_Obj_02_Hoehe 0;
BA_ "GenSigStartValue" SG_ 2331595990 ACC_Obj_02_Hoehe 63;
BA_ "GenSigSendType" SG_ 2331595990 ACC_Obj_02_HoeheStdA 0;
BA_ "GenSigStartValue" SG_ 2331595990 ACC_Obj_02_HoeheStdA 63;
BA_ "GenSigSendType" SG_ 2331595990 ACC_Obj_02_ID 0;
BA_ "GenSigStartValue" SG_ 2331595990 ACC_Obj_02_ID 255;
BA_ "GenSigSendType" SG_ 2331595990 ACC_Obj_02_Laenge 0;
BA_ "GenSigStartValue" SG_ 2331595990 ACC_Obj_02_Laenge 511;
BA_ "GenSigSendType" SG_ 2331595990 ACC_Obj_02_LaengeStdA 0;
BA_ "GenSigStartValue" SG_ 2331595990 ACC_Obj_02_LaengeStdA 127;
BA_ "GenSigSendType" SG_ 2331595990 ACC_Obj_02_LaengsRegelung 0;
BA_ "GenSigSendType" SG_ 2331595990 ACC_Obj_02_SDFInfo_FER_VL 0;
BA_ "GenSigSendType" SG_ 2331595990 ACC_Obj_02_SDFInfo_FER_VR 0;
BA_ "GenSigSendType" SG_ 2331595990 ACC_Obj_02_SDFInfo_FR 0;
BA_ "GenSigSendType" SG_ 2331595990 ACC_Obj_02_vx_v 0;
BA_ "GenSigStartValue" SG_ 2331595990 ACC_Obj_02_vx_v 1023;
BA_ "GenSigSendType" SG_ 2331595990 ACC_Obj_02_vxAbs_StdA 0;
BA_ "GenSigStartValue" SG_ 2331595990 ACC_Obj_02_vxAbs_StdA 63;
BA_ "GenSigSendType" SG_ 2331595990 ACC_Obj_02_vxAbs_v 0;
BA_ "GenSigStartValue" SG_ 2331595990 ACC_Obj_02_vxAbs_v 4095;
BA_ "GenSigSendType" SG_ 2331595990 ACC_Obj_02_vy_v 0;
BA_ "GenSigStartValue" SG_ 2331595990 ACC_Obj_02_vy_v 255;
BA_ "GenSigSendType" SG_ 2331595990 ACC_Obj_02_vyAbs_StdA 0;
BA_ "GenSigStartValue" SG_ 2331595990 ACC_Obj_02_vyAbs_StdA 63;
BA_ "GenSigSendType" SG_ 2331595990 ACC_Obj_02_vyAbs_v 0;
BA_ "GenSigStartValue" SG_ 2331595990 ACC_Obj_02_vyAbs_v 4095;
BA_ "GenSigSendType" SG_ 2331596021 ACC_Obj_05_Alter 0;
BA_ "GenSigSendType" SG_ 2331596021 ACC_Obj_05_Anzeige_Rel 0;
BA_ "GenSigSendType" SG_ 2331596021 ACC_Obj_05_ax_StdA 0;
BA_ "GenSigSendType" SG_ 2331596021 ACC_Obj_05_ax_v 0;
BA_ "GenSigSendType" SG_ 2331596021 ACC_Obj_05_axAbs_StdA 0;
BA_ "GenSigSendType" SG_ 2331596021 ACC_Obj_05_axAbs_v 0;
BA_ "GenSigSendType" SG_ 2331596021 ACC_Obj_05_ay_StdA 0;
BA_ "GenSigSendType" SG_ 2331596021 ACC_Obj_05_ay_v 0;
BA_ "GenSigSendType" SG_ 2331596021 ACC_Obj_05_Bew_Zustand 0;
BA_ "GenSigSendType" SG_ 2331596021 ACC_Obj_05_Breite 0;
BA_ "GenSigSendType" SG_ 2331596021 ACC_Obj_05_BreiteStdA 0;
BA_ "GenSigSendType" SG_ 2331596021 ACC_Obj_05_dx_StdA 0;
BA_ "GenSigSendType" SG_ 2331596021 ACC_Obj_05_dx_v 0;
BA_ "GenSigStartValue" SG_ 2331596021 ACC_Obj_05_dx_v 4095;
BA_ "GenSigSendType" SG_ 2331596021 ACC_Obj_05_dy_StdA 0;
BA_ "GenSigSendType" SG_ 2331596021 ACC_Obj_05_dy_v 0;
BA_ "GenSigStartValue" SG_ 2331596021 ACC_Obj_05_dy_v 2047;
BA_ "GenSigSendType" SG_ 2331596021 ACC_Obj_05_dz_StdA 0;
BA_ "GenSigSendType" SG_ 2331596021 ACC_Obj_05_dz_v 0;
BA_ "GenSigSendType" SG_ 2331596021 ACC_Obj_05_ExistenzMass 0;
BA_ "GenSigSendType" SG_ 2331596021 ACC_Obj_05_Fusion_ID_FER_VL 0;
BA_ "GenSigSendType" SG_ 2331596021 ACC_Obj_05_Fusion_ID_FER_VR 0;
BA_ "GenSigSendType" SG_ 2331596021 ACC_Obj_05_Fusion_ID_VD 0;
BA_ "GenSigSendType" SG_ 2331596021 ACC_Obj_05_Gemessen 0;
BA_ "GenSigSendType" SG_ 2331596021 ACC_Obj_05_GierWnkl 0;
BA_ "GenSigSendType" SG_ 2331596021 ACC_Obj_05_GierWnklStdA 0;
BA_ "GenSigSendType" SG_ 2331596021 ACC_Obj_05_Historie 0;
BA_ "GenSigSendType" SG_ 2331596021 ACC_Obj_05_Hoehe 0;
BA_ "GenSigSendType" SG_ 2331596021 ACC_Obj_05_HoeheStdA 0;
BA_ "GenSigSendType" SG_ 2331596021 ACC_Obj_05_ID 0;
BA_ "GenSigStartValue" SG_ 2331596021 ACC_Obj_05_ID 255;
BA_ "GenSigSendType" SG_ 2331596021 ACC_Obj_05_Klasse 0;
BA_ "GenSigStartValue" SG_ 2331596021 ACC_Obj_05_Klasse 15;
BA_ "GenSigSendType" SG_ 2331596021 ACC_Obj_05_KlassePlausib 0;
BA_ "GenSigStartValue" SG_ 2331596021 ACC_Obj_05_KlassePlausib 15;
BA_ "GenSigSendType" SG_ 2331596021 ACC_Obj_05_Laenge 0;
BA_ "GenSigSendType" SG_ 2331596021 ACC_Obj_05_LaengeStdA 0;
BA_ "GenSigSendType" SG_ 2331596021 ACC_Obj_05_LaengsRegelung 0;
BA_ "GenSigSendType" SG_ 2331596021 ACC_Obj_05_SDFInfo_FER_VL 0;
BA_ "GenSigSendType" SG_ 2331596021 ACC_Obj_05_SDFInfo_FER_VR 0;
BA_ "GenSigSendType" SG_ 2331596021 ACC_Obj_05_SDFInfo_FR 0;
BA_ "GenSigSendType" SG_ 2331596021 ACC_Obj_05_SDFInfo_Kamera 0;
BA_ "GenSigSendType" SG_ 2331596021 ACC_Obj_05_vx_StdA 0;
BA_ "GenSigStartValue" SG_ 2331596021 ACC_Obj_05_vx_StdA 31;
BA_ "GenSigSendType" SG_ 2331596021 ACC_Obj_05_vx_v 0;
BA_ "GenSigStartValue" SG_ 2331596021 ACC_Obj_05_vx_v 1023;
BA_ "GenSigSendType" SG_ 2331596021 ACC_Obj_05_vxAbs_StdA 0;
BA_ "GenSigSendType" SG_ 2331596021 ACC_Obj_05_vxAbs_v 0;
BA_ "GenSigSendType" SG_ 2331596021 ACC_Obj_05_vy_StdA 0;
BA_ "GenSigStartValue" SG_ 2331596021 ACC_Obj_05_vy_StdA 31;
BA_ "GenSigSendType" SG_ 2331596021 ACC_Obj_05_vy_v 0;
BA_ "GenSigStartValue" SG_ 2331596021 ACC_Obj_05_vy_v 255;
BA_ "GenSigSendType" SG_ 2331596021 ACC_Obj_05_vyAbs_StdA 0;
BA_ "GenSigSendType" SG_ 2331596021 ACC_Obj_05_vyAbs_v 0;
BA_ "GenSigSendType" SG_ 2527679923 ADA_AttentionLevel 3;
BA_ "GenSigStartValue" SG_ 2527679923 ADA_AttentionLevel 126;
BA_ "Fehlerwert" SG_ 2527679923 ADA_AttentionLevel 127;
BA_ "GenSigSendType" SG_ 2527679923 ADA_DistractionLevel 4;
BA_ "GenSigStartValue" SG_ 2527679923 ADA_DistractionLevel 126;
BA_ "Fehlerwert" SG_ 2527679923 ADA_DistractionLevel 127;
BA_ "GenSigSendType" SG_ 2527679923 ADA_DriverIsOperating 3;
BA_ "Fehlerwert" SG_ 2527679923 ADA_DriverIsOperating 3;
BA_ "GenSigSendType" SG_ 2527679923 ADA_DrowsinessLevel 4;
BA_ "GenSigStartValue" SG_ 2527679923 ADA_DrowsinessLevel 126;
BA_ "Fehlerwert" SG_ 2527679923 ADA_DrowsinessLevel 127;
BA_ "GenSigSendType" SG_ 2527679923 ADA_DrowsinessSystemState 4;
BA_ "GenSigSwitchedByIgnition" SG_ 2527679923 ADA_DrowsinessSystemState 0;
BA_ "GenSigSendType" SG_ 2527679923 ADA_HMI_Ablenkung_Deaktivierung 3;
BA_ "GenSigSendType" SG_ 2527679923 ADA_HMI_Ablenkung_Fehler_Popup 3;
BA_ "GenSigSendType" SG_ 2527679923 ADA_HMI_Ablenkung_Meldeakustik 3;
BA_ "GenSigSendType" SG_ 2527679923 ADA_HMI_Ablenkung_Meldung 3;
BA_ "GenSigSendType" SG_ 2527679923 ADA_HMI_Fahrzeit_seit_Pause 3;
BA_ "GenSigStartValue" SG_ 2527679923 ADA_HMI_Fahrzeit_seit_Pause 1023;
BA_ "GenSigSendType" SG_ 2527679923 ADA_HMI_Muedigkeit_Deaktivierung 3;
BA_ "GenSigSendType" SG_ 2527679923 ADA_HMI_Muedigkeit_Event_Meldung 3;
BA_ "GenSigSendType" SG_ 2527679923 ADA_HMI_Muedigkeit_Fehler_Popup 3;
BA_ "GenSigSendType" SG_ 2527679923 ADA_HMI_Muedigkeit_Meldeakustik 3;
BA_ "GenSigSendType" SG_ 2527679923 ADA_HMI_Muedigkeit_Meldung 3;
BA_ "GenSigSendType" SG_ 2527679923 ADA_Microsleep 3;
BA_ "GenSigStartValue" SG_ 2527679923 ADA_Microsleep 6;
BA_ "GenSigSendType" SG_ 2527679923 ADA_TriggerEmergencyAssist 3;
BA_ "GenSigStartValue" SG_ 2527679923 ADA_TriggerEmergencyAssist 6;
BA_ "Fehlerwert" SG_ 2527679923 ADA_TriggerEmergencyAssist 7;
BA_ "GenSigSendType" SG_ 2527679923 ADA_Upcoming_Microsleep 0;
BA_ "GenSigSendType" SG_ 2527679923 SOK_ADA_01_Signatur 0;
BA_ "GenSigFuncType" SG_ 2527679923 SOK_ADA_01_Signatur 15;
BA_ "GenSigSendType" SG_ 1660 AGA_Charisma_FahrPr 3;
BA_ "GenSigSendType" SG_ 1660 AGA_Charisma_Status 3;
BA_ "GenSigSendType" SG_ 1660 AGA_ohne_Funktion 3;
BA_ "Fehlerwert" SG_ 1660 AGA_ohne_Funktion 1;
BA_ "GenSigSendType" SG_ 1660 AGA_Texte 3;
BA_ "GenSigSendType" SG_ 1660 AGA_Verstaerker_Mute 0;
BA_ "GenSigSwitchedByIgnition" SG_ 1660 AGA_Verstaerker_Mute 0;
BA_ "GenSigSendType" SG_ 1660 E_Sound_verbaut 0;
BA_ "GenSigSendType" SG_ 64 AB_Anzeige_Fussg 0;
BA_ "GenSigSwitchedByIgnition" SG_ 64 AB_Anzeige_Fussg 0;
BA_ "GenSigSendType" SG_ 64 AB_Belegung_VF 0;
BA_ "GenSigSwitchedByIgnition" SG_ 64 AB_Belegung_VF 0;
BA_ "Fehlerwert" SG_ 64 AB_Belegung_VF 1;
BA_ "GenSigSendType" SG_ 64 AB_Crash_Int 4;
BA_ "GenSigSwitchedByIgnition" SG_ 64 AB_Crash_Int 0;
BA_ "GenSigSendType" SG_ 64 AB_Deaktiviert 0;
BA_ "GenSigSwitchedByIgnition" SG_ 64 AB_Deaktiviert 0;
BA_ "GenSigSendType" SG_ 64 AB_Deaktivierung_HV 4;
BA_ "GenSigSwitchedByIgnition" SG_ 64 AB_Deaktivierung_HV 0;
BA_ "Fehlerwert" SG_ 64 AB_Deaktivierung_HV 7;
BA_ "GenSigSendType" SG_ 64 AB_Diagnose 0;
BA_ "GenSigSwitchedByIgnition" SG_ 64 AB_Diagnose 0;
BA_ "GenSigSendType" SG_ 64 AB_eCS_Error 0;
BA_ "GenSigSwitchedByIgnition" SG_ 64 AB_eCS_Error 0;
BA_ "GenSigSendType" SG_ 64 AB_EDR_Trigger 3;
BA_ "GenSigSwitchedByIgnition" SG_ 64 AB_EDR_Trigger 0;
BA_ "GenSigSendType" SG_ 64 AB_Erh_Auf_VB 0;
BA_ "GenSigSwitchedByIgnition" SG_ 64 AB_Erh_Auf_VB 0;
BA_ "GenSigSendType" SG_ 64 AB_Front_Crash 4;
BA_ "GenSigSwitchedByIgnition" SG_ 64 AB_Front_Crash 0;
BA_ "GenSigSendType" SG_ 64 AB_Gurtschloss_FA_ext 3;
BA_ "GenSigStartValue" SG_ 64 AB_Gurtschloss_FA_ext 6;
BA_ "GenSigSwitchedByIgnition" SG_ 64 AB_Gurtschloss_FA_ext 0;
BA_ "Fehlerwert" SG_ 64 AB_Gurtschloss_FA_ext 7;
BA_ "GenSigSendType" SG_ 64 AB_Gurtschloss_FA_ext_aktiv 0;
BA_ "GenSigSwitchedByIgnition" SG_ 64 AB_Gurtschloss_FA_ext_aktiv 0;
BA_ "GenSigSendType" SG_ 64 AB_Gurtwarn_VB 0;
BA_ "GenSigSwitchedByIgnition" SG_ 64 AB_Gurtwarn_VB 0;
BA_ "GenSigSendType" SG_ 64 AB_Gurtwarn_VF 0;
BA_ "GenSigSwitchedByIgnition" SG_ 64 AB_Gurtwarn_VF 0;
BA_ "GenSigSendType" SG_ 64 AB_Heck_Crash 4;
BA_ "GenSigSwitchedByIgnition" SG_ 64 AB_Heck_Crash 0;
BA_ "GenSigSendType" SG_ 64 AB_Lampe 0;
BA_ "GenSigStartValue" SG_ 64 AB_Lampe 1;
BA_ "GenSigSwitchedByIgnition" SG_ 64 AB_Lampe 0;
BA_ "GenSigSendType" SG_ 64 AB_MKB_Anforderung 4;
BA_ "GenSigSwitchedByIgnition" SG_ 64 AB_MKB_Anforderung 0;
BA_ "GenSigSendType" SG_ 64 AB_MKB_gueltig 0;
BA_ "GenSigSwitchedByIgnition" SG_ 64 AB_MKB_gueltig 0;
BA_ "GenSigSendType" SG_ 64 AB_PAO_Leuchte_Anf 0;
BA_ "GenSigStartValue" SG_ 64 AB_PAO_Leuchte_Anf 1;
BA_ "GenSigSwitchedByIgnition" SG_ 64 AB_PAO_Leuchte_Anf 0;
BA_ "GenSigSendType" SG_ 64 AB_RGS_Anst 3;
BA_ "GenSigStartValue" SG_ 64 AB_RGS_Anst 8;
BA_ "GenSigSwitchedByIgnition" SG_ 64 AB_RGS_Anst 0;
BA_ "GenSigSendType" SG_ 64 AB_Rollover_Crash 4;
BA_ "GenSigSwitchedByIgnition" SG_ 64 AB_Rollover_Crash 0;
BA_ "GenSigSendType" SG_ 64 AB_SB_Crash 4;
BA_ "GenSigSwitchedByIgnition" SG_ 64 AB_SB_Crash 0;
BA_ "GenSigSendType" SG_ 64 AB_SF_Crash 4;
BA_ "GenSigSwitchedByIgnition" SG_ 64 AB_SF_Crash 0;
BA_ "GenSigSendType" SG_ 64 AB_Stellgliedtest 0;
BA_ "GenSigSwitchedByIgnition" SG_ 64 AB_Stellgliedtest 0;
BA_ "GenSigSendType" SG_ 64 AB_Systemfehler 0;
BA_ "GenSigSwitchedByIgnition" SG_ 64 AB_Systemfehler 0;
BA_ "GenSigSendType" SG_ 64 AB_Texte_AKS 0;
BA_ "GenSigSwitchedByIgnition" SG_ 64 AB_Texte_AKS 0;
BA_ "GenSigSendType" SG_ 64 AB_VB_deaktiviert 0;
BA_ "GenSigStartValue" SG_ 64 AB_VB_deaktiviert 1;
BA_ "GenSigSwitchedByIgnition" SG_ 64 AB_VB_deaktiviert 0;
BA_ "GenSigSendType" SG_ 64 AB_Versorgungsspannung 0;
BA_ "GenSigSwitchedByIgnition" SG_ 64 AB_Versorgungsspannung 0;
BA_ "GenSigSendType" SG_ 64 Airbag_01_BZ 0;
BA_ "GenSigFuncType" SG_ 64 Airbag_01_BZ 1;
BA_ "GenSigSwitchedByIgnition" SG_ 64 Airbag_01_BZ 0;
BA_ "GenSigSendType" SG_ 64 Airbag_01_CRC 0;
BA_ "GenSigFuncType" SG_ 64 Airbag_01_CRC 2;
BA_ "GenSigSwitchedByIgnition" SG_ 64 Airbag_01_CRC 0;
BA_ "GenSigSendType" SG_ 64 ASM_Masterzeit_02 0;
BA_ "GenSigStartValue" SG_ 64 ASM_Masterzeit_02 255;
BA_ "GenSigSwitchedByIgnition" SG_ 64 ASM_Masterzeit_02 0;
BA_ "GenSigSendType" SG_ 1312 AB_Abschaltanf_SIH_BF 3;
BA_ "GenSigSendType" SG_ 1312 AB_Anforderung_eCall 0;
BA_ "GenSigSwitchedByIgnition" SG_ 1312 AB_Anforderung_eCall 0;
BA_ "GenSigSendType" SG_ 1312 AB_Anforderung_USM 0;
BA_ "GenSigSwitchedByIgnition" SG_ 1312 AB_Anforderung_USM 0;
BA_ "GenSigSendType" SG_ 1312 AB_Anprall_FGS 3;
BA_ "GenSigSendType" SG_ 1312 AB_Anprall_Front_Beifahrer 3;
BA_ "GenSigSendType" SG_ 1312 AB_Anprall_Front_Fahrer 3;
BA_ "GenSigSendType" SG_ 1312 AB_Anprall_Heck_Beifahrer 3;
BA_ "GenSigSendType" SG_ 1312 AB_Anprall_Heck_Fahrer 3;
BA_ "GenSigSendType" SG_ 1312 AB_Anprall_Rollover 3;
BA_ "GenSigSendType" SG_ 1312 AB_Anprall_Seite_Beifahrer 3;
BA_ "GenSigSendType" SG_ 1312 AB_Anprall_Seite_Fahrer 3;
BA_ "GenSigSendType" SG_ 1312 AB_Belegung_VB 0;
BA_ "GenSigSwitchedByIgnition" SG_ 1312 AB_Belegung_VB 0;
BA_ "Fehlerwert" SG_ 1312 AB_Belegung_VB 1;
BA_ "GenSigSendType" SG_ 1312 AB_Crashschwere 3;
BA_ "GenSigSwitchedByIgnition" SG_ 1312 AB_Crashschwere 0;
BA_ "Fehlerwert" SG_ 1312 AB_Crashschwere 7;
BA_ "GenSigSendType" SG_ 1312 AB_Gurtschloss_BF 3;
BA_ "GenSigStartValue" SG_ 1312 AB_Gurtschloss_BF 1;
BA_ "GenSigSwitchedByIgnition" SG_ 1312 AB_Gurtschloss_BF 0;
BA_ "GenSigSendType" SG_ 1312 AB_Gurtschloss_FA 3;
BA_ "GenSigStartValue" SG_ 1312 AB_Gurtschloss_FA 1;
BA_ "GenSigSwitchedByIgnition" SG_ 1312 AB_Gurtschloss_FA 0;
BA_ "GenSigSendType" SG_ 1312 AB_Gurtschloss_Reihe2_BF 3;
BA_ "GenSigStartValue" SG_ 1312 AB_Gurtschloss_Reihe2_BF 1;
BA_ "GenSigSwitchedByIgnition" SG_ 1312 AB_Gurtschloss_Reihe2_BF 0;
BA_ "GenSigSendType" SG_ 1312 AB_Gurtschloss_Reihe2_FA 3;
BA_ "GenSigStartValue" SG_ 1312 AB_Gurtschloss_Reihe2_FA 1;
BA_ "GenSigSwitchedByIgnition" SG_ 1312 AB_Gurtschloss_Reihe2_FA 0;
BA_ "GenSigSendType" SG_ 1312 AB_Gurtschloss_Reihe2_MI 3;
BA_ "GenSigStartValue" SG_ 1312 AB_Gurtschloss_Reihe2_MI 1;
BA_ "GenSigSwitchedByIgnition" SG_ 1312 AB_Gurtschloss_Reihe2_MI 0;
BA_ "GenSigSendType" SG_ 1312 AB_Gurtschloss_Reihe3_BF 3;
BA_ "GenSigStartValue" SG_ 1312 AB_Gurtschloss_Reihe3_BF 1;
BA_ "GenSigSwitchedByIgnition" SG_ 1312 AB_Gurtschloss_Reihe3_BF 0;
BA_ "GenSigSendType" SG_ 1312 AB_Gurtschloss_Reihe3_FA 3;
BA_ "GenSigStartValue" SG_ 1312 AB_Gurtschloss_Reihe3_FA 1;
BA_ "GenSigSwitchedByIgnition" SG_ 1312 AB_Gurtschloss_Reihe3_FA 0;
BA_ "GenSigSendType" SG_ 1312 AB_Gurtschloss_Reihe3_MI 3;
BA_ "GenSigStartValue" SG_ 1312 AB_Gurtschloss_Reihe3_MI 1;
BA_ "GenSigSwitchedByIgnition" SG_ 1312 AB_Gurtschloss_Reihe3_MI 0;
BA_ "GenSigSendType" SG_ 1312 AB_Sitzpos_Sens_BF 0;
BA_ "GenSigSwitchedByIgnition" SG_ 1312 AB_Sitzpos_Sens_BF 0;
BA_ "Fehlerwert" SG_ 1312 AB_Sitzpos_Sens_BF 1;
BA_ "GenSigSendType" SG_ 1312 AB_Sitzpos_Sens_FA 0;
BA_ "GenSigSwitchedByIgnition" SG_ 1312 AB_Sitzpos_Sens_FA 0;
BA_ "Fehlerwert" SG_ 1312 AB_Sitzpos_Sens_FA 1;
BA_ "GenSigSendType" SG_ 1312 AB_Wickelklappung_Reihe2_BF 3;
BA_ "GenSigStartValue" SG_ 1312 AB_Wickelklappung_Reihe2_BF 1;
BA_ "GenSigSwitchedByIgnition" SG_ 1312 AB_Wickelklappung_Reihe2_BF 0;
BA_ "GenSigSendType" SG_ 1312 AB_Wickelklappung_Reihe2_FA 3;
BA_ "GenSigStartValue" SG_ 1312 AB_Wickelklappung_Reihe2_FA 1;
BA_ "GenSigSwitchedByIgnition" SG_ 1312 AB_Wickelklappung_Reihe2_FA 0;
BA_ "GenSigSendType" SG_ 1312 AB_Wickelklappung_Reihe2_MI 3;
BA_ "GenSigStartValue" SG_ 1312 AB_Wickelklappung_Reihe2_MI 1;
BA_ "GenSigSwitchedByIgnition" SG_ 1312 AB_Wickelklappung_Reihe2_MI 0;
BA_ "GenSigSendType" SG_ 1312 Airbag_02_BZ 0;
BA_ "GenSigFuncType" SG_ 1312 Airbag_02_BZ 1;
BA_ "GenSigSwitchedByIgnition" SG_ 1312 Airbag_02_BZ 0;
BA_ "GenSigSendType" SG_ 1312 Airbag_02_CRC 0;
BA_ "GenSigFuncType" SG_ 1312 Airbag_02_CRC 2;
BA_ "GenSigSwitchedByIgnition" SG_ 1312 Airbag_02_CRC 0;
BA_ "GenSigSendType" SG_ 1312 LoGeWa_Event_Kombiwarnung 3;
BA_ "GenSigSwitchedByIgnition" SG_ 1312 LoGeWa_Event_Kombiwarnung 0;
BA_ "GenSigSendType" SG_ 1312 SC_PAO_OFF_Anf 3;
BA_ "GenSigSwitchedByIgnition" SG_ 1312 SC_PAO_OFF_Anf 0;
BA_ "GenSigSendType" SG_ 1312 SC_PAO_ON_Anf 3;
BA_ "GenSigSwitchedByIgnition" SG_ 1312 SC_PAO_ON_Anf 0;
BA_ "GenSigSendType" SG_ 1312 SC_PAO_Schriftzug_Anf 3;
BA_ "GenSigSwitchedByIgnition" SG_ 1312 SC_PAO_Schriftzug_Anf 0;
BA_ "GenSigSendType" SG_ 1349 AB_Anprall_Front 3;
BA_ "GenSigSwitchedByIgnition" SG_ 1349 AB_Anprall_Front 0;
BA_ "GenSigSendType" SG_ 1349 AB_Anprall_Heck 3;
BA_ "GenSigSwitchedByIgnition" SG_ 1349 AB_Anprall_Heck 0;
BA_ "GenSigSendType" SG_ 1349 AB_Belegung_VF_ext 3;
BA_ "GenSigStartValue" SG_ 1349 AB_Belegung_VF_ext 6;
BA_ "GenSigSwitchedByIgnition" SG_ 1349 AB_Belegung_VF_ext 0;
BA_ "Fehlerwert" SG_ 1349 AB_Belegung_VF_ext 7;
BA_ "GenSigSendType" SG_ 1349 AB_Belegung_VF_ext_aktiv 3;
BA_ "GenSigSwitchedByIgnition" SG_ 1349 AB_Belegung_VF_ext_aktiv 0;
BA_ "GenSigSendType" SG_ 1349 AB_Gurtwarn_Reihe2_BF 0;
BA_ "GenSigSwitchedByIgnition" SG_ 1349 AB_Gurtwarn_Reihe2_BF 0;
BA_ "GenSigSendType" SG_ 1349 AB_Gurtwarn_Reihe2_FA 0;
BA_ "GenSigSwitchedByIgnition" SG_ 1349 AB_Gurtwarn_Reihe2_FA 0;
BA_ "GenSigSendType" SG_ 1349 AB_Gurtwarn_Reihe2_MI 0;
BA_ "GenSigSwitchedByIgnition" SG_ 1349 AB_Gurtwarn_Reihe2_MI 0;
BA_ "GenSigSendType" SG_ 1349 AB_Gurtwarn_Reihe3_BF 0;
BA_ "GenSigSwitchedByIgnition" SG_ 1349 AB_Gurtwarn_Reihe3_BF 0;
BA_ "GenSigSendType" SG_ 1349 AB_Gurtwarn_Reihe3_FA 0;
BA_ "GenSigSwitchedByIgnition" SG_ 1349 AB_Gurtwarn_Reihe3_FA 0;
BA_ "GenSigSendType" SG_ 1349 AB_Gurtwarn_Reihe3_MI 0;
BA_ "GenSigSwitchedByIgnition" SG_ 1349 AB_Gurtwarn_Reihe3_MI 0;
BA_ "GenSigSendType" SG_ 1349 AB_Gurtwarn_Reihe4_BF 0;
BA_ "GenSigSwitchedByIgnition" SG_ 1349 AB_Gurtwarn_Reihe4_BF 0;
BA_ "GenSigSendType" SG_ 1349 AB_Gurtwarn_Reihe4_FA 0;
BA_ "GenSigSwitchedByIgnition" SG_ 1349 AB_Gurtwarn_Reihe4_FA 0;
BA_ "GenSigSendType" SG_ 1349 AB_Gurtwarn_Reihe4_MI 0;
BA_ "GenSigSwitchedByIgnition" SG_ 1349 AB_Gurtwarn_Reihe4_MI 0;
BA_ "GenSigSendType" SG_ 1349 AB_SBR_hinten_verbau 0;
BA_ "GenSigStartValue" SG_ 1349 AB_SBR_hinten_verbau 3;
BA_ "GenSigSwitchedByIgnition" SG_ 1349 AB_SBR_hinten_verbau 0;
BA_ "GenSigSendType" SG_ 1349 AbstWarn_MV_FAS_Fkt_Status 3;
BA_ "GenSigSwitchedByIgnition" SG_ 1349 AbstWarn_MV_FAS_Fkt_Status 0;
BA_ "Fehlerwert" SG_ 1349 AbstWarn_MV_FAS_Fkt_Status 3;
BA_ "GenSigSendType" SG_ 1349 Airbag_04_BZ 0;
BA_ "GenSigFuncType" SG_ 1349 Airbag_04_BZ 1;
BA_ "GenSigSwitchedByIgnition" SG_ 1349 Airbag_04_BZ 0;
BA_ "GenSigSendType" SG_ 1349 Airbag_04_CRC 0;
BA_ "GenSigFuncType" SG_ 1349 Airbag_04_CRC 2;
BA_ "GenSigSwitchedByIgnition" SG_ 1349 Airbag_04_CRC 0;
BA_ "GenSigSendType" SG_ 1349 AWV_Einstellung_System_ASG 3;
BA_ "GenSigSwitchedByIgnition" SG_ 1349 AWV_Einstellung_System_ASG 0;
BA_ "GenSigSendType" SG_ 1349 AWV_Einstellung_Warnung_ASG 3;
BA_ "GenSigSwitchedByIgnition" SG_ 1349 AWV_Einstellung_Warnung_ASG 0;
BA_ "GenSigSendType" SG_ 1349 LGI_FAS_Fkt_Status 3;
BA_ "GenSigSwitchedByIgnition" SG_ 1349 LGI_FAS_Fkt_Status 0;
BA_ "Fehlerwert" SG_ 1349 LGI_FAS_Fkt_Status 3;
BA_ "GenSigSendType" SG_ 1349 PreCrash_FAS_Fkt_Status 3;
BA_ "GenSigSwitchedByIgnition" SG_ 1349 PreCrash_FAS_Fkt_Status 0;
BA_ "Fehlerwert" SG_ 1349 PreCrash_FAS_Fkt_Status 3;
BA_ "GenSigSendType" SG_ 1349 SC_PreSense_Modus_System_KAS 3;
BA_ "GenSigSwitchedByIgnition" SG_ 1349 SC_PreSense_Modus_System_KAS 0;
BA_ "GenSigSendType" SG_ 1349 SC_PreSense_Modus_System_MV 3;
BA_ "GenSigSwitchedByIgnition" SG_ 1349 SC_PreSense_Modus_System_MV 0;
BA_ "GenSigSendType" SG_ 1349 SC_PreSense_Modus_System_NV 3;
BA_ "GenSigSwitchedByIgnition" SG_ 1349 SC_PreSense_Modus_System_NV 0;
BA_ "GenSigSendType" SG_ 1349 SC_PreSense_Modus_Warnung_MV 3;
BA_ "GenSigSwitchedByIgnition" SG_ 1349 SC_PreSense_Modus_Warnung_MV 0;
BA_ "GenSigSendType" SG_ 1349 SC_PreSense_Modus_Warnung_NV 3;
BA_ "GenSigSwitchedByIgnition" SG_ 1349 SC_PreSense_Modus_Warnung_NV 0;
BA_ "GenSigSendType" SG_ 1349 WarnBrems_Charisma_FahrPr 0;
BA_ "GenSigSendType" SG_ 1349 WarnBrems_Charisma_Status 0;
BA_ "GenSigSendType" SG_ 2527679722 AB_Anzeige_Kombi_SRAB 0;
BA_ "GenSigSendType" SG_ 2527679722 AB_Anzeige_Komfort_HBFS 0;
BA_ "GenSigSendType" SG_ 2527679722 AB_Anzeige_Komfort_HFS 0;
BA_ "GenSigSendType" SG_ 2527679722 AB_Anzeige_Sitz_Komfort_HBFS 0;
BA_ "GenSigSendType" SG_ 2527679722 AB_Anzeige_Sitz_Komfort_HFS 0;
BA_ "GenSigSendType" SG_ 2527679722 AB_Gurtschloss_MI 0;
BA_ "GenSigStartValue" SG_ 2527679722 AB_Gurtschloss_MI 1;
BA_ "GenSigSwitchedByIgnition" SG_ 2527679722 AB_Gurtschloss_MI 0;
BA_ "GenSigSendType" SG_ 2527679722 AB_Gurtschloss_Reihe4_BF 0;
BA_ "GenSigStartValue" SG_ 2527679722 AB_Gurtschloss_Reihe4_BF 1;
BA_ "GenSigSwitchedByIgnition" SG_ 2527679722 AB_Gurtschloss_Reihe4_BF 0;
BA_ "GenSigSendType" SG_ 2527679722 AB_Gurtschloss_Reihe4_FA 0;
BA_ "GenSigStartValue" SG_ 2527679722 AB_Gurtschloss_Reihe4_FA 1;
BA_ "GenSigSwitchedByIgnition" SG_ 2527679722 AB_Gurtschloss_Reihe4_FA 0;
BA_ "GenSigSendType" SG_ 2527679722 AB_Gurtschloss_Reihe4_MI 0;
BA_ "GenSigStartValue" SG_ 2527679722 AB_Gurtschloss_Reihe4_MI 1;
BA_ "GenSigSwitchedByIgnition" SG_ 2527679722 AB_Gurtschloss_Reihe4_MI 0;
BA_ "GenSigSendType" SG_ 2527679722 AB_Gurtwarn_VM 0;
BA_ "GenSigSwitchedByIgnition" SG_ 2527679722 AB_Gurtwarn_VM 0;
BA_ "GenSigSendType" SG_ 2527679722 AB_Status_Sitz_SRAB_HBFS 0;
BA_ "GenSigStartValue" SG_ 2527679722 AB_Status_Sitz_SRAB_HBFS 2;
BA_ "GenSigSwitchedByIgnition" SG_ 2527679722 AB_Status_Sitz_SRAB_HBFS 0;
BA_ "Fehlerwert" SG_ 2527679722 AB_Status_Sitz_SRAB_HBFS 3;
BA_ "GenSigSendType" SG_ 2527679722 AB_Status_Sitz_SRAB_HFS 0;
BA_ "GenSigStartValue" SG_ 2527679722 AB_Status_Sitz_SRAB_HFS 2;
BA_ "Fehlerwert" SG_ 2527679722 AB_Status_Sitz_SRAB_HFS 3;
BA_ "GenSigSendType" SG_ 2527679722 AB_wSBR_Batteriestatus 0;
BA_ "GenSigSwitchedByIgnition" SG_ 2527679722 AB_wSBR_Batteriestatus 0;
BA_ "GenSigSendType" SG_ 2527679722 Airbag_06_BZ 0;
BA_ "GenSigFuncType" SG_ 2527679722 Airbag_06_BZ 1;
BA_ "GenSigSwitchedByIgnition" SG_ 2527679722 Airbag_06_BZ 0;
BA_ "GenSigSendType" SG_ 2527679722 Airbag_06_CRC 0;
BA_ "GenSigFuncType" SG_ 2527679722 Airbag_06_CRC 2;
BA_ "GenSigSwitchedByIgnition" SG_ 2527679722 Airbag_06_CRC 0;
BA_ "GenSigSendType" SG_ 280 Allrad_03_BZ 0;
BA_ "GenSigFuncType" SG_ 280 Allrad_03_BZ 1;
BA_ "GenSigSendType" SG_ 280 ALR_Charisma_FahrPr 0;
BA_ "GenSigSwitchedByIgnition" SG_ 280 ALR_Charisma_FahrPr 0;
BA_ "GenSigSendType" SG_ 280 ALR_Charisma_Status 0;
BA_ "GenSigSwitchedByIgnition" SG_ 280 ALR_Charisma_Status 0;
BA_ "GenSigSendType" SG_ 280 ALR_Ist_Proz 0;
BA_ "GenSigStartValue" SG_ 280 ALR_Ist_Proz 254;
BA_ "Fehlerwert" SG_ 280 ALR_Ist_Proz 255;
BA_ "GenSigSendType" SG_ 280 ALR_Sendestatus 6;
BA_ "GenSigSendType" SG_ 280 ALR_Sta_Laengssperre 0;
BA_ "GenSigSendType" SG_ 280 ALR_Warnlampe 0;
BA_ "GenSigSendType" SG_ 308 ALR_gMeter_ax 0;
BA_ "GenSigStartValue" SG_ 308 ALR_gMeter_ax 1022;
BA_ "Fehlerwert" SG_ 308 ALR_gMeter_ax 1023;
BA_ "GenSigSendType" SG_ 308 ALR_gMeter_ay 0;
BA_ "GenSigStartValue" SG_ 308 ALR_gMeter_ay 1022;
BA_ "Fehlerwert" SG_ 308 ALR_gMeter_ay 1023;
BA_ "GenSigSendType" SG_ 1633 AAG_Anhaenger_abgesteckt 0;
BA_ "GenSigSwitchedByIgnition" SG_ 1633 AAG_Anhaenger_abgesteckt 0;
BA_ "GenSigSendType" SG_ 1633 AAG_Anhaenger_erkannt 0;
BA_ "NWM-WakeupAllowed" SG_ 1633 AAG_Anhaenger_erkannt 1;
BA_ "GenSigSwitchedByIgnition" SG_ 1633 AAG_Anhaenger_erkannt 0;
BA_ "GenSigSendType" SG_ 1633 AAG_AVS_Fehler_02 0;
BA_ "GenSigSwitchedByIgnition" SG_ 1633 AAG_AVS_Fehler_02 0;
BA_ "Fehlerwert" SG_ 1633 AAG_AVS_Fehler_02 1;
BA_ "GenSigSendType" SG_ 1633 AAG_AVS_Fehler_02_inv 0;
BA_ "GenSigStartValue" SG_ 1633 AAG_AVS_Fehler_02_inv 1;
BA_ "GenSigSwitchedByIgnition" SG_ 1633 AAG_AVS_Fehler_02_inv 0;
BA_ "GenSigSendType" SG_ 1633 AAG_AVS_Stati 0;
BA_ "GenSigSwitchedByIgnition" SG_ 1633 AAG_AVS_Stati 0;
BA_ "GenSigSendType" SG_ 1633 AAG_Blinker_H_aktiv 0;
BA_ "GenSigSwitchedByIgnition" SG_ 1633 AAG_Blinker_H_aktiv 0;
BA_ "GenSigSendType" SG_ 1633 AAG_Blinker_HL_def 0;
BA_ "GenSigSwitchedByIgnition" SG_ 1633 AAG_Blinker_HL_def 0;
BA_ "GenSigSendType" SG_ 1633 AAG_Blinker_HR_def 0;
BA_ "GenSigSwitchedByIgnition" SG_ 1633 AAG_Blinker_HR_def 0;
BA_ "GenSigSendType" SG_ 1633 AAG_Bremsl_durch_ECD 0;
BA_ "GenSigSwitchedByIgnition" SG_ 1633 AAG_Bremsl_durch_ECD 0;
BA_ "GenSigSendType" SG_ 1633 AAG_Bremslicht_H_def 0;
BA_ "GenSigSwitchedByIgnition" SG_ 1633 AAG_Bremslicht_H_def 0;
BA_ "GenSigSendType" SG_ 1633 AAG_Bremslicht_Reku 0;
BA_ "GenSigSwitchedByIgnition" SG_ 1633 AAG_Bremslicht_Reku 0;
BA_ "GenSigSendType" SG_ 1633 AAG_BZ 0;
BA_ "GenSigFuncType" SG_ 1633 AAG_BZ 1;
BA_ "GenSigSwitchedByIgnition" SG_ 1633 AAG_BZ 0;
BA_ "GenSigSendType" SG_ 1633 AAG_LED_aktiv 0;
BA_ "GenSigSwitchedByIgnition" SG_ 1633 AAG_LED_aktiv 0;
BA_ "GenSigSendType" SG_ 1633 AAG_NSL_aktiv 0;
BA_ "GenSigSwitchedByIgnition" SG_ 1633 AAG_NSL_aktiv 0;
BA_ "GenSigSendType" SG_ 1633 AAG_Schlusslicht_HL_def 0;
BA_ "GenSigSwitchedByIgnition" SG_ 1633 AAG_Schlusslicht_HL_def 0;
BA_ "GenSigSendType" SG_ 1633 AAG_Schlusslicht_HR_def 0;
BA_ "GenSigSwitchedByIgnition" SG_ 1633 AAG_Schlusslicht_HR_def 0;
BA_ "GenSigSendType" SG_ 345 ARA_Aktiver_Grafikmodus 0;
BA_ "GenSigSendType" SG_ 345 ARA_Bremsfuss 0;
BA_ "GenSigSendType" SG_ 345 ARA_Deaktivierung_sperren 3;
BA_ "GenSigSendType" SG_ 345 ARA_Knickwinkel_Ist 3;
BA_ "GenSigStartValue" SG_ 345 ARA_Knickwinkel_Ist 254;
BA_ "Fehlerwert" SG_ 345 ARA_Knickwinkel_Ist 255;
BA_ "GenSigSendType" SG_ 345 ARA_Knickwinkel_Komfort 3;
BA_ "GenSigStartValue" SG_ 345 ARA_Knickwinkel_Komfort 62;
BA_ "GenSigSwitchedByIgnition" SG_ 345 ARA_Knickwinkel_Komfort 0;
BA_ "Fehlerwert" SG_ 345 ARA_Knickwinkel_Komfort 63;
BA_ "GenSigSendType" SG_ 345 ARA_Knickwinkel_Konfidenz 0;
BA_ "GenSigStartValue" SG_ 345 ARA_Knickwinkel_Konfidenz 126;
BA_ "GenSigSwitchedByIgnition" SG_ 345 ARA_Knickwinkel_Konfidenz 0;
BA_ "Fehlerwert" SG_ 345 ARA_Knickwinkel_Konfidenz 127;
BA_ "GenSigSendType" SG_ 345 ARA_Knickwinkel_Max 3;
BA_ "GenSigStartValue" SG_ 345 ARA_Knickwinkel_Max 126;
BA_ "Fehlerwert" SG_ 345 ARA_Knickwinkel_Max 127;
BA_ "GenSigSendType" SG_ 345 ARA_Knickwinkel_Soll 3;
BA_ "GenSigStartValue" SG_ 345 ARA_Knickwinkel_Soll 254;
BA_ "Fehlerwert" SG_ 345 ARA_Knickwinkel_Soll 255;
BA_ "GenSigSendType" SG_ 345 ARA_Modus 0;
BA_ "GenSigSendType" SG_ 345 ARA_Modus_Anf 0;
BA_ "GenSigSendType" SG_ 345 ARA_Sensor_Aktivierung 3;
BA_ "GenSigSendType" SG_ 345 ARA_Status 3;
BA_ "GenSigStartValue" SG_ 345 ARA_Status 1;
BA_ "Fehlerwert" SG_ 345 ARA_Status 2;
BA_ "GenSigSendType" SG_ 345 ARA_Texte 0;
BA_ "Fehlerwert" SG_ 345 ARA_Texte 63;
BA_ "GenSigSendType" SG_ 893 AAG_ASTA_Status 0;
BA_ "GenSigSwitchedByIgnition" SG_ 893 AAG_ASTA_Status 0;
BA_ "Fehlerwert" SG_ 893 AAG_ASTA_Status 1;
BA_ "GenSigSendType" SG_ 893 ASTA_Anhaengerlast 0;
BA_ "GenSigStartValue" SG_ 893 ASTA_Anhaengerlast 8190;
BA_ "GenSigSwitchedByIgnition" SG_ 893 ASTA_Anhaengerlast 0;
BA_ "Fehlerwert" SG_ 893 ASTA_Anhaengerlast 8191;
BA_ "GenSigSendType" SG_ 893 ASTA_Einheit 0;
BA_ "GenSigSwitchedByIgnition" SG_ 893 ASTA_Einheit 0;
BA_ "Fehlerwert" SG_ 893 ASTA_Einheit 3;
BA_ "GenSigSendType" SG_ 893 ASTA_Stuetzlast 0;
BA_ "GenSigStartValue" SG_ 893 ASTA_Stuetzlast 510;
BA_ "GenSigSwitchedByIgnition" SG_ 893 ASTA_Stuetzlast 0;
BA_ "Fehlerwert" SG_ 893 ASTA_Stuetzlast 511;
BA_ "GenSigSendType" SG_ 893 ASTAs_01_alt 0;
BA_ "GenSigStartValue" SG_ 893 ASTAs_01_alt 1;
BA_ "GenSigFuncType" SG_ 893 ASTAs_01_alt 5;
BA_ "GenSigSwitchedByIgnition" SG_ 893 ASTAs_01_alt 0;
BA_ "GenSigSendType" SG_ 893 ASTAs_01_upd 0;
BA_ "GenSigFuncType" SG_ 893 ASTAs_01_upd 5;
BA_ "GenSigSwitchedByIgnition" SG_ 893 ASTAs_01_upd 0;
BA_ "GenSigSendType" SG_ 2549880935 AuthTime_eCall_Req_Data 3;
BA_ "GenSigFuncType" SG_ 2549880935 AuthTime_eCall_Req_Data 9;
BA_ "GenSigSwitchedByIgnition" SG_ 2549880935 AuthTime_eCall_Req_Data 0;
BA_ "GenSigSendType" SG_ 2550012007 AuthTime_eCall_Resp_Data 3;
BA_ "GenSigFuncType" SG_ 2550012007 AuthTime_eCall_Resp_Data 9;
BA_ "GenSigSwitchedByIgnition" SG_ 2550012007 AuthTime_eCall_Resp_Data 0;
BA_ "GenSigSendType" SG_ 2527679661 AWV_AW_Abstand 3;
BA_ "GenSigStartValue" SG_ 2527679661 AWV_AW_Abstand 511;
BA_ "GenSigSendType" SG_ 2527679661 AWV_AW_Texte 3;
BA_ "GenSigSendType" SG_ 2527679661 AWV_AW_Texte_Zusatzanzeige 3;
BA_ "GenSigSendType" SG_ 2527679661 AWV_AW_Zeitluecke 3;
BA_ "GenSigSendType" SG_ 2527679661 AWV_Einstellung_System_FSG 3;
BA_ "GenSigSendType" SG_ 2527679661 AWV_Einstellung_Warnung_FSG 3;
BA_ "GenSigSendType" SG_ 2527679661 AWV_KA_Konfiguration 3;
BA_ "GenSigSendType" SG_ 2527679661 AWV_KA_ObjektFront 3;
BA_ "GenSigSendType" SG_ 2527679661 AWV_Kamera_Objekt_ID 3;
BA_ "GenSigSwitchedByIgnition" SG_ 2527679661 AWV_Kamera_Objekt_ID 0;
BA_ "GenSigSendType" SG_ 2527679661 AWV_LED_Leiste 3;
BA_ "GenSigSendType" SG_ 2527679661 AWV_Priowarnung 3;
BA_ "GenSigSendType" SG_ 2527679661 AWV_Status_Anzeige 3;
BA_ "GenSigSendType" SG_ 2527679661 AWV_Texte_02 3;
BA_ "GenSigSendType" SG_ 2527679661 AWV_Warnlevel 3;
BA_ "GenSigSendType" SG_ 2527679661 AWV_Warnung 3;
BA_ "GenSigSendType" SG_ 2527679661 AWV_Warnung_Richtung 3;
BA_ "GenSigSendType" SG_ 2527679661 WBA_Warnblinken 3;
BA_ "GenSigSendType" SG_ 2463978752 AZK_Kessy_defekt 4;
BA_ "GenSigSwitchedByIgnition" SG_ 2463978752 AZK_Kessy_defekt 0;
BA_ "GenSigSendType" SG_ 2463978752 AZK_Kessy_nicht_gefunden 4;
BA_ "GenSigSwitchedByIgnition" SG_ 2463978752 AZK_Kessy_nicht_gefunden 0;
BA_ "GenSigSendType" SG_ 2463978752 AZK_MobileKey_defekt 4;
BA_ "GenSigSwitchedByIgnition" SG_ 2463978752 AZK_MobileKey_defekt 0;
BA_ "GenSigSendType" SG_ 2463978752 AZK_Mobilgeraet_nicht_gefunden 4;
BA_ "GenSigSwitchedByIgnition" SG_ 2463978752 AZK_Mobilgeraet_nicht_gefunden 0;
BA_ "GenSigSendType" SG_ 2463978752 AZK_Schluessel_im_Fzg 4;
BA_ "GenSigSwitchedByIgnition" SG_ 2463978752 AZK_Schluessel_im_Fzg 0;
BA_ "GenSigSendType" SG_ 2463978752 AZK_Schluessel_nicht_gefunden 4;
BA_ "GenSigSwitchedByIgnition" SG_ 2463978752 AZK_Schluessel_nicht_gefunden 0;
BA_ "GenSigSendType" SG_ 2463978752 AZK_Weiterfahrt_mit_Mobilgeraet 4;
BA_ "GenSigSwitchedByIgnition" SG_ 2463978752 AZK_Weiterfahrt_mit_Mobilgeraet 0;
BA_ "GenSigSendType" SG_ 2463978752 AZK_Weiterfahrt_mit_Schluessel 4;
BA_ "GenSigSwitchedByIgnition" SG_ 2463978752 AZK_Weiterfahrt_mit_Schluessel 0;
BA_REL_ "GenSigTimeoutTime" BU_SG_REL_ HUD SG_ 768 ACC_Tempolimit 600;
BA_REL_ "GenSigTimeoutTime" BU_SG_REL_ HUD SG_ 768 ACC_Warnung_Verkehrszeichen_1 600;
BA_REL_ "GenSigTimeoutTime" BU_SG_REL_ HUD SG_ 768 ACA_Querfuehrung 600;
BA_REL_ "GenSigTimeoutTime" BU_SG_REL_ HUD SG_ 768 ACC_Wunschgeschw_02 600;
BA_REL_ "GenSigTimeoutTime" BU_SG_REL_ HUD SG_ 768 ACC_Abstandsindex_02 600;
BA_REL_ "GenSigTimeoutTime" BU_SG_REL_ HUD SG_ 768 ACC_Gesetzte_Zeitluecke 600;
BA_REL_ "GenSigTimeoutTime" BU_SG_REL_ HUD SG_ 768 ACC_Optischer_Fahrerhinweis 600;
BA_REL_ "GenSigTimeoutTime" BU_SG_REL_ HUD SG_ 768 ACC_Warnhinweis 600;
BA_REL_ "GenSigTimeoutTime" BU_SG_REL_ HUD SG_ 768 ACC_EGO_Fahrzeug 600;
BA_REL_ "GenSigTimeoutTime" BU_SG_REL_ HUD SG_ 768 ACC_Relevantes_Objekt_02 600;
BA_REL_ "GenSigTimeoutTime" BU_SG_REL_ HUD SG_ 768 ACC_Anzeige_Zeitluecke 600;
BA_REL_ "GenSigTimeoutTime" BU_SG_REL_ HUD SG_ 768 ACC_Texte_Primaeranz_03 600;
BA_REL_ "GenSigTimeoutTime" BU_SG_REL_ HUD SG_ 768 ACC_Texte_Zusatzanz_03 600;
BA_REL_ "GenSigTimeoutTime" BU_SG_REL_ HUD SG_ 768 ACC_Regelgeschw 600;
BA_REL_ "GenSigTimeoutTime" BU_SG_REL_ HUD SG_ 768 ACC_RUV 600;
BA_REL_ "GenSigTimeoutTime" BU_SG_REL_ HUD SG_ 768 ACC_Status_GRA_Modus 600;
BA_REL_ "GenSigTimeoutTime" BU_SG_REL_ HUD SG_ 768 ACC_FoD_Status 600;
BA_REL_ "GenSigTimeoutTime" BU_SG_REL_ HUD SG_ 768 ACC_Status_Anzeige 600;
BA_REL_ "GenSigTimeoutTime" BU_SG_REL_ HUD SG_ 768 ACC_Texte_Sekundaeranz_03 600;
BA_REL_ "GenSigTimeoutTime" BU_SG_REL_ HUD SG_ 768 ACC_Statusicon 600;
BA_REL_ "GenSigTimeoutTime" BU_SG_REL_ HUD SG_ 768 ACC_Anzeige_Objektregelung 600;
BA_REL_ "GenSigTimeoutTime" BU_SG_REL_ HUD SG_ 768 ACC_Typ_LNS 600;
BA_REL_ "GenSigTimeoutTime" BU_SG_REL_ HUD SG_ 768 ACC_Typ_RNS 600;
BA_REL_ "GenSigTimeoutTime" BU_SG_REL_ HUD SG_ 768 ACC_Typ_WZO 600;
BA_REL_ "GenSigTimeoutTime" BU_SG_REL_ HUD SG_ 768 ACC_iBoost_Anzeige 600;
BA_REL_ "GenSigTimeoutTime" BU_SG_REL_ HUD SG_ 859 ACC_Obj_01_dx_v 800;
BA_REL_ "GenSigTimeoutTime" BU_SG_REL_ HUD SG_ 859 ACC_Obj_01_dy_v 800;
BA_REL_ "GenSigTimeoutTime" BU_SG_REL_ HUD SG_ 859 ACC_Obj_01_vx_v 800;
BA_REL_ "GenSigTimeoutTime" BU_SG_REL_ HUD SG_ 2331595990 ACC_Obj_02_dx_v 5000;
BA_REL_ "GenSigTimeoutTime" BU_SG_REL_ HUD SG_ 2331595990 ACC_Obj_02_dy_v 5000;
BA_REL_ "GenSigTimeoutTime" BU_SG_REL_ HUD SG_ 2331595990 ACC_Obj_02_vx_v 5000;
BA_REL_ "GenSigTimeoutTime" BU_SG_REL_ HUD SG_ 2331596021 ACC_Obj_05_dx_v 5000;
BA_REL_ "GenSigTimeoutTime" BU_SG_REL_ HUD SG_ 2331596021 ACC_Obj_05_dy_v 5000;
BA_REL_ "GenSigTimeoutTime" BU_SG_REL_ HUD SG_ 2331596021 ACC_Obj_05_vx_v 5000;
BA_REL_ "GenSigTimeoutTime" BU_SG_REL_ HUD SG_ 308 ALR_gMeter_ax 500;
BA_REL_ "GenSigTimeoutTime" BU_SG_REL_ HUD SG_ 308 ALR_gMeter_ay 500;
BA_REL_ "GenSigTimeoutTime" BU_SG_REL_ HUD SG_ 2527679661 AWV_Warnung 2000;
BA_REL_ "GenSigTimeoutTime" BU_SG_REL_ HUD SG_ 2527679661 AWV_Warnung_Richtung 2000;
BA_REL_ "GenSigTimeoutTime" BU_SG_REL_ Kombi SG_ 2589283940 AC_KBI_Sec_View_Request 5000;
BA_REL_ "GenSigTimeoutTime" BU_SG_REL_ Kombi SG_ 2589283940 AC_KBI_View_Request 5000;
BA_REL_ "GenSigTimeoutTime" BU_SG_REL_ Kombi SG_ 768 ACC_FzgStatus_Kamerafusion 600;
BA_REL_ "GenSigTimeoutTime" BU_SG_REL_ Kombi SG_ 768 ACC_FzgStatus_Anfahrbereitschaft 600;
BA_REL_ "GenSigTimeoutTime" BU_SG_REL_ Kombi SG_ 768 ACC_FzgStatus_Fehleranzeige 600;
BA_REL_ "GenSigTimeoutTime" BU_SG_REL_ Kombi SG_ 768 ACC_ENG_Texte_02 600;
BA_REL_ "GenSigTimeoutTime" BU_SG_REL_ Kombi SG_ 768 ACC_Tempolimit 600;
BA_REL_ "GenSigTimeoutTime" BU_SG_REL_ Kombi SG_ 768 ACC_Warnung_Verkehrszeichen_1 600;
BA_REL_ "GenSigTimeoutTime" BU_SG_REL_ Kombi SG_ 768 ACA_Querfuehrung 600;
BA_REL_ "GenSigTimeoutTime" BU_SG_REL_ Kombi SG_ 768 ACC_Wunschgeschw_Farbe_02 600;
BA_REL_ "GenSigTimeoutTime" BU_SG_REL_ Kombi SG_ 768 ACC_Wunschgeschw_02 600;
BA_REL_ "GenSigTimeoutTime" BU_SG_REL_ Kombi SG_ 768 ACC_Abstandsindex_02 600;
BA_REL_ "GenSigTimeoutTime" BU_SG_REL_ Kombi SG_ 768 ACC_Display_Prio 600;
BA_REL_ "GenSigTimeoutTime" BU_SG_REL_ Kombi SG_ 768 ACC_rel_Objekt_Zusatzanz 600;
BA_REL_ "GenSigTimeoutTime" BU_SG_REL_ Kombi SG_ 768 ACC_Gesetzte_Zeitluecke 600;
BA_REL_ "GenSigTimeoutTime" BU_SG_REL_ Kombi SG_ 768 ACC_Optischer_Fahrerhinweis 600;
BA_REL_ "GenSigTimeoutTime" BU_SG_REL_ Kombi SG_ 768 ACC_Warnhinweis 600;
BA_REL_ "GenSigTimeoutTime" BU_SG_REL_ Kombi SG_ 768 ACC_EGO_Fahrzeug 600;
BA_REL_ "GenSigTimeoutTime" BU_SG_REL_ Kombi SG_ 768 ACC_Relevantes_Objekt_02 600;
BA_REL_ "GenSigTimeoutTime" BU_SG_REL_ Kombi SG_ 768 ACC_Anzeige_Zeitluecke 600;
BA_REL_ "GenSigTimeoutTime" BU_SG_REL_ Kombi SG_ 768 ACC_Texte_Primaeranz_03 600;
BA_REL_ "GenSigTimeoutTime" BU_SG_REL_ Kombi SG_ 768 ACC_Texte_Zusatzanz_03 600;
BA_REL_ "GenSigTimeoutTime" BU_SG_REL_ Kombi SG_ 768 ACC_Regelgeschw 600;
BA_REL_ "GenSigTimeoutTime" BU_SG_REL_ Kombi SG_ 768 ACC_Einheit_maxSetzgeschw 600;
BA_REL_ "GenSigTimeoutTime" BU_SG_REL_ Kombi SG_ 768 ACC_maxSetzgeschw 600;
BA_REL_ "GenSigTimeoutTime" BU_SG_REL_ Kombi SG_ 768 ACC_Tempolimit_Einheit 600;
BA_REL_ "GenSigTimeoutTime" BU_SG_REL_ Kombi SG_ 768 ACC_RUV 600;
BA_REL_ "GenSigTimeoutTime" BU_SG_REL_ Kombi SG_ 768 ACC_Tachokranz 600;
BA_REL_ "GenSigTimeoutTime" BU_SG_REL_ Kombi SG_ 768 ACC_Typ_Tachokranz_unten 600;
BA_REL_ "GenSigTimeoutTime" BU_SG_REL_ Kombi SG_ 768 ACC_ENG_Texte 600;
BA_REL_ "GenSigTimeoutTime" BU_SG_REL_ Kombi SG_ 768 ACC_Status_GRA_Modus 600;
BA_REL_ "GenSigTimeoutTime" BU_SG_REL_ Kombi SG_ 768 ACA_Querfuehrung_Texte 600;
BA_REL_ "GenSigTimeoutTime" BU_SG_REL_ Kombi SG_ 768 ACC_FoD_Status 600;
BA_REL_ "GenSigTimeoutTime" BU_SG_REL_ Kombi SG_ 768 ACC_Status_Anzeige 600;
BA_REL_ "GenSigTimeoutTime" BU_SG_REL_ Kombi SG_ 768 ACC_Akustik_03 600;
BA_REL_ "GenSigTimeoutTime" BU_SG_REL_ Kombi SG_ 768 ACC_Texte_02 600;
BA_REL_ "GenSigTimeoutTime" BU_SG_REL_ Kombi SG_ 768 ACC_Texte_Sekundaeranz_03 600;
BA_REL_ "GenSigTimeoutTime" BU_SG_REL_ Kombi SG_ 768 ACC_Modus_Pop_Up 600;
BA_REL_ "GenSigTimeoutTime" BU_SG_REL_ Kombi SG_ 768 ACC_Statusicon 600;
BA_REL_ "GenSigTimeoutTime" BU_SG_REL_ Kombi SG_ 768 ACC_Anzeige_Objektregelung 600;
BA_REL_ "GenSigTimeoutTime" BU_SG_REL_ Kombi SG_ 768 ACC_Anzeige_Maximalabstand 600;
BA_REL_ "GenSigTimeoutTime" BU_SG_REL_ Kombi SG_ 768 ACC_Typ_LNS 600;
BA_REL_ "GenSigTimeoutTime" BU_SG_REL_ Kombi SG_ 768 ACC_Typ_RNS 600;
BA_REL_ "GenSigTimeoutTime" BU_SG_REL_ Kombi SG_ 768 ACC_Typ_WZO 600;
BA_REL_ "GenSigTimeoutTime" BU_SG_REL_ Kombi SG_ 768 ACC_Abstand_WZO 600;
BA_REL_ "GenSigTimeoutTime" BU_SG_REL_ Kombi SG_ 768 ACC_Abstand_RNS 600;
BA_REL_ "GenSigTimeoutTime" BU_SG_REL_ Kombi SG_ 768 ACC_Abstand_LNS 600;
BA_REL_ "GenSigTimeoutTime" BU_SG_REL_ Kombi SG_ 768 ACC_Texte_03 600;
BA_REL_ "GenSigTimeoutTime" BU_SG_REL_ Kombi SG_ 768 ACC_iBoost_Anzeige 600;
BA_REL_ "GenSigTimeoutTime" BU_SG_REL_ Kombi SG_ 768 ACC_Texte_Sekundaeranz_02 600;
BA_REL_ "GenSigTimeoutTime" BU_SG_REL_ Kombi SG_ 768 ACC_Sollabstand_1 600;
BA_REL_ "GenSigTimeoutTime" BU_SG_REL_ Kombi SG_ 768 ACC_Sollabstand_2 600;
BA_REL_ "GenSigTimeoutTime" BU_SG_REL_ Kombi SG_ 768 ACC_Sollabstand_3 600;
BA_REL_ "GenSigTimeoutTime" BU_SG_REL_ Kombi SG_ 768 ACC_Sollabstand_4 600;
BA_REL_ "GenSigTimeoutTime" BU_SG_REL_ Kombi SG_ 768 ACC_Sollabstand_5 600;
BA_REL_ "GenSigTimeoutTime" BU_SG_REL_ Kombi SG_ 2527679923 ADA_HMI_Ablenkung_Deaktivierung 5000;
BA_REL_ "GenSigTimeoutTime" BU_SG_REL_ Kombi SG_ 2527679923 ADA_HMI_Ablenkung_Fehler_Popup 5000;
BA_REL_ "GenSigTimeoutTime" BU_SG_REL_ Kombi SG_ 2527679923 ADA_HMI_Ablenkung_Meldeakustik 5000;
BA_REL_ "GenSigTimeoutTime" BU_SG_REL_ Kombi SG_ 2527679923 ADA_HMI_Ablenkung_Meldung 5000;
BA_REL_ "GenSigTimeoutTime" BU_SG_REL_ Kombi SG_ 2527679923 ADA_HMI_Fahrzeit_seit_Pause 5000;
BA_REL_ "GenSigTimeoutTime" BU_SG_REL_ Kombi SG_ 2527679923 ADA_HMI_Muedigkeit_Deaktivierung 5000;
BA_REL_ "GenSigTimeoutTime" BU_SG_REL_ Kombi SG_ 2527679923 ADA_HMI_Muedigkeit_Fehler_Popup 5000;
BA_REL_ "GenSigTimeoutTime" BU_SG_REL_ Kombi SG_ 2527679923 ADA_HMI_Muedigkeit_Meldeakustik 5000;
BA_REL_ "GenSigTimeoutTime" BU_SG_REL_ Kombi SG_ 2527679923 ADA_HMI_Muedigkeit_Meldung 5000;
BA_REL_ "GenSigTimeoutTime" BU_SG_REL_ Kombi SG_ 2527679923 ADA_HMI_Muedigkeit_Event_Meldung 5000;
BA_REL_ "GenSigTimeoutTime" BU_SG_REL_ Kombi SG_ 2527679923 ADA_DrowsinessSystemState 5000;
BA_REL_ "GenSigTimeoutTime" BU_SG_REL_ Kombi SG_ 1660 AGA_Texte 5000;
BA_REL_ "GenSigTimeoutTime" BU_SG_REL_ Kombi SG_ 1660 AGA_ohne_Funktion 5000;
BA_REL_ "GenSigTimeoutTime" BU_SG_REL_ Kombi SG_ 64 Airbag_01_CRC 500;
BA_REL_ "GenSigTimeoutTime" BU_SG_REL_ Kombi SG_ 64 Airbag_01_BZ 500;
BA_REL_ "GenSigTimeoutTime" BU_SG_REL_ Kombi SG_ 64 AB_Lampe 500;
BA_REL_ "GenSigTimeoutTime" BU_SG_REL_ Kombi SG_ 64 AB_Deaktiviert 500;
BA_REL_ "GenSigTimeoutTime" BU_SG_REL_ Kombi SG_ 64 AB_Systemfehler 500;
BA_REL_ "GenSigTimeoutTime" BU_SG_REL_ Kombi SG_ 64 AB_Erh_Auf_VB 500;
BA_REL_ "GenSigTimeoutTime" BU_SG_REL_ Kombi SG_ 64 AB_Gurtwarn_VF 500;
BA_REL_ "GenSigTimeoutTime" BU_SG_REL_ Kombi SG_ 64 AB_Gurtwarn_VB 500;
BA_REL_ "GenSigTimeoutTime" BU_SG_REL_ Kombi SG_ 64 AB_Anzeige_Fussg 500;
BA_REL_ "GenSigTimeoutTime" BU_SG_REL_ Kombi SG_ 64 AB_Versorgungsspannung 500;
BA_REL_ "GenSigTimeoutTime" BU_SG_REL_ Kombi SG_ 64 AB_Belegung_VF 500;
BA_REL_ "GenSigTimeoutTime" BU_SG_REL_ Kombi SG_ 64 AB_eCS_Error 500;
BA_REL_ "GenSigTimeoutTime" BU_SG_REL_ Kombi SG_ 1312 AB_Belegung_VB 2000;
BA_REL_ "GenSigTimeoutTime" BU_SG_REL_ Kombi SG_ 1312 AB_Gurtschloss_Reihe2_FA 2000;
BA_REL_ "GenSigTimeoutTime" BU_SG_REL_ Kombi SG_ 1312 AB_Gurtschloss_Reihe2_MI 2000;
BA_REL_ "GenSigTimeoutTime" BU_SG_REL_ Kombi SG_ 1312 AB_Gurtschloss_Reihe2_BF 2000;
BA_REL_ "GenSigTimeoutTime" BU_SG_REL_ Kombi SG_ 1312 AB_Gurtschloss_Reihe3_FA 2000;
BA_REL_ "GenSigTimeoutTime" BU_SG_REL_ Kombi SG_ 1312 AB_Gurtschloss_Reihe3_MI 2000;
BA_REL_ "GenSigTimeoutTime" BU_SG_REL_ Kombi SG_ 1312 AB_Gurtschloss_Reihe3_BF 2000;
BA_REL_ "GenSigTimeoutTime" BU_SG_REL_ Kombi SG_ 1349 AB_Gurtwarn_Reihe4_FA 2000;
BA_REL_ "GenSigTimeoutTime" BU_SG_REL_ Kombi SG_ 1349 AB_Gurtwarn_Reihe4_BF 2000;
BA_REL_ "GenSigTimeoutTime" BU_SG_REL_ Kombi SG_ 1349 AB_Gurtwarn_Reihe4_MI 2000;
BA_REL_ "GenSigTimeoutTime" BU_SG_REL_ Kombi SG_ 1349 AB_Gurtwarn_Reihe2_FA 2000;
BA_REL_ "GenSigTimeoutTime" BU_SG_REL_ Kombi SG_ 1349 AB_Gurtwarn_Reihe2_BF 2000;
BA_REL_ "GenSigTimeoutTime" BU_SG_REL_ Kombi SG_ 1349 AB_Gurtwarn_Reihe2_MI 2000;
BA_REL_ "GenSigTimeoutTime" BU_SG_REL_ Kombi SG_ 1349 AB_Gurtwarn_Reihe3_FA 2000;
BA_REL_ "GenSigTimeoutTime" BU_SG_REL_ Kombi SG_ 1349 AB_Gurtwarn_Reihe3_MI 2000;
BA_REL_ "GenSigTimeoutTime" BU_SG_REL_ Kombi SG_ 1349 AB_Gurtwarn_Reihe3_BF 2000;
BA_REL_ "GenSigTimeoutTime" BU_SG_REL_ Kombi SG_ 1349 AB_SBR_hinten_verbau 2000;
BA_REL_ "GenSigTimeoutTime" BU_SG_REL_ Kombi SG_ 2527679722 Airbag_06_CRC 2000;
BA_REL_ "GenSigTimeoutTime" BU_SG_REL_ Kombi SG_ 2527679722 Airbag_06_BZ 2000;
BA_REL_ "GenSigTimeoutTime" BU_SG_REL_ Kombi SG_ 2527679722 AB_Gurtschloss_Reihe4_FA 2000;
BA_REL_ "GenSigTimeoutTime" BU_SG_REL_ Kombi SG_ 2527679722 AB_Gurtschloss_Reihe4_BF 2000;
BA_REL_ "GenSigTimeoutTime" BU_SG_REL_ Kombi SG_ 2527679722 AB_Gurtschloss_Reihe4_MI 2000;
BA_REL_ "GenSigTimeoutTime" BU_SG_REL_ Kombi SG_ 2527679722 AB_wSBR_Batteriestatus 2000;
BA_REL_ "GenSigTimeoutTime" BU_SG_REL_ Kombi SG_ 2527679722 AB_Gurtwarn_VM 2000;
BA_REL_ "GenSigTimeoutTime" BU_SG_REL_ Kombi SG_ 2527679722 AB_Gurtschloss_MI 2000;
BA_REL_ "GenSigTimeoutTime" BU_SG_REL_ Kombi SG_ 2527679722 AB_Anzeige_Kombi_SRAB 2000;
BA_REL_ "GenSigTimeoutTime" BU_SG_REL_ Kombi SG_ 280 ALR_Warnlampe 1000;
BA_REL_ "GenSigTimeoutTime" BU_SG_REL_ Kombi SG_ 308 ALR_gMeter_ax 500;
BA_REL_ "GenSigTimeoutTime" BU_SG_REL_ Kombi SG_ 308 ALR_gMeter_ay 500;
BA_REL_ "GenSigTimeoutTime" BU_SG_REL_ Kombi SG_ 1633 AAG_Blinker_H_aktiv 1000;
BA_REL_ "GenSigTimeoutTime" BU_SG_REL_ Kombi SG_ 1633 AAG_Blinker_HL_def 1000;
BA_REL_ "GenSigTimeoutTime" BU_SG_REL_ Kombi SG_ 1633 AAG_Blinker_HR_def 1000;
BA_REL_ "GenSigTimeoutTime" BU_SG_REL_ Kombi SG_ 1633 AAG_Bremslicht_H_def 1000;
BA_REL_ "GenSigTimeoutTime" BU_SG_REL_ Kombi SG_ 1633 AAG_Schlusslicht_HL_def 1000;
BA_REL_ "GenSigTimeoutTime" BU_SG_REL_ Kombi SG_ 1633 AAG_Schlusslicht_HR_def 1000;
BA_REL_ "GenSigTimeoutTime" BU_SG_REL_ Kombi SG_ 1633 AAG_AVS_Fehler_02 1000;
BA_REL_ "GenSigTimeoutTime" BU_SG_REL_ Kombi SG_ 345 ARA_Texte 1000;
BA_REL_ "GenSigTimeoutTime" BU_SG_REL_ Kombi SG_ 345 ARA_Modus 1000;
BA_REL_ "GenSigTimeoutTime" BU_SG_REL_ Kombi SG_ 345 ARA_Aktiver_Grafikmodus 1000;
BA_REL_ "GenSigTimeoutTime" BU_SG_REL_ Kombi SG_ 345 ARA_Bremsfuss 1000;
BA_REL_ "GenSigTimeoutTime" BU_SG_REL_ Kombi SG_ 345 ARA_Knickwinkel_Max 1000;
BA_REL_ "GenSigTimeoutTime" BU_SG_REL_ Kombi SG_ 345 ARA_Knickwinkel_Soll 1000;
BA_REL_ "GenSigTimeoutTime" BU_SG_REL_ Kombi SG_ 345 ARA_Knickwinkel_Ist 1000;
BA_REL_ "GenSigTimeoutTime" BU_SG_REL_ Kombi SG_ 893 ASTA_Stuetzlast 5000;
BA_REL_ "GenSigTimeoutTime" BU_SG_REL_ Kombi SG_ 893 ASTA_Einheit 5000;
BA_REL_ "GenSigTimeoutTime" BU_SG_REL_ Kombi SG_ 893 ASTA_Anhaengerlast 5000;
BA_REL_ "GenSigTimeoutTime" BU_SG_REL_ Kombi SG_ 893 AAG_ASTA_Status 5000;
BA_REL_ "GenSigTimeoutTime" BU_SG_REL_ Kombi SG_ 893 ASTAs_01_alt 5000;
BA_REL_ "GenSigTimeoutTime" BU_SG_REL_ Kombi SG_ 2527679661 AWV_Warnung 2000;
BA_REL_ "GenSigTimeoutTime" BU_SG_REL_ Kombi SG_ 2527679661 AWV_Texte_02 2000;
BA_REL_ "GenSigTimeoutTime" BU_SG_REL_ Kombi SG_ 2527679661 AWV_Status_Anzeige 2000;
BA_REL_ "GenSigTimeoutTime" BU_SG_REL_ Kombi SG_ 2527679661 AWV_AW_Abstand 2000;
BA_REL_ "GenSigTimeoutTime" BU_SG_REL_ Kombi SG_ 2527679661 AWV_AW_Zeitluecke 2000;
BA_REL_ "GenSigTimeoutTime" BU_SG_REL_ Kombi SG_ 2527679661 AWV_AW_Texte 2000;
BA_REL_ "GenSigTimeoutTime" BU_SG_REL_ Kombi SG_ 2527679661 AWV_AW_Texte_Zusatzanzeige 2000;
BA_REL_ "GenSigTimeoutTime" BU_SG_REL_ Kombi SG_ 2527679661 AWV_Warnung_Richtung 2000;
BA_REL_ "GenSigTimeoutTime" BU_SG_REL_ Kombi SG_ 2463978752 AZK_Kessy_defekt 5000;
BA_REL_ "GenSigTimeoutTime" BU_SG_REL_ Kombi SG_ 2463978752 AZK_Kessy_nicht_gefunden 5000;
BA_REL_ "GenSigTimeoutTime" BU_SG_REL_ Kombi SG_ 2463978752 AZK_MobileKey_defekt 5000;
BA_REL_ "GenSigTimeoutTime" BU_SG_REL_ Kombi SG_ 2463978752 AZK_Mobilgeraet_nicht_gefunden 5000;
BA_REL_ "GenSigTimeoutTime" BU_SG_REL_ Kombi SG_ 2463978752 AZK_Schluessel_im_Fzg 5000;
BA_REL_ "GenSigTimeoutTime" BU_SG_REL_ Kombi SG_ 2463978752 AZK_Schluessel_nicht_gefunden 5000;
VAL_ 2589283940 AC_KBI_Sec_View_Request 0 "noRequest" 1 "Deaktiviert" 2 "Aktiviert" ;
VAL_ 2589283940 AC_KBI_View_Request 0 "noRequest" 1 "View1" 2 "View2" 3 "View3" 4 "View4" 5 "View5" 6 "View6" 7 "View7" 8 "View8" 9 "View9" 10 "View10" 11 "View11" 12 "View12" 13 "View13" 14 "View14" 15 "View15" 16 "View16" 17 "View17" 18 "View18" 19 "View19" 20 "View20" 21 "View21" 22 "View22" 23 "View23" 24 "View24" 25 "reserved" 26 "reserved" 27 "reserved" 28 "reserved" 29 "reserved" 30 "reserved" 31 "reserved" ;
VAL_ 2589283940 AC_FES_Aktive_Atmosphere 0 "keineAnsteuerung" 1 "Atmosphere_1" 2 "Atmosphere_2" 3 "Atmosphere_3" 4 "Atmosphere_4" 5 "Atmosphere_5" 6 "Atmosphere_6" 7 "Atmosphere_7" 8 "Atmosphere_8" 9 "Atmosphere_9" 10 "Atmosphere_10" 11 "Atmosphere_11" 12 "Atmosphere_12" 13 "Atmosphere_13" 14 "Atmosphere_14" 15 "Atmosphere_15" 16 "Atmosphere_16" 17 "Atmosphere_17" 18 "Atmosphere_18" 19 "Atmosphere_19" 20 "Atmosphere_20" 21 "Atmosphere_21" 22 "Atmosphere_22" 23 "Atmosphere_23" 24 "Atmosphere_24" 25 "Atmosphere_25" 26 "Atmosphere_26" 27 "Atmosphere_27" 28 "Atmosphere_28" 29 "Atmosphere_29" 30 "Atmosphere_30" 31 "Atmosphere_31" 32 "Atmosphere_32" ;
VAL_ 2589283940 AC_FES_Atmosphere_1 0 "kein_Profil" 1 "Atmosphere_1" 2 "Atmosphere_2" 3 "Atmosphere_3" 4 "Atmosphere_4" 5 "Atmosphere_5" 6 "Atmosphere_6" 7 "Atmosphere_7" 8 "Atmosphere_8" 9 "Atmosphere_9" 10 "Atmosphere_10" 11 "Atmosphere_11" 12 "Atmosphere_12" 13 "Atmosphere_13" 14 "Atmosphere_14" 15 "Atmosphere_15" 16 "Atmosphere_16" 17 "Atmosphere_17" 18 "Atmosphere_18" 19 "Atmosphere_19" 20 "Atmosphere_20" 21 "Atmosphere_21" 22 "Atmosphere_22" 23 "Atmosphere_23" 24 "Atmosphere_24" 25 "Atmosphere_25" 26 "Atmosphere_26" 27 "Atmosphere_27" 28 "Atmosphere_28" 29 "Atmosphere_29" 30 "Atmosphere_30" 31 "Atmosphere_31" 32 "Atmosphere_32" ;
VAL_ 2589283940 AC_FES_Atmosphere_2 0 "kein_Profil" 1 "Atmosphere_1" 2 "Atmosphere_2" 3 "Atmosphere_3" 4 "Atmosphere_4" 5 "Atmosphere_5" 6 "Atmosphere_6" 7 "Atmosphere_7" 8 "Atmosphere_8" 9 "Atmosphere_9" 10 "Atmosphere_10" 11 "Atmosphere_11" 12 "Atmosphere_12" 13 "Atmosphere_13" 14 "Atmosphere_14" 15 "Atmosphere_15" 16 "Atmosphere_16" 17 "Atmosphere_17" 18 "Atmosphere_18" 19 "Atmosphere_19" 20 "Atmosphere_20" 21 "Atmosphere_21" 22 "Atmosphere_22" 23 "Atmosphere_23" 24 "Atmosphere_24" 25 "Atmosphere_25" 26 "Atmosphere_26" 27 "Atmosphere_27" 28 "Atmosphere_28" 29 "Atmosphere_29" 30 "Atmosphere_30" 31 "Atmosphere_31" 32 "Atmosphere_32" ;
VAL_ 2589283940 AC_FES_Atmosphere_3 0 "kein_Profil" 1 "Atmosphere_1" 2 "Atmosphere_2" 3 "Atmosphere_3" 4 "Atmosphere_4" 5 "Atmosphere_5" 6 "Atmosphere_6" 7 "Atmosphere_7" 8 "Atmosphere_8" 9 "Atmosphere_9" 10 "Atmosphere_10" 11 "Atmosphere_11" 12 "Atmosphere_12" 13 "Atmosphere_13" 14 "Atmosphere_14" 15 "Atmosphere_15" 16 "Atmosphere_16" 17 "Atmosphere_17" 18 "Atmosphere_18" 19 "Atmosphere_19" 20 "Atmosphere_20" 21 "Atmosphere_21" 22 "Atmosphere_22" 23 "Atmosphere_23" 24 "Atmosphere_24" 25 "Atmosphere_25" 26 "Atmosphere_26" 27 "Atmosphere_27" 28 "Atmosphere_28" 29 "Atmosphere_29" 30 "Atmosphere_30" 31 "Atmosphere_31" 32 "Atmosphere_32" ;
VAL_ 2589283940 AC_FES_Atmosphere_4 0 "kein_Profil" 1 "Atmosphere_1" 2 "Atmosphere_2" 3 "Atmosphere_3" 4 "Atmosphere_4" 5 "Atmosphere_5" 6 "Atmosphere_6" 7 "Atmosphere_7" 8 "Atmosphere_8" 9 "Atmosphere_9" 10 "Atmosphere_10" 11 "Atmosphere_11" 12 "Atmosphere_12" 13 "Atmosphere_13" 14 "Atmosphere_14" 15 "Atmosphere_15" 16 "Atmosphere_16" 17 "Atmosphere_17" 18 "Atmosphere_18" 19 "Atmosphere_19" 20 "Atmosphere_20" 21 "Atmosphere_21" 22 "Atmosphere_22" 23 "Atmosphere_23" 24 "Atmosphere_24" 25 "Atmosphere_25" 26 "Atmosphere_26" 27 "Atmosphere_27" 28 "Atmosphere_28" 29 "Atmosphere_29" 30 "Atmosphere_30" 31 "Atmosphere_31" 32 "Atmosphere_32" ;
VAL_ 2589283940 AC_FES_Atmosphere_5 0 "kein_Profil" 1 "Atmosphere_1" 2 "Atmosphere_2" 3 "Atmosphere_3" 4 "Atmosphere_4" 5 "Atmosphere_5" 6 "Atmosphere_6" 7 "Atmosphere_7" 8 "Atmosphere_8" 9 "Atmosphere_9" 10 "Atmosphere_10" 11 "Atmosphere_11" 12 "Atmosphere_12" 13 "Atmosphere_13" 14 "Atmosphere_14" 15 "Atmosphere_15" 16 "Atmosphere_16" 17 "Atmosphere_17" 18 "Atmosphere_18" 19 "Atmosphere_19" 20 "Atmosphere_20" 21 "Atmosphere_21" 22 "Atmosphere_22" 23 "Atmosphere_23" 24 "Atmosphere_24" 25 "Atmosphere_25" 26 "Atmosphere_26" 27 "Atmosphere_27" 28 "Atmosphere_28" 29 "Atmosphere_29" 30 "Atmosphere_30" 31 "Atmosphere_31" 32 "Atmosphere_32" ;
VAL_ 2589283940 AC_FES_Atmosphere_6 0 "kein_Profil" 1 "Atmosphere_1" 2 "Atmosphere_2" 3 "Atmosphere_3" 4 "Atmosphere_4" 5 "Atmosphere_5" 6 "Atmosphere_6" 7 "Atmosphere_7" 8 "Atmosphere_8" 9 "Atmosphere_9" 10 "Atmosphere_10" 11 "Atmosphere_11" 12 "Atmosphere_12" 13 "Atmosphere_13" 14 "Atmosphere_14" 15 "Atmosphere_15" 16 "Atmosphere_16" 17 "Atmosphere_17" 18 "Atmosphere_18" 19 "Atmosphere_19" 20 "Atmosphere_20" 21 "Atmosphere_21" 22 "Atmosphere_22" 23 "Atmosphere_23" 24 "Atmosphere_24" 25 "Atmosphere_25" 26 "Atmosphere_26" 27 "Atmosphere_27" 28 "Atmosphere_28" 29 "Atmosphere_29" 30 "Atmosphere_30" 31 "Atmosphere_31" 32 "Atmosphere_32" ;
VAL_ 2589283940 AC_FES_Atmosphere_7 0 "kein_Profil" 1 "Atmosphere_1" 2 "Atmosphere_2" 3 "Atmosphere_3" 4 "Atmosphere_4" 5 "Atmosphere_5" 6 "Atmosphere_6" 7 "Atmosphere_7" 8 "Atmosphere_8" 9 "Atmosphere_9" 10 "Atmosphere_10" 11 "Atmosphere_11" 12 "Atmosphere_12" 13 "Atmosphere_13" 14 "Atmosphere_14" 15 "Atmosphere_15" 16 "Atmosphere_16" 17 "Atmosphere_17" 18 "Atmosphere_18" 19 "Atmosphere_19" 20 "Atmosphere_20" 21 "Atmosphere_21" 22 "Atmosphere_22" 23 "Atmosphere_23" 24 "Atmosphere_24" 25 "Atmosphere_25" 26 "Atmosphere_26" 27 "Atmosphere_27" 28 "Atmosphere_28" 29 "Atmosphere_29" 30 "Atmosphere_30" 31 "Atmosphere_31" 32 "Atmosphere_32" ;
VAL_ 768 ACC_FzgStatus_Kamerafusion 0 "keine_Anzeige" 1 "ACC_red_Objekterkennung" 2 "ACC_TA_red_Objekterkennung" ;
VAL_ 768 ACC_FzgStatus_Anfahrbereitschaft 0 "keine_Anzeige" 1 "ACC_red_Anfahrbereitschaft" 2 "ACC_TA_red_Anfahrbereitschaft" ;
VAL_ 768 ACC_FzgStatus_Fehleranzeige 0 "keine_Anzeige" 1 "ACC_Stoerung" 2 "ACC_und_GRA_Stoerung" 3 "ACC_nicht_verfuegbar" 4 "ACC_und_GRA_nicht_verfuegbar" 5 "ACC_keine_Sensorsicht" ;
VAL_ 768 ACC_ENG_Texte_02 0 "keine_Anzeige" 1 "keine_Laenderverfuegbarkeit" 2 "ACC_Vor_Strecke_n_verf" 3 "ACC_TA_Vor_Strecke_n_verf" 4 "ACC_Vor_Geschw_n_verf" 5 "ACC_TA_Vor_Geschw_n_verf" 6 "ACC_Vor_Strecke_Geschw_n_verf" 7 "ACC_TA_Vor_Strecke_Geschw_n_verf" ;
VAL_ 768 ACC_Tempolimit 0 "keine_Anzeige" 1 "5_zulHoechstgeschw" 2 "7_zulHoechstgeschw" 3 "10_zulHoechstgeschw" 4 "15_zulHoechstgeschw" 5 "20_zulHoechstgeschw" 6 "25_zulHoechstgeschw" 7 "30_zulHoechstgeschw" 8 "35_zulHoechstgeschw" 9 "40_zulHoechstgeschw" 10 "45_zulHoechstgeschw" 11 "50_zulHoechstgeschw" 12 "55_zulHoechstgeschw" 13 "60_zulHoechstgeschw" 14 "65_zulHoechstgeschw" 15 "70_zulHoechstgeschw" 16 "75_zulHoechstgeschw" 17 "80_zulHoechstgeschw" 18 "85_zulHoechstgeschw" 19 "90_zulHoechstgeschw" 20 "95_zulHoechstgeschw" 21 "100_zulHoechstgeschw" 22 "110_zulHoechstgeschw" 23 "120_zulHoechstgeschw" 24 "130_zulHoechstgeschw" 25 "140_zulHoechstgeschw" 26 "150_zulHoechstgeschw" 27 "160_zulHoechstgeschw" 28 "200_zulHoechstgeschw" 30 "250_zulHoechstgeschw" 31 "Ende_zulHoechstgeschw" ;
VAL_ 768 ACC_Wunschgeschw_Farbe 0 "Grundfarbe" 1 "Farbe_1" ;
VAL_ 768 ACC_Warnung_Verkehrszeichen_1 0 "keine_Warnung_Initialwert" 1 "Warnung" ;
VAL_ 768 ACA_Querfuehrung 0 "keine_Anzeige_oder_init" 1 "passiv" 2 "aktiv" 3 "Warnung" ;
VAL_ 768 ACC_Wunschgeschw_Farbe_02 0 "Grundfarbe" 1 "Farbe_1" 2 "Farbe_2" 3 "Farbe_3" ;
VAL_ 768 ACC_Regelung_AIO 0 "Regelung_Ampel_nicht_aktiv" 1 "Regelung_Ampel_aktiv" ;
VAL_ 768 ACC_Wunschgeschw_02 1023 "keine_Anzeige" ;
VAL_ 768 ACC_Abstandsindex_02 0 "Audi (Init), VW (passiv/aktiv_Freifahrt)" 1022 "aus_passiv" 1023 "aktiv_Freifahrt" ;
VAL_ 768 ACC_Display_Prio 0 "hoechste_Prio" 1 "mittlere_Prio" 2 "geringe_Prio" 3 "keine_Prio" ;
VAL_ 768 ACC_rel_Objekt_Zusatzanz 0 "keine Anzeige" 1 "Relevantes_Objekt_erkannt" 2 "Relevantes_Objekt_Abstandswarnung" ;
VAL_ 768 ACC_Gesetzte_Zeitluecke 0 "keine_Anzeige" 1 "Zeitluecke_1" 2 "Zeitluecke_2" 3 "Zeitluecke_3" 4 "Zeitluecke_4" 5 "Zeitluecke_5" 6 "nicht_definiert" 7 "nicht_definiert" ;
VAL_ 768 ACC_Optischer_Fahrerhinweis 0 "optischer_Fahrerhinweis_AUS" 1 "optischer_Fahrerhinweis_EIN" ;
VAL_ 768 ACC_Warnhinweis 0 "kein_Warnhinweis" 1 "Warnhinweis" ;
VAL_ 768 ACC_EGO_Fahrzeug 0 "keine_Anzeige" 1 "aktiv" 2 "Warnung" 3 "aktiv_stop" 4 "passiv" ;
VAL_ 768 ACC_Relevantes_Objekt_02 0 "keine_Anzeige" 1 "Relevantes_Objekt_erkannt" 2 "Relevantes_Objekt_Warnung" 3 "passiv" ;
VAL_ 768 ACC_Wunschgeschw_erreicht 0 "Wunschgeschwindigkeit_nicht_erreicht" 1 "Wunschgeschwindigkeit_erreicht" ;
VAL_ 768 ACC_Anzeige_Zeitluecke 0 "Anzeige_Zeitluecke_nicht_angefordert" 1 "Anzeige_Zeitluecke_angefordert" ;
VAL_ 768 ACC_Texte_Primaeranz_03 0 "keine_Anzeige" 1 "ACC_anfahrbereit" 2 "VDA_ACC_Symbol_YYY_kmh_mph" 3 "Kurven_Symbol_YYY_kmh_mph" 4 "Tempolimit_Symbol_YYY_kmh_mph" 5 "Kreuzungs_Symbol" 6 "Kreisverkehr_Symbol" 7 "Gefaelle_Symbol" 8 "Autobahnausfahrt_Symbol" 9 "Stauende_Symbol" 10 "Engstelle_Symbol" 11 "Tuer_offen" 12 "Fahrer_Gurtschloss_offen" 13 "praediktive_Regelung_Aktiv" 14 "Ampel_vertikal" 15 "Ampel_horizontal" 16 "STP_verfuegbar" 17 "GRA_Symbol" 18 "ACC_Freifahrt_Symbol" 19 "ACC_Folgefahrt_Symbol" ;
VAL_ 768 ACC_Texte_Zusatzanz_03 0 "keine_Anzeige" 1 "ACC_AUS" 2 "Standby" 3 "UEBERTRETEN" 4 "ABSTAND" 5 "Fahrprogramm_1" 6 "Fahrprogramm_2" 7 "Fahrprogramm_3" 8 "Fahrprogramm_4" 9 "Fahrprogramm_5" 10 "Fahrprogramm_6" 11 "ACHTUNG" 12 "STA_verfuegbar" 13 "Engstelle" 14 "RUV_aktiv_Rechtsverkehr" 15 "RUV_aktiv_Linksverkehr" 16 "STP_Verfuegbar" ;
VAL_ 768 STA_Primaeranz 0 "keine_Anzeige" 1 "STA_standby" 2 "STA_aktiv" 3 "STA_Warnung" ;
VAL_ 768 ACC_Regelgeschw 1023 "keine_Anzeige" ;
VAL_ 768 ACC_Einheit_maxSetzgeschw 0 "kmh" 1 "mph" ;
VAL_ 768 ACC_maxSetzgeschw 511 "Init_Neutralwert" ;
VAL_ 768 ACC_minRegelgeschw 255 "keine_Anzeige" ;
VAL_ 768 ACC_maxRegelgeschw 255 "keine_Anzeige" ;
VAL_ 768 ACC_Tempolimitassistent_02 0 "keine_Anzeige" 1 "Tempolimit" 2 "Gefaelle" 3 "Steigung" 4 "Kuppe" 5 "Ortsanfang" 6 "Ampel" 7 "Bahnuebergang" ;
VAL_ 768 ACC_Tempolimit_Einheit 0 "kmh_init" 1 "mph" ;
VAL_ 768 ACC_Kurvenassistent 0 "keine_Anzeige" 1 "Kreuzung" 2 "Rechtskurve" 3 "Linkskurve" 4 "Kreisverkehr" 5 "Autobahnabfahrt" 6 "Stauende" 7 "Engstelle" ;
VAL_ 768 ACC_Typ_Tachokranz 0 "Tachokranz_lang" 1 "Tachokranz_kurz" ;
VAL_ 768 ACC_RUV 0 "keine_Anzeige" 1 "RUV_aktiv_Rechtsverkehr" 2 "RUV_aktiv_Linksverkehr" ;
VAL_ 768 ACC_Tachokranz 0 "Tachokranz_nicht_beleuchtet" 1 "Tachokranz_beleuchtet" ;
VAL_ 768 ACC_Typ_Tachokranz_unten 0 "LEDs_an" 1 "LEDs_aus" ;
VAL_ 768 ACC_ENG_Texte 0 "keine_Anzeige" 1 "keine_Laenderverfuegbarkeit" 2 "nicht_verfuegbar" 3 "Geschwindigkeitsgrenze" ;
VAL_ 768 ACC_Status_GRA_Modus 0 "GRA_Modus_nicht_verfuegbar" 1 "GRA_Modus_verfuegbar_nicht_aktiv" 2 "GRA_Modus_verfuegbar_aktiv" ;
VAL_ 768 ACA_Querfuehrung_Texte 0 "keine_Anzeige" 1 "nicht_verfuegbar" 2 "keine_Sensorsicht" 3 "Fahreruebernahme" ;
VAL_ 768 ACA_Hinweistexte 0 "keine_Anzeige" 1 "QF_eingeschaltet" 2 "QF_ausgeschaltet" ;
VAL_ 768 ACC_FoD_Status 0 "Init" 1 "Funktion_inaktiv" 2 "Funktion_aktiv" ;
VAL_ 768 ACC_Texte_Abstandswarner 0 "keine_Anzeige" 1 "Systemstoerung" 2 "keine_Sensorsicht" 3 "zurzeit_eingeschraenkt" ;
VAL_ 768 ACC_Vorz_Abstandswarner 0 "keine_Anzeige" 1 "kleiner" 2 "groesser" 3 "kleiner_Warnung" ;
VAL_ 768 ACC_Texte_Sekundaeranz 0 "keine_Anzeige" 1 "Zielfahrzeug_erkannt" 2 "Rechtskurve_voraus" 3 "Linkskurve_voraus" 4 "Tempolimit_voraus" 5 "Sensorsicht" 6 "Anfahrbereit" 7 "Tempolimit_erkannt" 8 "Kreuzung_voraus" 9 "Kreisverkehr_voraus" 10 "Autobahnabfahrt_voraus" 11 "Stauende_voraus" 12 "Gefaelle_voraus" 13 "Hindernis_erkannt" 14 "TA_Hindernis_erkannt" 15 "TA_Anfahrbereit" ;
VAL_ 768 ACC_Status_Anzeige 0 "ACC_GRA_Hauptschalter_aus" 1 "ACC_in_Init_nicht_bei_GRA" 2 "ACC_GRA_passiv" 3 "ACC_GRA_aktiv" 4 "ACC_GRA_im_Hintergrund_uebertreten" 5 "ACC_GRA_Abschaltreaktion" 6 "ACC_reversibel_aus_nicht_bei_GRA" 7 "ACC_GRA_irreversibel_aus" ;
VAL_ 768 ACC_Akustik_03 0 "keine_Akustik" 1 "niederpriore_Akustik" 2 "mittelpriore_Akustik" 3 "hochpriore_Akustik" 4 "hochpriore_Dauerakustik" 5 "hochpriore_Dauerakustik_02" ;
VAL_ 768 ACC_Geschw_Zielfahrzeug 1023 "Neutralwert" ;
VAL_ 768 ACC_Texte_02 0 "keine_Anzeige" 1 "ACC_zurzeit_nicht_verfuegbar" 2 "ACC_Stoerung" 3 "ACC_keine_Sensorsicht" 4 "ACC_Steigung_zu_gross" 5 "ACC_nur_in_Fahrstufe_verfuegbar" 6 "ACC_Parkbremse_betaetigt" 7 "ACC_ESP_Eingriff" 8 "ACC_HDC_betaetigt" 9 "ACC_Geschwindigkeitsgrenze" 10 "ACC_Schalthebelposition" 11 "ACC_Drehzahl" 12 "ACC_Kupplung_betaetigt" 13 "ACC_ESC_aus" 14 "ACC_Bitte_uebernehmen" 15 "ACC_Aktivierverhinderung" 16 "ACC_eingeschraenkte_Funktion" 17 "ACC_Manoevrierassistent_aktiv" 18 "ACC_Parkassistent_aktiv" 19 "ACC_Stehendes_Objekt_voraus" 20 "ACC_aus" 21 "ACC_startet" 22 "ACC_Tuer_offen" 23 "ACC_Fahrer_Gurtschloss_offen" 25 "ACC_Abschaltung" 26 "ACC_Charisma_Modus_inkompatibel" 27 "ACC_verfuegbar" 28 "ACC_und_GRA_nicht_verfuegbar" 29 "Fehler_ACC_und_GRA" 30 "GRA_deaktiviert" 31 "keine_Abstandsregelung" 32 "GRA_zurzeit_nicht_verfuegbar" 33 "Fehler_GRA" 34 "ACC_nicht_ueber_FOD_freigeschalt" 35 "Fahrersitz_nicht_belegt" ;
VAL_ 768 ACC_STA_Text 0 "ACC_Text" 1 "ACC_STA_Text" ;
VAL_ 768 ACC_Status_Stauende 0 "deaktiviert" 1 "aktiviert" ;
VAL_ 768 STA_Texte 0 "keine_Anzeige" 1 "STA_nicht_verfuegbar" 2 "STA_Fahreruebernahme" 3 "STA_Constant_brake_mode" 4 "STA_Gurtschloss_nicht_gesteckt" 5 "STA_Fahrzeugeschw_zu_hoch" 6 "STA_Freifahrt" 7 "STA_Systemgrenze" ;
VAL_ 768 AbstWarn_LRR_FAS_Fkt_Status 0 "Init" 1 "Funktion_Ist_Ein" 2 "Funktion_Ist_Aus" 3 "Fehler" ;
VAL_ 768 STA_Zusatzanz 0 "keine_Anzeige" 1 "STA_verfuegbar" 2 "STA_aktiv" 3 "STA_Warnung" ;
VAL_ 768 FAS_Licht_Anf 0 "keine_Anforderung" 1 "Anforderung" ;
VAL_ 768 ACC_Zeitluecke_Abstandswarner 61 "Freifahrt" 62 "nicht_definiert" 63 "keine_Anzeige" ;
VAL_ 768 ACC_Abstand_Abstandswarner 509 "Freifahrt" 510 "nicht_definiert" 511 "keine_Anzeige" ;
VAL_ 768 ACC_Einheit_Abstandswarner 0 "Meter" 1 "Yard" ;
VAL_ 768 ACC_Texte_Sekundaeranz_03 0 "Keine_Anzeige" 1 "Kurve_voraus" 2 "Tempolimit_erkannt" 3 "Tempolimit_voraus" 4 "Kreuzung_voraus" 5 "Kreisverkehr_voraus" 6 "Stauende_voraus" 7 "Anfahrbereit" 8 "Ampel_horizontal_voraus" 9 "Ampel_vertikal_voraus" 10 "Stoppschild_voraus" 11 "Ampel_horizontal_erkannt" 12 "Ampel_vertikal_erkannt" 13 "Vorfahrt_beachten_voraus" 14 "Bumper_voraus" 15 "Kuppe_voraus" 16 "Hindernis_erkannt" 17 "TA_Anfahrbereit" 18 "TA_Hindernis_erkannt" 19 "Rechtskurve_voraus" 20 "Linkskurve_voraus" ;
VAL_ 768 ACC_Modus_Pop_Up 0 "keine_Anzeige" 1 "ACC_ausgewaehlt" 2 "GRA_ausgewaehlt" ;
VAL_ 768 ACC_Statusicon 0 "ACC_GRA_deaktiviert" 1 "ACC_init" 2 "ACC_passiv_FreeMode" 3 "ACC_passiv_FollowMode" 4 "ACC_aktiv_FreeMode" 5 "ACC_aktiv_FollowMode" 6 "ACC_override_FreeMode" 7 "ACC_override_FollowMode" 8 "ACC_reversibler_Fehler" 9 "ACC_irreversibler_Fehler" 10 "GRA_Modus_passiv" 11 "GRA_Modus_aktiv" 12 "GRA_override" 13 "GRA_reversibler_Fehler" 14 "GRA_irreversibler_Fehler" 15 "GRA_Init" ;
VAL_ 768 ACC_Anzeige_Objektregelung 0 "Keine_Anzeige" 1 "Linkes_Nebenspurobjekt" 2 "Rechtes_Nebenspurobjekt" 3 "Direktes_Zielobjekt" 4 "Tempolimit" 5 "Kurve" 6 "links_Kurve" 7 "rechts_Kurve" 8 "Kreuzung" 9 "Kreisverkehr" 10 "Autobahnabfahrt_auffahrt" 11 "Stauende" 12 "Engstelle" 13 "Gefaelle" 14 "Steigung" 15 "Kuppe_Bumper" 16 "Ampel_horizontal" 17 "Ampel_vertikal" 18 "Bahnuebergang" 19 "praediktive_Regelung_aktiv" ;
VAL_ 768 ACC_Typ_LNS 0 "invalid" 1 "Fussgaenger" 2 "LKW" 3 "PKW" 4 "Motorrad" 5 "Radfahrer" ;
VAL_ 768 ACC_Typ_RNS 0 "invalid" 1 "Fussgaenger" 2 "LKW" 3 "PKW" 4 "Motorrad" 5 "Radfahrer" ;
VAL_ 768 ACC_Typ_WZO 0 "invalid" 1 "Fussgaenger" 2 "LKW" 3 "PKW" 4 "Motorrad" 5 "Radfahrer" ;
VAL_ 768 ACC_Abstand_WZO 0 "keine_Anzeige" ;
VAL_ 768 ACC_Abstand_RNS 0 "keine_Anzeige" ;
VAL_ 768 ACC_Abstand_LNS 0 "keine_Anzeige" ;
VAL_ 768 ACC_Texte_03 0 "keine_Anzeige" 1 "ACC_nicht_ueber_FOD_freigeschalt" 2 "ACC_auswaehlen" 3 "ACC_verfuegbar" 4 "ACC_startet" 5 "GRA_startet" 6 "Hauptschalter_betaetigen" 7 "ACC_Stoerung" 8 "ACC_und_GRA_Stoerung" 9 "ACC_nicht_verfuegbar" 10 "ACC_und_GRA_nicht_verfuegbar" 11 "ACC_na_keine_Sensorsicht" 12 "ACC_na_Bremse_betaetigen" 13 "ACC_na_Steigung_zu_gross" 14 "ACC_na_Gefaelle_zu_gross" 15 "ACC_na_Parkbremse_betaetigt" 16 "GRA_na_Parkbremse_betaetigt" 17 "ACC_na_Bremse_betaetigt" 18 "GRA_na_Bremse_betaetigt" 19 "ACC_na_Fahrer_abwesend" 20 "ACC_na_Frontklappe_offen" 21 "GRA_na_Frontklappe_offen" 22 "ACC_na_Tuer_offen" 23 "GRA_na_Tuer_offen" 24 "ACC_na_WBA_aktiv" 25 "GRA_na_WBA_aktiv" 26 "ACC_na_Parkassistent_aktiv" 27 "GRA_na_Parkassistent_aktiv" 28 "ACC_na_HDC_betaetigt" 29 "GRA_na_HDC_betaetigt" 30 "ACC_na_ESC_Eingriff" 31 "GRA_na_ESC_Eingriff" 32 "ACC_na_nur_in_Fahrstufe_verfuegb" 33 "GRA_na_nur_in_Fahrstufe_verfuegb" 34 "ACC_na_Rueckwaertsgang_eingelegt" 35 "GRA_na_Rueckwaertsgang_eingelegt" 36 "ACC_na_rueckwaertsrollen" 37 "ACC_na_Fahrbereitschaft" 38 "ACC_na_Fzg_starten" 39 "GRA_na_Fzg_starten" 40 "ACC_na_Doppelbetaetigung" 41 "GRA_na_Doppelbetaetigung" 42 "ACC_na_Gangempfehlung" 43 "GRA_na_Gangempfehlung" 44 "ACC_na_zu_grosse_Verzoegerung" 45 "GRA_na_zu_grosse_Verzoegerung" 46 "GRA_na_Geschwindigkeitsgrenze" 47 "ACC_abg_Steigung_zu_gross" 48 "ACC_abg_Gefaelle_zu_gross" 49 "ACC_abg_Stillstand_verlassen" 50 "ACC_abg_keine_Sensorsicht" 51 "ACC_abg_nicht_fahrbereit" 52 "GRA_abg_nicht_fahrbereit" 53 "ACC_abg_Parkbremse_betaetigt" 54 "GRA_abg_Parkbremse_betaetigt" 55 "ACC_abg_ESC_Eingriff" 56 "GRA_abg_ESC_Eingriff" 57 "ACC_abg_ESC_aus" 58 "GRA_abg_ESC_aus" 59 "ACC_abg_Rueckwaertsgang_eingeleg" 60 "GRA_abg_Rueckwaertsgang_eingeleg" 61 "ACC_abg_nur_in_Fahrstufe_verfueg" 62 "GRA_abg_nur_in_Fahrstufe_verfueg" 63 "ACC_abg_Fahrer_abwesend" 64 "GRA_abg_Fahrer_abwesend" 65 "ACC_abg_Frontklappe_offen" 66 "GRA_abg_Frontklappe_offen" 67 "ACC_abg_Tuer_offen" 68 "GRA_abg_Tuer_offen" 69 "ACC_abg_WBA_aktiv" 70 "GRA_abg_WBA_aktiv" 71 "ACC_abg_Gangempfehlung" 72 "GRA_abg_Gangempfehlung" 73 "ACC_aus" 74 "GRA_aus" 75 "GRA_abg_Geschwindigkeitsgrenze" 76 "keine_Abstandsregelung" 77 "TA_startet" 78 "TA_na_Bremse_betaetigen" 79 "TA_na_Steigung_zu_gross" 80 "TA_na_Gefaelle_zu_gross" 81 "TA_na_Parkbremse_betaetigt" 82 "TA_na_Bremse_betaetigt" 83 "TA_na_Fahrer_abwesend" 84 "TA_na_Frontklappe_offen" 85 "TA_na_Tuer_offen" 86 "TA_na_WBA_aktiv" 87 "TA_na_Parkassistent_aktiv" 88 "TA_na_HDC_betaetigt" 89 "TA_na_ESC_Eingriff" 90 "TA_na_nur_in_Fahrstufe_verfuegb" 91 "TA_na_Rueckwaertsgang_eingelegt" 92 "TA_na_rueckwaertsrollen" 93 "TA_na_Fahrbereitschaft" 94 "TA_na_Fzg_starten" 95 "TA_na_Doppelbetaetigung" 96 "TA_na_Gangempfehlung" 97 "TA_na_zu_grosse_Verzoegerung" 98 "TA_abg_Steigung_zu_gross" 99 "TA_abg_Gefaelle_zu_gross" 100 "TA_abg_Stillstand_verlassen" 101 "TA_abg_nicht_fahrbereit" 102 "TA_abg_Parkbremse_betaetigt" 103 "TA_abg_ESC_Eingriff" 104 "TA_abg_ESC_aus" 105 "TA_abg_Rueckwaertsgang_eingeleg" 106 "TA_abg_nur_in_Fahrstufe_verfueg" 107 "TA_abg_Fahrer_abwesend" 108 "TA_abg_Frontklappe_offen" 109 "TA_abg_Tuer_offen" 110 "TA_abg_WBA_aktiv" 111 "TA_abg_Gangempfehlung" 112 "TA_Hauptschalter_betaetigen" 113 "GRA_nicht_verfuegbar" 114 "GRA_Stoerung" 115 "ACC_na_zurzeit_nicht_aktivierbar" 116 "GRA_na_zurzeit_nicht_aktivierbar" 117 "TA_na_zurzeit_nicht_aktivierbar" 118 "ACC_abg_Geschwindigkeitsgrenze" 119 "TA_abg_Geschwindigkeitsgrenze" 120 "ACC_abg_HDC_Eingriff" 121 "GRA_abg_HDC_Eingriff" 122 "TA_abg_HDC_Eingriff" 123 "ACC_abg_Kupplung_betaetigt" 124 "GRA_abg_Kupplung_betaetigt" 125 "TA_abg_Kupplung_betaetigt" 126 "ACC_na_Geschwindigkeitsgrenze" 127 "TA_na_Geschwindigkeitsgrenze" ;
VAL_ 768 ACC_iBoost_Anzeige 0 "keine_Anzeige" 1 "iBoost_aktiv_Freifahrt" 2 "iBoost_aktiv_Folgefahrt_verz" 3 "iBoost_aktiv_Folgefahrt_beschl" ;
VAL_ 768 ACC_Texte_Sekundaeranz_02 0 "Keine_Anzeige" 1 "Zielfahrzeug_erkannt" 2 "Sensorsicht" 3 "Anfahrbereit" 4 "Tempolimit_voraus" 5 "Tempolimit_erkannt" 6 "Kurve_voraus" 7 "rechts_Kurve_voraus" 8 "links_Kurve_voraus" 9 "Kreuzung_voraus" 10 "Kreisverkehr_voraus" 11 "Autobahnabfahrt_auffahrt_voraus" 12 "Stauende_voraus" 13 "Engstelle_voraus" 14 "Gefaelle_voraus" 15 "Steigung_voraus" 16 "Kuppe_Bumper_voraus" 17 "Ampel_horizontal_voraus" 18 "Ampel_vertikal_voraus" 19 "Bahnuebergang_voraus" ;
VAL_ 768 ACC_Sollabstand_1 0 "keine_Anzeige" ;
VAL_ 768 ACC_Sollabstand_2 0 "keine_Anzeige" ;
VAL_ 768 ACC_Sollabstand_3 0 "keine_Anzeige" ;
VAL_ 768 ACC_Sollabstand_4 0 "keine_Anzeige" ;
VAL_ 768 ACC_Sollabstand_5 0 "keine_Anzeige" ;
VAL_ 859 ACC_Obj_01_ID 0 "kein_Objekt_enthalten" 255 "Init" ;
VAL_ 859 ACC_Obj_01_ax_StdA 63 "Init" ;
VAL_ 859 ACC_Obj_01_ax_v 255 "Init" ;
VAL_ 859 ACC_Obj_01_dx_StdA 127 "Init" ;
VAL_ 859 ACC_Obj_01_dx_v 4095 "Init" ;
VAL_ 859 ACC_Obj_01_dy_StdA 127 "Init" ;
VAL_ 859 ACC_Obj_01_dy_v 2047 "Init" ;
VAL_ 859 ACC_Obj_01_vx_StdA 31 "Init" ;
VAL_ 859 ACC_Obj_01_vx_v 1023 "Init" ;
VAL_ 859 ACC_Obj_01_Bew_Zustand 0 "Init" 1 "fahrend" 2 "angehalten" 3 "stehend" ;
VAL_ 859 ACC_Obj_01_Fusion_ID_VD 0 "kein_Objekt_fusioniert" 0 "Init" ;
VAL_ 859 ACC_Obj_01_Fusion_ID_FER_VR 0 "kein_Objekt_fusioniert" 255 "Init" ;
VAL_ 859 ACC_Obj_01_Fusion_ID_FER_VL 0 "kein_Objekt_fusioniert" 255 "Init" ;
VAL_ 859 ACC_Obj_01_Alter 4095 "Init" ;
VAL_ 859 ACC_Obj_01_vxAbs_v 4095 "Init" ;
VAL_ 859 ACC_Obj_01_vyAbs_v 4095 "Init" ;
VAL_ 859 ACC_Obj_01_Bezugspunkt 0 "unbestimmt" 1 "vorne_links" 2 "vorne_Mitte" 3 "vorne_rechts" 4 "rechts_Mitte" 5 "hinten_rechts" 6 "hinten_Mitte" 7 "hinten_links" 8 "links_Mitte" 9 "Objektmitte" 15 "Init" ;
VAL_ 859 ACC_Obj_01_Breite 127 "Init" ;
VAL_ 859 ACC_Obj_01_SDFInfo_FER_VL 0 "nicht_bestaetigt" 1 "bestaetigt" ;
VAL_ 859 ACC_Obj_01_BreiteStdA 127 "Init" ;
VAL_ 859 ACC_Obj_01_SDFInfo_FER_VR 0 "nicht_bestaetigt" 1 "bestaetigt" ;
VAL_ 859 ACC_Obj_01_Historie 0 "Erstmalige_Ausgabe_auf_dem_Bus" 1 "Obj_wurde_bereits_ausgegeben" ;
VAL_ 859 ACC_Obj_01_SDFInfo_FR 0 "nicht_bestaetigt" 1 "bestaetigt" ;
VAL_ 859 ACC_Obj_01_SDFInfo_Kamera 0 "nicht_bestaetigt" 1 "bestaetigt" ;
VAL_ 859 ACC_Obj_01_vy_StdA 31 "Init" ;
VAL_ 859 ACC_Obj_01_dz_v 511 "Init" ;
VAL_ 859 ACC_Obj_01_dz_StdA 127 "Init" ;
VAL_ 859 ACC_Obj_01_Laenge 511 "Init" ;
VAL_ 859 ACC_Obj_01_LaengeStdA 127 "Init" ;
VAL_ 859 ACC_Obj_01_GierWnkl 511 "Init" ;
VAL_ 859 ACC_Obj_01_ExistenzMass 127 "Init" ;
VAL_ 859 ACC_Obj_01_axAbs_v 255 "Init" ;
VAL_ 859 ACC_Obj_01_ay_v 255 "Init" ;
VAL_ 859 ACC_Obj_01_vy_v 255 "Init" ;
VAL_ 859 ACC_Obj_01_Klasse 0 "unbekannt" 1 "ueberfahrbar" 2 "unterfahrbar" 3 "Fussgaenger" 4 "Fussgaengergruppe" 5 "Fahrrad" 6 "Motorrad" 7 "PKW" 8 "Van" 9 "LKW" 10 "Randbebauung" 11 "Tier" 12 "Retroreflektor" 15 "Init" ;
VAL_ 859 ACC_Obj_01_KlassePlausib 15 "Init" ;
VAL_ 859 ACC_Obj_01_Gemessen 0 "Objekt_praediziert" 1 "Objekt_gemessen" 2 "Objekt_per_Feature_Tracking" 3 "Naheinscherer_oder_Ueberholer" ;
VAL_ 859 ACC_Obj_01_Hoehe 63 "Init" ;
VAL_ 859 ACC_Obj_01_HoeheStdA 63 "Init" ;
VAL_ 859 ACC_Obj_01_vxAbs_StdA 63 "Init" ;
VAL_ 859 ACC_Obj_01_vyAbs_StdA 63 "Init" ;
VAL_ 859 ACC_Obj_01_axAbs_StdA 63 "Init" ;
VAL_ 859 ACC_Obj_01_ay_StdA 63 "Init" ;
VAL_ 859 ACC_Obj_01_GierWnklStdA 63 "Init" ;
VAL_ 859 ACC_Obj_01_Anzeige_Rel 0 "Keine_Anzeige" 1 "passive_Darstellung" 2 "geregelte_Darstellung" 3 "bewarnte_Darstellung" ;
VAL_ 859 ACC_Obj_01_LaengsRegelung 0 "Objektregelung_inaktiv" 1 "Objektregelung_aktiv" ;
VAL_ 2331595990 ACC_Obj_02_ID 0 "kein_Objekt_enthalten" 255 "Init" ;
VAL_ 2331595990 ACC_Obj_02_ax_StdA 63 "Init" ;
VAL_ 2331595990 ACC_Obj_02_ax_v 255 "Init" ;
VAL_ 2331595990 ACC_Obj_02_dx_v 4095 "Init" ;
VAL_ 2331595990 ACC_Obj_02_dy_v 2047 "Init" ;
VAL_ 2331595990 ACC_Obj_02_vx_v 1023 "Init" ;
VAL_ 2331595990 ACC_Obj_02_Fusion_ID_VD 0 "kein_Objekt_fusioniert" 0 "Init" ;
VAL_ 2331595990 ACC_Obj_02_Fusion_ID_FER_VR 0 "kein_Objekt_fusioniert" 255 "Init" ;
VAL_ 2331595990 ACC_Obj_02_Fusion_ID_FER_VL 0 "kein_Objekt_fusioniert" 255 "Init" ;
VAL_ 2331595990 ACC_Obj_02_Alter 4095 "Init" ;
VAL_ 2331595990 ACC_Obj_02_vxAbs_v 4095 "Init" ;
VAL_ 2331595990 ACC_Obj_02_vyAbs_v 4095 "Init" ;
VAL_ 2331595990 ACC_Obj_02_Bezugspunkt 0 "unbestimmt" 1 "vorne_links" 2 "vorne_Mitte" 3 "vorne_rechts" 4 "rechts_Mitte" 5 "hinten_rechts" 6 "hinten_Mitte" 7 "hinten_links" 8 "links_Mitte" 9 "Objektmitte" 15 "Init" ;
VAL_ 2331595990 ACC_Obj_02_Breite 127 "Init" ;
VAL_ 2331595990 ACC_Obj_02_SDFInfo_FER_VL 0 "nicht_bestaetigt" 1 "bestaetigt" ;
VAL_ 2331595990 ACC_Obj_02_BreiteStdA 127 "Init" ;
VAL_ 2331595990 ACC_Obj_02_SDFInfo_FER_VR 0 "nicht_bestaetigt" 1 "bestaetigt" ;
VAL_ 2331595990 ACC_Obj_02_Historie 0 "Erstmalige_Ausgabe_auf_dem_Bus" 1 "Obj_wurde_bereits_ausgegeben" ;
VAL_ 2331595990 ACC_Obj_02_SDFInfo_FR 0 "nicht_bestaetigt" 1 "bestaetigt" ;
VAL_ 2331595990 ACC_Obj_02_dz_v 511 "Init" ;
VAL_ 2331595990 ACC_Obj_02_Laenge 511 "Init" ;
VAL_ 2331595990 ACC_Obj_02_LaengeStdA 127 "Init" ;
VAL_ 2331595990 ACC_Obj_02_GierWnkl 511 "Init" ;
VAL_ 2331595990 ACC_Obj_02_ExistenzMass 127 "Init" ;
VAL_ 2331595990 ACC_Obj_02_ay_v 255 "Init" ;
VAL_ 2331595990 ACC_Obj_02_vy_v 255 "Init" ;
VAL_ 2331595990 ACC_Obj_02_Gemessen 0 "Objekt_praediziert" 1 "Objekt_gemessen" 2 "Objekt_per_Feature_Tracking" 3 "Naheinscherer_oder_Ueberholer" ;
VAL_ 2331595990 ACC_Obj_02_Hoehe 63 "Init" ;
VAL_ 2331595990 ACC_Obj_02_HoeheStdA 63 "Init" ;
VAL_ 2331595990 ACC_Obj_02_vxAbs_StdA 63 "Init" ;
VAL_ 2331595990 ACC_Obj_02_vyAbs_StdA 63 "Init" ;
VAL_ 2331595990 ACC_Obj_02_ay_StdA 63 "Init" ;
VAL_ 2331595990 ACC_Obj_02_GierWnklStdA 63 "Init" ;
VAL_ 2331595990 ACC_Obj_02_Anzeige_Rel 0 "Keine_Anzeige" 1 "passive_Darstellung" 2 "geregelte_Darstellung" 3 "bewarnte_Darstellung" ;
VAL_ 2331595990 ACC_Obj_02_LaengsRegelung 0 "Objektregelung_inaktiv" 1 "Objektregelung_aktiv" ;
VAL_ 2331596021 ACC_Obj_05_ID 0 "kein_Objekt_enthalten" 255 "Init" ;
VAL_ 2331596021 ACC_Obj_05_dx_v 4095 "Init" ;
VAL_ 2331596021 ACC_Obj_05_dy_v 2047 "Init" ;
VAL_ 2331596021 ACC_Obj_05_vx_StdA 31 "Init" ;
VAL_ 2331596021 ACC_Obj_05_vx_v 1023 "Init" ;
VAL_ 2331596021 ACC_Obj_05_Bew_Zustand 0 "Init" 1 "fahrend" 2 "angehalten" 3 "stehend" ;
VAL_ 2331596021 ACC_Obj_05_SDFInfo_FER_VL 0 "nicht_bestaetigt" 1 "bestaetigt" ;
VAL_ 2331596021 ACC_Obj_05_SDFInfo_FER_VR 0 "nicht_bestaetigt" 1 "bestaetigt" ;
VAL_ 2331596021 ACC_Obj_05_Historie 0 "Erstmalige_Ausgabe_auf_dem_Bus" 1 "Obj_wurde_bereits_ausgegeben" ;
VAL_ 2331596021 ACC_Obj_05_SDFInfo_FR 0 "nicht_bestaetigt" 1 "bestaetigt" ;
VAL_ 2331596021 ACC_Obj_05_SDFInfo_Kamera 0 "nicht_bestaetigt" 1 "bestaetigt" ;
VAL_ 2331596021 ACC_Obj_05_vy_StdA 31 "Init" ;
VAL_ 2331596021 ACC_Obj_05_vy_v 255 "Init" ;
VAL_ 2331596021 ACC_Obj_05_Klasse 0 "unbekannt" 1 "ueberfahrbar" 2 "unterfahrbar" 3 "Fussgaenger" 4 "Fussgaengergruppe" 5 "Fahrrad" 6 "Motorrad" 7 "PKW" 8 "Van" 9 "LKW" 10 "Randbebauung" 11 "Tier" 12 "Retroreflektor" 15 "Init" ;
VAL_ 2331596021 ACC_Obj_05_KlassePlausib 15 "Init" ;
VAL_ 2331596021 ACC_Obj_05_Gemessen 0 "Objekt_praediziert" 1 "Objekt_gemessen" 2 "Objekt_per_Feature_Tracking" 3 "Naheinscherer_oder_Ueberholer" ;
VAL_ 2331596021 ACC_Obj_05_Anzeige_Rel 0 "Keine_Anzeige" 1 "passive_Darstellung" 2 "geregelte_Darstellung" 3 "bewarnte_Darstellung" ;
VAL_ 2527679923 ADA_DistractionLevel 125 "Ausgeschaltet" 126 "Init" 127 "Fehler" ;
VAL_ 2527679923 ADA_DrowsinessLevel 125 "Ausgeschaltet" 126 "Init" 127 "Fehler" ;
VAL_ 2527679923 ADA_AttentionLevel 126 "Init" 127 "Fehler" ;
VAL_ 2527679923 ADA_DriverIsOperating 0 "Init" 1 "nicht_aktiv" 2 "aktiv" 3 "Fehler" ;
VAL_ 2527679923 ADA_HMI_Ablenkung_Deaktivierung 0 "keine_Meldung" 1 "Ablenkung_deaktiviert" ;
VAL_ 2527679923 ADA_HMI_Ablenkung_Fehler_Popup 0 "keine_Meldung" 1 "Ablenkung_eingesch_verfuegbar" 2 "Ablenkung_nicht_verfuegbar" 3 "Kamera_ausgeschaltet" ;
VAL_ 2527679923 ADA_HMI_Ablenkung_Meldeakustik 0 "Meldeakustik" 1 "keine_Meldeakustik" ;
VAL_ 2527679923 ADA_HMI_Ablenkung_Meldung 0 "keine_Meldung" 1 "Meldung1" 2 "Meldung2" 3 "Meldung3" ;
VAL_ 2527679923 ADA_HMI_Fahrzeit_seit_Pause 1023 "keine_Ausgabe" ;
VAL_ 2527679923 ADA_HMI_Muedigkeit_Deaktivierung 0 "keine_Meldung" 1 "Muedigkeit_deaktiviert" ;
VAL_ 2527679923 ADA_HMI_Muedigkeit_Fehler_Popup 0 "keine_Meldung" 1 "Muedigkeit_eingesch_verfuegbar" 2 "Muedigkeit_nicht_verfuegbar" 3 "Kamera_ausgeschaltet" ;
VAL_ 2527679923 ADA_HMI_Muedigkeit_Meldeakustik 0 "Meldeakustik" 1 "keine_Meldeakustik" ;
VAL_ 2527679923 ADA_HMI_Muedigkeit_Meldung 0 "keine_Meldung" 1 "Meldung1" 2 "Meldung2" 3 "Meldung3" 4 "Meldung_Pausenempfehlung" 5 "reserviert" 6 "reserviert" 7 "reserviert" ;
VAL_ 2527679923 ADA_HMI_Muedigkeit_Event_Meldung 0 "keine_Meldung" 1 "Sekundenschlaf" 2 "Augen_geschlossen" 3 "Gaehnen" ;
VAL_ 2527679923 ADA_DrowsinessSystemState 0 "init" 1 "off" 2 "inactive" 3 "active" 4 "restrictedMode" 5 "reversibleOff" 6 "irreversibleOff" 7 "error" ;
VAL_ 2527679923 ADA_Microsleep 0 "No_microsleep_detected" 1 "Microsleep_imminent" 2 "Microsleep_detected" 6 "Init" 7 "Error" ;
VAL_ 2527679923 ADA_TriggerEmergencyAssist 0 "Aktiver_Fahrer" 1 "Blickabwendung" 2 "Sekundenschlaf" 3 "Schlaf" 6 "Init" 7 "Fehler" ;
VAL_ 2527679923 ADA_Upcoming_Microsleep 0 "no_upcoming_microsleep" 1 "upcoming_microsleep" ;
VAL_ 1660 AGA_Texte 0 "keine_Anzeige" 1 "Aussensound_defekt" 2 "Aussensound_deaktiviert" 3 "Aussensound_deaktiviert_reduziertWarn" 4 "Aussensound_aktiviert" 5 "Aussensound_deaktiviert_KL15" ;
VAL_ 1660 E_Sound_verbaut 0 "nicht_verbaut" 1 "verbaut" ;
VAL_ 1660 AGA_Charisma_FahrPr 0 "keine_Funktion" 1 "Programm_1" 2 "Programm_2" 3 "Programm_3" 4 "Programm_4" 5 "Programm_5" 6 "Programm_6" 7 "Programm_7" 8 "Programm_8" 9 "Programm_9" 10 "Programm_10" 11 "Programm_11" 12 "Programm_12" 13 "Programm_13" 14 "Programm_14" 15 "Programm_15" ;
VAL_ 1660 AGA_Charisma_Status 0 "Init" 1 "verfuegbar" 2 "nicht_verfuegbar" 3 "asynchron_durch_Fahrerwunsch" ;
VAL_ 1660 AGA_ohne_Funktion 0 "kein_Fehler" 1 "Fehler" ;
VAL_ 1660 AGA_Verstaerker_Mute 0 "Mute" 1 "Kein_Mute" ;
VAL_ 64 AB_RGS_Anst 4 "aktiv_Niveau_1" 5 "aktiv_Niveau_2" 6 "aktiv_Niveau_3" 7 "aktiv_Niveau_4" 8 "deaktiviert" ;
VAL_ 64 AB_Front_Crash 0 "kein_Front_Crash" 1 "Front_Crash" ;
VAL_ 64 AB_Heck_Crash 0 "kein_Heck_Crash" 1 "Heck_Crash" ;
VAL_ 64 AB_SF_Crash 0 "kein_Seiten_Crash_Fahrer" 1 "Seiten_Crash_Fahrer" ;
VAL_ 64 AB_SB_Crash 0 "kein_Seiten_Crash_Beifahrer" 1 "Seiten_Crash_Beifahrer" ;
VAL_ 64 AB_Rollover_Crash 0 "kein_Rollover" 1 "Rollover" ;
VAL_ 64 AB_Crash_Int 0 "kein_Crash" 1 "Crash_Intensitaet_1" 2 "Crash_Intensitaet_2_(nur_Stellgliedtest_MLB_B8)" 3 "Crash_Intensitaet_2_(nur_D4_C7_Colorado_NF_PAG__Crash_im_MLB_B8)" 4 "Crash_Intensitaet_3_(alt_VW/AUDI__Stellgliedtest_MLB_B8)" 5 "Crash_Intensitaet_3_(alt_PAG)" 7 "Crash_Intensitaet_3" ;
VAL_ 64 AB_Lampe 0 "Aus" 1 "Ein" ;
VAL_ 64 AB_Deaktiviert 0 "aktiv" 1 "deaktiviert" ;
VAL_ 64 AB_VB_deaktiviert 0 "Beifahrerairbag_aktiv" 1 "Beifahrerairbag_deaktiviert" ;
VAL_ 64 AB_Systemfehler 0 "kein_Fehler" 1 "Airbag_Systemfehler" ;
VAL_ 64 AB_Diagnose 0 "nicht_in_Diagnose" 1 "in_Diagnose" ;
VAL_ 64 AB_Stellgliedtest 0 "nicht_im_Stellgliedtest" 1 "Airbag_im_Stellgliedtest" ;
VAL_ 64 AB_Erh_Auf_VB 0 "keine_Anzeige" 1 "Beifahrerairbag_deaktiviert" 2 "Beifahrerairbag_aktiviert" 3 "nicht_definiert" ;
VAL_ 64 AB_Gurtwarn_VF 0 "keine_Warnung" 1 "Gurtwarnung_ausloesen" ;
VAL_ 64 AB_Gurtwarn_VB 0 "keine_Warnung" 1 "Gurtwarnung_ausloesen" ;
VAL_ 64 AB_Anzeige_Fussg 0 "keine_FSG_Aktion_ausgeloest" 1 "Motorhaube_offen" 2 "Systemfehler" ;
VAL_ 64 AB_Texte_AKS 0 "keine_AKS_Ausloesung" 1 "AKS_ausgeloest" 2 "AKS_Systemfehler" ;
VAL_ 64 AB_PAO_Leuchte_Anf 0 "Leuchte_ausschalten" 1 "Leuchte_einschalten" ;
VAL_ 64 AB_MKB_gueltig 0 "Multikollisionsbremsung_nicht_freigeschaltet" 1 "Multikollisionsbremsung_freigeschaltet" ;
VAL_ 64 AB_MKB_Anforderung 0 "Multikollisionsbremsung_nicht_angefordert" 1 "Multikollisionsbremsung_angefordert" ;
VAL_ 64 AB_Versorgungsspannung 0 "plausibel" 1 "unplausibel" ;
VAL_ 64 AB_Deaktivierung_HV 0 "keine_Deaktivierung" 1 "Deaktivierung_1" 2 "Deaktivierung_2" 3 "Deaktivierung_3" 4 "Deaktivierung_4" 5 "Deaktivierung_5" 6 "Deaktivierung_6" 7 "Fehler" ;
VAL_ 64 AB_EDR_Trigger 0 "No_Event" 1 "Start_Event" 2 "NonDeployment_Event" 3 "Deployment_Event" ;
VAL_ 64 AB_Belegung_VF 0 "nicht_verfuegbar" 1 "Fehler" 2 "nicht_belegt" 3 "belegt" ;
VAL_ 64 AB_Gurtschloss_FA_ext 0 "nicht_verbaut" 1 "reserviert" 2 "nicht_gesteckt" 3 "gesteckt" 4 "dauerhaft_nicht_gesteckt" 5 "dauerhaft_gesteckt" 6 "Init" 7 "Fehler" ;
VAL_ 64 AB_Gurtschloss_FA_ext_aktiv 0 "inaktiv" 1 "aktiv" ;
VAL_ 64 AB_eCS_Error 0 "keine_Anzeige" 1 "Anzeige_anfordern" ;
VAL_ 64 ASM_Masterzeit_02 255 "Init" ;
VAL_ 1312 LoGeWa_Event_Kombiwarnung 0 "Init" 1 "Unfall" 2 "Traktionsverlust" 3 "Panne" 4 "Sichtbehinderung" 5 "Aquaplaning" ;
VAL_ 1312 AB_Anforderung_eCall 0 "keine_Anforderung" 1 "Anforderung" ;
VAL_ 1312 AB_Anprall_Seite_Beifahrer 0 "kein_Anprall" 1 "Anprall_erkannt" ;
VAL_ 1312 AB_Anprall_Rollover 0 "kein_Anprall" 1 "Anprall_erkannt" ;
VAL_ 1312 AB_Anprall_FGS 0 "kein_Anprall" 1 "Anprall_erkannt" ;
VAL_ 1312 AB_Anprall_Front_Beifahrer 0 "kein_Anprall" 1 "Anprall_erkannt" ;
VAL_ 1312 AB_Anprall_Front_Fahrer 0 "kein_Anprall" 1 "Anprall_erkannt" ;
VAL_ 1312 AB_Anprall_Heck_Beifahrer 0 "kein_Anprall" 1 "Anprall_erkannt" ;
VAL_ 1312 AB_Anprall_Heck_Fahrer 0 "kein_Anprall" 1 "Anprall_erkannt" ;
VAL_ 1312 AB_Wickelklappung_Reihe2_MI 0 "nicht_verbaut" 1 "nicht_verfuegbar__Fehler_oder_Init" 2 "nicht_verriegelt" 3 "verriegelt" ;
VAL_ 1312 AB_Belegung_VB 0 "nicht_verfuegbar" 1 "Fehler" 2 "nicht_belegt" 3 "belegt" ;
VAL_ 1312 AB_Abschaltanf_SIH_BF 0 "Normalbetrieb" 1 "Abschaltung_angefordert" ;
VAL_ 1312 AB_Anprall_Seite_Fahrer 0 "kein_Anprall" 1 "Anprall_erkannt" ;
VAL_ 1312 SC_PAO_Schriftzug_Anf 0 "LED aus" 1 "LED an" 2 "LED blinken" 3 "reserviert" ;
VAL_ 1312 SC_PAO_ON_Anf 0 "LED aus" 1 "LED an" 2 "LED blinken" 3 "reserviert" ;
VAL_ 1312 SC_PAO_OFF_Anf 0 "LED aus" 1 "LED an" 2 "LED blinken" 3 "reserviert" ;
VAL_ 1312 AB_Crashschwere 0 "kein_Ereignis" 1 "Crashschwere_1" 2 "Crashschwere_2" 3 "Crashschwere_3" 4 "Crashschwere_4" 5 "Crashschwere_5" 6 "Crashschwere_2_bis_5" 7 "Fehler" ;
VAL_ 1312 AB_Anforderung_USM 0 "keine_Anforderung" 1 "Anforderung" ;
VAL_ 1312 AB_Gurtschloss_FA 0 "nicht_verbaut" 1 "nicht_verfügbar (Fehler oder Init)" 2 "nicht_gesteckt" 3 "gesteckt" ;
VAL_ 1312 AB_Gurtschloss_BF 0 "nicht_verbaut" 1 "nicht_verfügbar (Fehler oder Init)" 2 "nicht_gesteckt" 3 "gesteckt" ;
VAL_ 1312 AB_Gurtschloss_Reihe2_FA 0 "nicht_verbaut" 1 "nicht_verfügbar (Fehler oder Init)" 2 "nicht_gesteckt" 3 "gesteckt" ;
VAL_ 1312 AB_Gurtschloss_Reihe2_MI 0 "nicht_verbaut" 1 "nicht_verfügbar (Fehler oder Init)" 2 "nicht_gesteckt" 3 "gesteckt" ;
VAL_ 1312 AB_Gurtschloss_Reihe2_BF 0 "nicht_verbaut" 1 "nicht_verfügbar (Fehler oder Init)" 2 "nicht_gesteckt" 3 "gesteckt" ;
VAL_ 1312 AB_Gurtschloss_Reihe3_FA 0 "nicht_verbaut" 1 "nicht_verfügbar (Fehler oder Init)" 2 "nicht_gesteckt" 3 "gesteckt" ;
VAL_ 1312 AB_Gurtschloss_Reihe3_MI 0 "nicht_verbaut" 1 "nicht_verfügbar (Fehler oder Init)" 2 "nicht_gesteckt" 3 "gesteckt" ;
VAL_ 1312 AB_Gurtschloss_Reihe3_BF 0 "nicht_verbaut" 1 "nicht_verfügbar (Fehler oder Init)" 2 "nicht_gesteckt" 3 "gesteckt" ;
VAL_ 1312 AB_Sitzpos_Sens_FA 0 "nicht verfügbar" 1 "Fehler" 2 "Sitz nicht vorne" 3 "Sitz vorne" ;
VAL_ 1312 AB_Sitzpos_Sens_BF 0 "nicht verfügbar" 1 "Fehler" 2 "Sitz nicht vorne" 3 "Sitz vorne" ;
VAL_ 1312 AB_Wickelklappung_Reihe2_BF 0 "nicht_verbaut" 1 "nicht_verfuegbar__Fehler_oder_Init" 2 "nicht_verriegelt" 3 "verriegelt" ;
VAL_ 1312 AB_Wickelklappung_Reihe2_FA 0 "nicht_verbaut" 1 "nicht_verfuegbar__Fehler_oder_Init" 2 "nicht_verriegelt" 3 "verriegelt" ;
VAL_ 1349 AB_Anprall_Front 0 "kein_Anprall" 1 "Anprall_erkannt" ;
VAL_ 1349 AB_Anprall_Heck 0 "kein_Anprall" 1 "Anprall_erkannt" ;
VAL_ 1349 AB_Gurtwarn_Reihe4_FA 0 "nicht_verbaut" 1 "keine_Gurtwarnung_Sitz_leer" 2 "keine_Gurtwarnung_Sitz_belegt" 3 "Gurtwarnung_Sitz_belegt" ;
VAL_ 1349 AB_Gurtwarn_Reihe4_BF 0 "nicht_verbaut" 1 "keine_Gurtwarnung_Sitz_leer" 2 "keine_Gurtwarnung_Sitz_belegt" 3 "Gurtwarnung_Sitz_belegt" ;
VAL_ 1349 AB_Gurtwarn_Reihe4_MI 0 "nicht_verbaut" 1 "keine_Gurtwarnung_Sitz_leer" 2 "keine_Gurtwarnung_Sitz_belegt" 3 "Gurtwarnung_Sitz_belegt" ;
VAL_ 1349 AB_Gurtwarn_Reihe2_FA 0 "nicht_verbaut" 1 "keine_Gurtwarnung_Sitz_leer" 2 "keine_Gurtwarnung_Sitz_belegt" 3 "Gurtwarnung_Sitz_belegt" ;
VAL_ 1349 AB_Gurtwarn_Reihe2_BF 0 "nicht_verbaut" 1 "keine_Gurtwarnung_Sitz_leer" 2 "keine_Gurtwarnung_Sitz_belegt" 3 "Gurtwarnung_Sitz_belegt" ;
VAL_ 1349 AbstWarn_MV_FAS_Fkt_Status 0 "Init" 1 "Funktion_Ist_Ein" 2 "Funktion_Ist_Aus" 3 "Fehler" ;
VAL_ 1349 WarnBrems_Charisma_Status 0 "Init" 1 "verfügbar" 2 "nicht verfügbar" 3 "asynchron durch Fahrerwunsch" ;
VAL_ 1349 WarnBrems_Charisma_FahrPr 0 "keine_Funktion" 1 "Programm_1" 2 "Programm_2" 3 "Programm_3" 4 "Programm_4" 5 "Programm_5" 6 "Programm_6" 7 "Programm_7" 8 "Programm_8" 9 "Programm_9" 10 "Programm_10" 11 "Programm_11" 12 "Programm_12" 13 "Programm_13" 14 "Programm_14" 15 "Programm_15" ;
VAL_ 1349 AB_Gurtwarn_Reihe2_MI 0 "nicht_verbaut" 1 "keine_Gurtwarnung_Sitz_leer" 2 "keine_Gurtwarnung_Sitz_belegt" 3 "Gurtwarnung_Sitz_belegt" ;
VAL_ 1349 AB_Gurtwarn_Reihe3_FA 0 "nicht_verbaut" 1 "keine_Gurtwarnung_Sitz_leer" 2 "keine_Gurtwarnung_Sitz_belegt" 3 "Gurtwarnung_Sitz_belegt" ;
VAL_ 1349 AB_Gurtwarn_Reihe3_MI 0 "nicht_verbaut" 1 "keine_Gurtwarnung_Sitz_leer" 2 "keine_Gurtwarnung_Sitz_belegt" 3 "Gurtwarnung_Sitz_belegt" ;
VAL_ 1349 AB_Gurtwarn_Reihe3_BF 0 "nicht_verbaut" 1 "keine_Gurtwarnung_Sitz_leer" 2 "keine_Gurtwarnung_Sitz_belegt" 3 "Gurtwarnung_Sitz_belegt" ;
VAL_ 1349 LGI_FAS_Fkt_Status 0 "Init" 1 "Funktion_Ist_Ein" 2 "Funktion_Ist_Aus" 3 "Fehler" ;
VAL_ 1349 PreCrash_FAS_Fkt_Status 0 "Init" 1 "Funktion_Ist_Ein" 2 "Funktion_Ist_Aus" 3 "Fehler" ;
VAL_ 1349 AB_Belegung_VF_ext 0 "nicht_verbaut" 1 "reserviert" 2 "nicht_belegt" 3 "belegt" 4 "dauerhaft_nicht_belegt" 5 "dauerhaft_belegt" 6 "Init" 7 "Fehler" ;
VAL_ 1349 AB_SBR_hinten_verbau 0 "ohne_SBR_hinten" 1 "mit_SBR_hinten" 2 "nicht_definiert" 3 "Init" ;
VAL_ 1349 AB_Belegung_VF_ext_aktiv 0 "inaktiv" 1 "aktiv" ;
VAL_ 1349 AWV_Einstellung_System_ASG 0 "deaktiviert" 1 "aktiviert" ;
VAL_ 1349 AWV_Einstellung_Warnung_ASG 0 "Aus" 1 "Setting_2" 2 "Setting_3" 3 "Setting_4" 4 "Setting_5" 5 "Ein" ;
VAL_ 1349 SC_PreSense_Modus_Warnung_NV 0 "Aus" 1 "Setting_2" 2 "Setting_3" 3 "Setting_4" 4 "Setting_5" 5 "Ein" ;
VAL_ 1349 SC_PreSense_Modus_Warnung_MV 0 "Aus" 1 "Setting_2" 2 "Setting_3" 3 "Setting_4" 4 "Setting_5" 5 "Ein" ;
VAL_ 1349 SC_PreSense_Modus_System_MV 0 "deaktiviert" 1 "aktiviert" ;
VAL_ 1349 SC_PreSense_Modus_System_NV 0 "deaktiviert" 1 "aktiviert" ;
VAL_ 1349 SC_PreSense_Modus_System_KAS 0 "deaktiviert" 1 "aktiviert" ;
VAL_ 2527679722 AB_Gurtschloss_Reihe4_FA 0 "nicht_verbaut" 1 "nicht_verfügbar (Fehler oder Init)" 2 "nicht_gesteckt" 3 "gesteckt" ;
VAL_ 2527679722 AB_Gurtschloss_Reihe4_BF 0 "nicht_verbaut" 1 "nicht_verfügbar (Fehler oder Init)" 2 "nicht_gesteckt" 3 "gesteckt" ;
VAL_ 2527679722 AB_Gurtschloss_Reihe4_MI 0 "nicht_verbaut" 1 "nicht_verfügbar (Fehler oder Init)" 2 "nicht_gesteckt" 3 "gesteckt" ;
VAL_ 2527679722 AB_wSBR_Batteriestatus 0 "Batterien_OK" 1 "mindestens_eine_Batterie_schwach" ;
VAL_ 2527679722 AB_Gurtwarn_VM 0 "keine_Warnung" 1 "Gurtwarnung_ausloesen" ;
VAL_ 2527679722 AB_Gurtschloss_MI 0 "nicht_verbaut" 1 "nicht_verfügbar (Fehler oder Init)" 2 "nicht_gesteckt" 3 "gesteckt" ;
VAL_ 2527679722 AB_Anzeige_Komfort_HBFS 0 "keine_Statusanzeige" 1 "Anzeige_Lehne_ein" 2 "Anzeige_SNV_ein" 3 "Anzeige_Lehne_UND_SNV_ein" ;
VAL_ 2527679722 AB_Anzeige_Komfort_HFS 0 "keine_Statusanzeige" 1 "Anzeige_Lehne_ein" 2 "Anzeige_SNV_ein" 3 "Anzeige_Lehne_UND_SNV_ein" ;
VAL_ 2527679722 AB_Anzeige_Sitz_Komfort_HBFS 0 "keine_Statusanzeige" 1 "Anzeige_Lehne_ein" 2 "Anzeige_SNV_ein" 3 "Anzeige_Lehne_UND_SNV_ein" ;
VAL_ 2527679722 AB_Anzeige_Sitz_Komfort_HFS 0 "keine_Statusanzeige" 1 "Anzeige_Lehne_ein" 2 "Anzeige_SNV_ein" 3 "Anzeige_Lehne_UND_SNV_ein" ;
VAL_ 2527679722 AB_Status_Sitz_SRAB_HBFS 0 "Einschaltung_SRAB" 1 "Abschaltung_SRAB" 2 "Init" 3 "Fehler" ;
VAL_ 2527679722 AB_Status_Sitz_SRAB_HFS 0 "Einschaltung_SRAB" 1 "Abschaltung_SRAB" 2 "Init" 3 "Fehler" ;
VAL_ 2527679722 AB_Anzeige_Kombi_SRAB 0 "keine_Statusanzeige" 1 "HFS_EIN_HFBS_EIN" 2 "HFS_AUS_HFBS_AUS" 3 "HFS_EIN_HFBS_AUS" 4 "HFS_AUS_HFBS_EIN" ;
VAL_ 280 ALR_Sta_Laengssperre 0 "Sperre_im_Regelmodus" 1 "Sperre_vom_Fahrer_aktiviert" 2 "Fehler_Sperre_offen" 3 "Fehler_Sperre_zu" ;
VAL_ 280 ALR_Sendestatus 0 "Allrad_sendet_mit_100ms" 1 "Allrad_sendet_mit_10ms" ;
VAL_ 280 ALR_Warnlampe 0 "keine_Warnung" 1 "Warnung" ;
VAL_ 280 ALR_Ist_Proz 253 "Fehler_und_Kupplung_geschlossen" 254 "Init" 255 "Fehler" ;
VAL_ 280 ALR_Charisma_FahrPr 0 "keine_Funktion" 1 "Programm_1" 2 "Programm_2" 3 "Programm_3" 4 "Programm_4" 5 "Programm_5" 6 "Programm_6" 7 "Programm_7" 8 "Programm_8" 9 "Programm_9" 10 "Programm_10" 11 "Programm_11" 12 "Programm_12" 13 "Programm_13" 14 "Programm_14" 15 "Programm_15" ;
VAL_ 280 ALR_Charisma_Status 0 "Init" 1 "verfuegbar" 2 "nicht_verfuegbar" 3 "asynchron_durch_Fahrerwunsch" ;
VAL_ 308 ALR_gMeter_ax 1022 "Init" 1023 "Fehler" ;
VAL_ 308 ALR_gMeter_ay 1022 "Init" 1023 "Fehler" ;
VAL_ 1633 AAG_AVS_Fehler_02_inv 0 "Fehler" 1 "kein_Fehler" ;
VAL_ 1633 AAG_Bremsl_durch_ECD 0 "Bremslicht_ist_aus" 1 "Bremslicht_durch_ECD_aktiv" ;
VAL_ 1633 AAG_Anhaenger_abgesteckt 1 "Anhaenger_wurde_bei_KL15_aus_abgesteckt" ;
VAL_ 1633 AAG_NSL_aktiv 0 "Init" 1 "Anhaenger_Nebelschusslicht_aktiv" ;
VAL_ 1633 AAG_Anhaenger_erkannt 0 "kein_Anhaenger_erkannt" 1 "AAG_Anhaenger_erkannt" ;
VAL_ 1633 AAG_Blinker_H_aktiv 0 "Init" 1 "Anhaenger_Blinker_aktiv" ;
VAL_ 1633 AAG_Blinker_HL_def 0 "Init" 1 "Anhaenger_Blinker_links_defekt" ;
VAL_ 1633 AAG_Blinker_HR_def 0 "Init" 1 "Anhaenger_Blinker_rechts_defekt" ;
VAL_ 1633 AAG_Bremslicht_H_def 0 "Init" 1 "Anhaenger_Bremslicht_defekt" ;
VAL_ 1633 AAG_Schlusslicht_HL_def 0 "Init" 1 "Anhaenger_Schlusslicht_links_defekt" ;
VAL_ 1633 AAG_Schlusslicht_HR_def 0 "Init" 1 "Anhaenger_Schlusslicht_rechts_defekt" ;
VAL_ 1633 AAG_Bremslicht_Reku 0 "inaktiv" 1 "aktiv" ;
VAL_ 1633 AAG_AVS_Fehler_02 0 "kein_Fehler" 1 "Fehler" ;
VAL_ 1633 AAG_LED_aktiv 0 "Lampen" 1 "LED" ;
VAL_ 1633 AAG_AVS_Stati 0 "endlage_eingefahren_erreicht" 1 "endlage_ausgefahren_erreicht" 2 "ausfahren_automatik" 3 "einfahren_automatik" 4 "ausfahren_manuell" 5 "einfahren_manuell" 6 "zwischenposition" 7 "nicht_initialisiert" ;
VAL_ 345 ARA_Knickwinkel_Konfidenz 126 "Init" 127 "Fehler" ;
VAL_ 345 ARA_Texte 0 "kein Text/Akustik" 63 "Fehler" ;
VAL_ 345 ARA_Modus 0 "Knickwinkelmodus" 1 "Trajektorienmodus" ;
VAL_ 345 ARA_Aktiver_Grafikmodus 0 "keine_Grafik" 1 "Grafikmodus_aktiv" ;
VAL_ 345 ARA_Deaktivierung_sperren 0 "nicht_gesperrt" 1 "gesperrt" ;
VAL_ 345 ARA_Modus_Anf 0 "ARA Modus nicht im TSG angefordert" 1 "ARA Modus im TSG angefordert" ;
VAL_ 345 ARA_Bremsfuss 0 "kein Bremsfuss" 1 "Bremsfuss angefordert" ;
VAL_ 345 ARA_Sensor_Aktivierung 0 "Knickwinkelsensor_deaktivieren" 1 "Knickwinkelsensor_aktivieren" ;
VAL_ 345 ARA_Knickwinkel_Komfort 62 "Init" 63 "Fehler" ;
VAL_ 345 ARA_Status 0 "ARA_Status_inaktiv" 1 "ARA_Status_init" 2 "Fehler" 3 "ARA_Status_Start" 4 "ARA_Status_aktiv" 6 "ARA_Status_Regelung_aktiv" 8 "ARA_Status_betriebsbereit" 9 "ARA_Status_Klemmtraeger_erkannt" 10 "ARA_Status_Abbruch" 11 "ARA_Status_nicht_betriebsbereit" ;
VAL_ 345 ARA_Knickwinkel_Max 126 "Init" 127 "Fehler" ;
VAL_ 345 ARA_Knickwinkel_Soll 254 "Init" 255 "Fehler" ;
VAL_ 345 ARA_Knickwinkel_Ist 254 "Init" 255 "Fehler" ;
VAL_ 893 ASTA_Stuetzlast 510 "Init" 511 "Fehler" ;
VAL_ 893 ASTA_Einheit 0 "kg" 1 "lbs" 2 "reserviert" 3 "Fehler" ;
VAL_ 893 ASTA_Anhaengerlast 8190 "Init" 8191 "Fehler" ;
VAL_ 893 AAG_ASTA_Status 0 "kein_Fehler" 1 "Fehler" ;
VAL_ 893 ASTAs_01_upd 0 "nicht_aktuell" 1 "aktuell" ;
VAL_ 893 ASTAs_01_alt 0 "aktuell" 1 "veraltet" ;
VAL_ 2527679661 WBA_Warnblinken 0 "kein_Blinken" 1 "Warnblinken" 2 "Warnblinken_Taster" ;
VAL_ 2527679661 AWV_KA_Konfiguration 0 "Ausgeschaltet" 1 "Eingeschaltet" ;
VAL_ 2527679661 AWV_Warnung 0 "keine_Anzeige" 1 "latente_Vorwarnung" 2 "Vorwarnung" 3 "AWU_ohne_Ton_oder_Akutwarnung" 4 "Eingriff" 5 "Fahreruebernahmeaufforderung" 6 "AWU_mit_Ton" 7 "Querinfo_2" ;
VAL_ 2527679661 AWV_Texte_02 0 "keine_Anzeige" 1 "Systemstoerung" 2 "keine_Sensorsicht" 3 "Initialisierung_gelb" 4 "System_aus" 5 "Initialisierung" 6 "Sensorfusion_eingeschraenkt" 7 "zurzeit_eingeschraenkt" ;
VAL_ 2527679661 AWV_Warnlevel 0 "keine_Gefaehrdung" 63 "max_Gefaehrdung" ;
VAL_ 2527679661 AWV_Einstellung_System_FSG 0 "deaktiviert" 1 "aktiviert" ;
VAL_ 2527679661 AWV_Einstellung_Warnung_FSG 0 "Aus" 1 "Setting_2" 2 "Setting_3" 3 "Setting_4" 4 "Setting_5" 5 "Ein" ;
VAL_ 2527679661 AWV_Status_Anzeige 0 "Init" 1 "verfuegbar" 2 "nicht_verfuegbar" ;
VAL_ 2527679661 AWV_LED_Leiste 0 "keine_Anzeige" 1 "Stufe_1_glimmen" 2 "Stufe_2_leuchten" 3 "nicht_definiert" ;
VAL_ 2527679661 AWV_Priowarnung 0 "HCA_Warnung_nicht_unterdruecken" 1 "HCA_Warnung_unterdruecken" ;
VAL_ 2527679661 AWV_AW_Abstand 509 "Freifahrt" 510 "nicht_definiert" 511 "Keine_Anzeige" ;
VAL_ 2527679661 AWV_AW_Zeitluecke 0 "keine_Anzeige" 1 "Zeitluecke_1" 2 "Zeitluecke_2" 3 "Zeitluecke_3" ;
VAL_ 2527679661 AWV_AW_Texte 0 "Keine_Anzeige" 1 "Systemstoerung" 2 "keine_Sensorsicht" 3 "zurzeit_eingeschraenkt" ;
VAL_ 2527679661 AWV_AW_Texte_Zusatzanzeige 0 "keine_Anzeige" 1 "Abstandsanzeige" 2 "AW_Warnschwelle_1" 3 "AW_Warnschwelle_2" 4 "AW_Warnschwelle_3" 5 "AW_Warnung_1" 6 "AW_Warnung_2" 7 "AW_Warnung_3" ;
VAL_ 2527679661 AWV_KA_ObjektFront 0 "kein_Hindernis" 1 "Hindernis_erkannt" ;
VAL_ 2527679661 AWV_Warnung_Richtung 0 "keine_Richtung" 1 "Links" 2 "Mitte" 3 "Rechts" 4 "Links_und_Rechts" ;
VAL_ 2527679661 AWV_Kamera_Objekt_ID 0 "Kein_Kameraobjekt" ;
VAL_ 2463978752 AZK_Kessy_defekt 0 "keine_Anzeige" 1 "Anzeige" ;
VAL_ 2463978752 AZK_Kessy_nicht_gefunden 0 "keine_Anzeige" 1 "Anzeige" ;
VAL_ 2463978752 AZK_MobileKey_defekt 0 "keine_Anzeige" 1 "Anzeige" ;
VAL_ 2463978752 AZK_Mobilgeraet_nicht_gefunden 0 "keine_Anzeige" 1 "Anzeige" ;
VAL_ 2463978752 AZK_Schluessel_im_Fzg 0 "keine_Anzeige" 1 "Anzeige" ;
VAL_ 2463978752 AZK_Weiterfahrt_mit_Mobilgeraet 0 "keine_Anzeige" 1 "Anzeige" ;
VAL_ 2463978752 AZK_Weiterfahrt_mit_Schluessel 0 "keine_Anzeige" 1 "Anzeige" ;
VAL_ 2463978752 AZK_Schluessel_nicht_gefunden 0 "keine_Anzeige" 1 "Anzeige" ;
